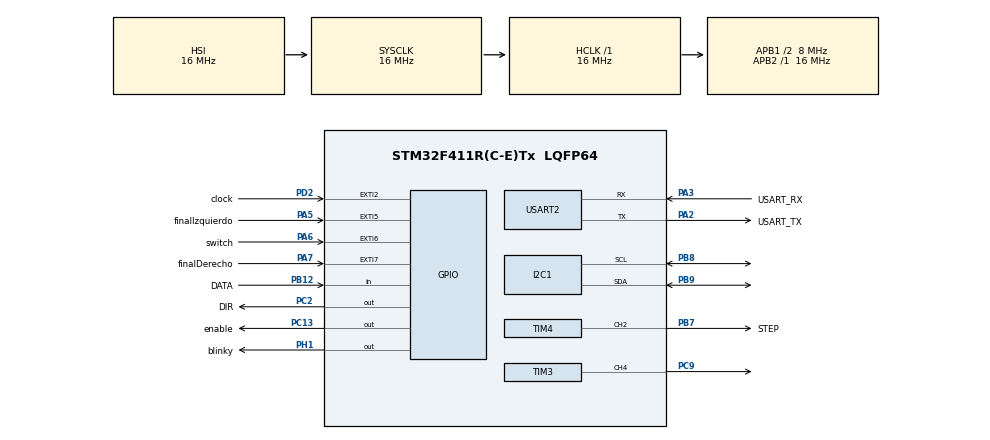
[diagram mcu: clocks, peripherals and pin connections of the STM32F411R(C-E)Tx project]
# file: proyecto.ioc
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I2C1.DutyCycle=I2C_DUTYCYCLE_16_9
I2C1.I2C_Mode=I2C_Fast
Mcu.Family=STM32F4
Mcu.Name=STM32F411R(C-E)Tx
Mcu.Package=LQFP64
NVIC.EXTI2_IRQn=true\:0\:0\:false\:false\:true\:true\:true\:true
NVIC.EXTI9_5_IRQn=true\:0\:0\:false\:false\:true\:true\:true\:true
NVIC.PriorityGroup=NVIC_PRIORITYGROUP_0
NVIC.TIM1_BRK_TIM9_IRQn=true\:0\:0\:false\:false\:true\:true\:true\:true
NVIC.TIM2_IRQn=true\:0\:0\:false\:false\:true\:true\:true\:true
NVIC.TIM3_IRQn=true\:0\:0\:false\:false\:true\:true\:true\:true
NVIC.TIM5_IRQn=true\:0\:0\:false\:false\:true\:true\:true\:true
NVIC.USART2_IRQn=true\:0\:0\:false\:false\:true\:true\:true\:true
PA13.GPIO_Label=TMS
PA13.Mode=Serial_Wire
PA13.Signal=SYS_JTMS-SWDIO
PA14.GPIO_Label=TCK
PA14.Mode=Serial_Wire
PA14.Signal=SYS_JTCK-SWCLK
PA2.GPIO_Label=USART_TX
PA2.Mode=Asynchronous
PA2.Signal=USART2_TX
PA3.GPIO_Label=USART_RX
PA3.Mode=Asynchronous
PA3.Signal=USART2_RX
PA5.GPIO_Label=finalIzquierdo
PA5.Signal=GPXTI5
PA6.GPIO_Label=switch
PA6.Signal=GPXTI6
PA7.GPIO_Label=finalDerecho
PA7.Signal=GPXTI7
PB12.GPIO_Label=DATA
PB12.Signal=GPIO_Input
PB3.GPIO_Label=SWO
PB3.Signal=SYS_JTDO-SWO
PB7.GPIO_Label=STEP
PB7.Signal=S_TIM4_CH2
PB8.Mode=I2C
PB8.Signal=I2C1_SCL
PB9.Mode=I2C
PB9.Signal=I2C1_SDA
PC13-ANTI_TAMP.GPIO_Label=enable
PC13-ANTI_TAMP.Signal=GPIO_Output
PC2.GPIO_Label=DIR
PC2.Signal=GPIO_Output
PC9.Signal=S_TIM3_CH4
PD2.GPIO_Label=clock
PD2.Signal=GPXTI2
PH1\ -\ OSC_OUT.GPIO_Label=blinky
PH1\ -\ OSC_OUT.Signal=GPIO_Output
ProjectManager.HeapSize=0x200
ProjectManager.StackSize=0x400
ProjectManager.TargetToolchain=STM32CubeIDE
RCC.48MHZClocksFreq_Value=84000000
RCC.AHBFreq_Value=16000000
RCC.APB1CLKDivider=RCC_HCLK_DIV2
RCC.APB1Freq_Value=8000000
RCC.APB1TimFreq_Value=16000000
RCC.APB2Freq_Value=16000000
RCC.APB2TimFreq_Value=16000000
RCC.CortexFreq_Value=16000000
RCC.FLatency-AdvancedSettings=FLASH_LATENCY_0
RCC.HCLKFreq_Value=16000000
RCC.HSE_VALUE=8000000
RCC.HSI_VALUE=16000000
RCC.LSE_VALUE=32768
RCC.PLLN=336
RCC.PLLP=RCC_PLLP_DIV4
RCC.SYSCLKFreq_VALUE=16000000
RCC.VCOOutputFreq_Value=336000000
SH.S_TIM3_CH4.0=TIM3_CH4,PWM Generation4 CH4
SH.S_TIM4_CH2.0=TIM4_CH2,PWM Generation2 CH2
TIM10.Period=800
TIM10.Prescaler=16000
TIM2.Period=250-1
TIM2.Prescaler=16000-1
TIM3.Channel-PWM\ Generation4\ CH4=TIM_CHANNEL_4
TIM3.Period=8000
TIM3.Prescaler=10000-1
TIM4.Channel-PWM\ Generation2\ CH2=TIM_CHANNEL_2
TIM4.Period=100
TIM4.Prescaler=1600
TIM4.Pulse-PWM\ Generation2\ CH2=10
TIM5.Period=8000
TIM5.Prescaler=10000-1
TIM9.Period=8000
TIM9.Prescaler=10000-1
USART2.VirtualMode=VM_ASYNC
VP_TIM10_VS_ClockSourceINT.Mode=Enable_Timer
VP_TIM2_VS_ClockSourceINT.Mode=Internal
VP_TIM3_VS_ClockSourceINT.Mode=Internal
VP_TIM4_VS_ClockSourceINT.Mode=Internal
VP_TIM5_VS_ClockSourceINT.Mode=Internal
VP_TIM9_VS_ClockSourceINT.Mode=Internal
board=NUCLEO-F411RE

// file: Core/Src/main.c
/* USER CODE BEGIN Header */
/**
  ******************************************************************************
  * @file           : main.c
  * @brief          : Main program body
  ******************************************************************************
  * @attention
  *
  * Copyright (c) 2025 STMicroelectronics.
  * All rights reserved.
  *
  * This software is licensed under terms that can be found in the LICENSE file
  * in the root directory of this software component.
  * If no LICENSE file comes with this software, it is provided AS-IS.
  *
  ******************************************************************************
  */
/* USER CODE END Header */
#include "main.h"

I2C_HandleTypeDef hi2c1;

TIM_HandleTypeDef htim2;
TIM_HandleTypeDef htim3;
TIM_HandleTypeDef htim4;
TIM_HandleTypeDef htim5;
TIM_HandleTypeDef htim9;
TIM_HandleTypeDef htim10;

UART_HandleTypeDef huart2;

/* USER CODE BEGIN PV */
//Inicializamos la variable a la cual vamos a gurdarle el estado que
//tiene la maquina
estadoActual fsm ={0};

//Variables del posible estado para los finales de carrera
uint8_t estadoIzquierdo =0;
uint8_t estadoDerecho =0;

//Creamos los formatos para las expresiones
//Carita "delado"
const unsigned char delado [] = {
	0xff, 0xff, 0xff, 0xff, 0xff, 0xff, 0xff, 0xff, 0xff, 0xff, 0xff, 0xff, 0xff, 0xff, 0xff, 0xff,
	0xff, 0xff, 0xff, 0xff, 0xff, 0xff, 0xff, 0xff, 0xff, 0xff, 0xff, 0xff, 0xff, 0xff, 0xff, 0xff,
	0xff, 0xff, 0xff, 0xff, 0xff, 0xff, 0xff, 0xff, 0xff, 0xff, 0xff, 0xff, 0xff, 0xff, 0xff, 0xff,
	0xff, 0xff, 0xff, 0xff, 0xff, 0xff, 0xff, 0xff, 0xff, 0xff, 0xff, 0xff, 0xff, 0xff, 0xff, 0xff,
	0xff, 0xff, 0xff, 0xff, 0xff, 0xff, 0xff, 0xff, 0xff, 0xff, 0xff, 0xff, 0xff, 0xff, 0xff, 0xff,
	0xff, 0xff, 0xff, 0xff, 0xff, 0xfe, 0x01, 0xff, 0xf8, 0x03, 0xff, 0xff, 0xff, 0xff, 0xff, 0xff,
	0xff, 0xff, 0xff, 0xff, 0xff, 0xf0, 0xf9, 0xff, 0xfb, 0xf8, 0xff, 0xff, 0xff, 0xff, 0xff, 0xff,
	0xff, 0xff, 0xff, 0xff, 0xff, 0xef, 0xff, 0xff, 0xff, 0xff, 0x7f, 0xff, 0xff, 0xff, 0xff, 0xff,
	0xff, 0xff, 0xff, 0xff, 0xff, 0xdf, 0xff, 0xff, 0xff, 0xff, 0xbf, 0xff, 0xff, 0xff, 0xff, 0xff,
	0xff, 0xff, 0xff, 0xff, 0xff, 0xff, 0xff, 0xff, 0xff, 0xff, 0xff, 0xff, 0xff, 0xff, 0xff, 0xff,
	0xff, 0xff, 0xff, 0xff, 0xff, 0xff, 0xff, 0xff, 0xff, 0xff, 0xff, 0xff, 0xff, 0xff, 0xff, 0xff,
	0xff, 0xff, 0xff, 0xff, 0xff, 0xff, 0xff, 0xff, 0xff, 0xff, 0xff, 0xff, 0xff, 0xff, 0xff, 0xff,
	0xff, 0xff, 0xff, 0xff, 0xff, 0xff, 0xff, 0xff, 0xff, 0xff, 0xff, 0xff, 0xff, 0xff, 0xff, 0xff,
	0xff, 0xff, 0xff, 0xff, 0xff, 0xff, 0xff, 0xff, 0xff, 0xff, 0xff, 0xff, 0xff, 0xff, 0xff, 0xff,
	0xff, 0xff, 0xff, 0xff, 0xff, 0xff, 0xff, 0xff, 0xff, 0xff, 0xff, 0xff, 0xff, 0xff, 0xff, 0xff,
	0xff, 0xff, 0xff, 0xff, 0xff, 0xff, 0xff, 0xff, 0xff, 0xfd, 0xff, 0xff, 0xff, 0xff, 0xff, 0xff,
	0xff, 0xff, 0xff, 0xff, 0xff, 0xef, 0xff, 0xff, 0xff, 0xfe, 0xff, 0xff, 0xff, 0xff, 0xff, 0xff,
	0xff, 0xff, 0xff, 0xff, 0xff, 0xdf, 0xff, 0x7f, 0xff, 0xff, 0x7f, 0xff, 0xff, 0xff, 0xff, 0xff,
	0xff, 0xff, 0xff, 0xff, 0xff, 0x87, 0xff, 0xff, 0xdf, 0xff, 0xbf, 0xff, 0xff, 0xff, 0xff, 0xff,
	0xff, 0xff, 0xff, 0xff, 0xff, 0x81, 0xff, 0xbf, 0x80, 0xff, 0xdf, 0xff, 0xff, 0xff, 0xff, 0xff,
	0xff, 0xff, 0xff, 0xff, 0xff, 0x00, 0xff, 0xff, 0x80, 0x7f, 0xff, 0xff, 0xff, 0xff, 0xff, 0xff,
	0xff, 0xff, 0xff, 0xff, 0xff, 0x07, 0xff, 0xdf, 0x81, 0xff, 0xef, 0xff, 0xff, 0xff, 0xff, 0xff,
	0xff, 0xff, 0xff, 0xff, 0xfe, 0x07, 0x7f, 0xdf, 0x03, 0xff, 0xef, 0xff, 0xff, 0xff, 0xff, 0xff,
	0xff, 0xff, 0xff, 0xff, 0xfe, 0x07, 0x7f, 0xff, 0x03, 0xdf, 0xf7, 0xff, 0xff, 0xff, 0xff, 0xff,
	0xff, 0xff, 0xff, 0xff, 0xfc, 0x02, 0x3f, 0xff, 0x01, 0x9f, 0xf7, 0xff, 0xff, 0xff, 0xff, 0xff,
	0xff, 0xff, 0xff, 0xff, 0xfc, 0x00, 0x3f, 0xff, 0x00, 0x1f, 0xff, 0xff, 0xff, 0xff, 0xff, 0xff,
	0xff, 0xff, 0xff, 0xff, 0xfc, 0x00, 0x3f, 0xef, 0x00, 0x1f, 0xff, 0xff, 0xff, 0xff, 0xff, 0xff,
	0xff, 0xff, 0xff, 0xff, 0xfc, 0x00, 0x3f, 0xff, 0x00, 0x1f, 0xff, 0xff, 0xff, 0xff, 0xff, 0xff,
	0xff, 0xff, 0xff, 0xff, 0xfc, 0x00, 0x3f, 0xff, 0x00, 0x1f, 0xfb, 0xff, 0xff, 0xff, 0xff, 0xff,
	0xff, 0xff, 0xff, 0xff, 0xfc, 0x00, 0x7f, 0xff, 0x00, 0x1f, 0xfb, 0xff, 0xff, 0xff, 0xff, 0xff,
	0xff, 0xff, 0xff, 0xff, 0xfc, 0x00, 0x7f, 0xdf, 0x00, 0x3f, 0xfb, 0xff, 0xff, 0xff, 0xff, 0xff,
	0xff, 0xff, 0xff, 0xff, 0xfc, 0x00, 0xff, 0xdf, 0x00, 0x3f, 0xff, 0xff, 0xff, 0xff, 0xff, 0xff,
	0xff, 0xff, 0xff, 0xff, 0xfc, 0x01, 0xff, 0xdf, 0x80, 0x7f, 0xf7, 0xff, 0xff, 0xff, 0xff, 0xff,
	0xff, 0xff, 0xff, 0xff, 0xfd, 0x83, 0xff, 0xbf, 0x80, 0xff, 0xf7, 0xff, 0xff, 0xff, 0xff, 0xff,
	0xff, 0xff, 0xff, 0xff, 0xfe, 0xff, 0xff, 0xbf, 0xdf, 0xff, 0xf7, 0xff, 0xff, 0xff, 0xff, 0xff,
	0xff, 0xff, 0xff, 0xff, 0xfe, 0xff, 0xff, 0x7f, 0xdf, 0xff, 0xef, 0xff, 0xff, 0xff, 0xff, 0xff,
	0xff, 0xff, 0xff, 0xff, 0xff, 0x7f, 0xff, 0x7f, 0xef, 0xff, 0xef, 0xff, 0xff, 0xff, 0xff, 0xff,
	0xff, 0xff, 0xff, 0xff, 0xff, 0x3f, 0xfe, 0xff, 0xf7, 0xff, 0xdf, 0xff, 0xff, 0xff, 0xff, 0xff,
	0xff, 0xff, 0xff, 0xff, 0xff, 0x9f, 0xf9, 0xff, 0xfb, 0xff, 0xbf, 0xff, 0xff, 0xff, 0xff, 0xff,
	0xff, 0xff, 0xff, 0xff, 0xff, 0xcf, 0xf3, 0xff, 0xfd, 0xff, 0x7f, 0xff, 0xff, 0xff, 0xff, 0xff,
	0xff, 0xff, 0xff, 0xff, 0xff, 0xf1, 0x8f, 0xff, 0xfe, 0x38, 0xff, 0xff, 0xff, 0xff, 0xff, 0xff,
	0xff, 0xff, 0xff, 0xff, 0xff, 0xfe, 0x7f, 0xff, 0xff, 0xc7, 0xff, 0xff, 0xff, 0xff, 0xff, 0xff,
	0xff, 0xff, 0xff, 0xff, 0xff, 0xff, 0xff, 0xff, 0xff, 0xff, 0xff, 0xff, 0xff, 0xff, 0xff, 0xff,
	0xff, 0xff, 0xff, 0xff, 0xff, 0xff, 0x7f, 0xff, 0xff, 0xff, 0xff, 0xff, 0xff, 0xff, 0xff, 0xff,
	0xff, 0xff, 0xff, 0xff, 0xff, 0xff, 0x1f, 0xff, 0xff, 0xff, 0xff, 0xff, 0xff, 0xff, 0xff, 0xff,
	0xff, 0xff, 0xff, 0xff, 0xff, 0xff, 0x77, 0xff, 0xff, 0xff, 0xff, 0xff, 0xff, 0xff, 0xff, 0xff,
	0xff, 0xff, 0xff, 0xff, 0xff, 0xff, 0x7c, 0xff, 0xff, 0xff, 0xff, 0xff, 0xff, 0xff, 0xff, 0xff,
	0xff, 0xff, 0xff, 0xff, 0xff, 0xff, 0xff, 0xc0, 0x40, 0x3f, 0xff, 0xff, 0xff, 0xff, 0xff, 0xff,
	0xff, 0xff, 0xff, 0xff, 0xff, 0xff, 0xbf, 0xff, 0xff, 0xff, 0xff, 0xff, 0xff, 0xff, 0xff, 0xff,
	0xff, 0xff, 0xff, 0xff, 0xff, 0xff, 0xbf, 0xff, 0xff, 0x7f, 0xff, 0xff, 0xff, 0xff, 0xff, 0xff,
	0xff, 0xff, 0xff, 0xff, 0xff, 0xff, 0x8f, 0xff, 0xff, 0xff, 0xff, 0xff, 0xff, 0xff, 0xff, 0xff,
	0xff, 0xff, 0xff, 0xff, 0xff, 0xff, 0xdf, 0xff, 0xfe, 0xff, 0xff, 0xff, 0xff, 0xff, 0xff, 0xff,
	0xff, 0xff, 0xff, 0xff, 0xff, 0xff, 0xdf, 0xff, 0xf9, 0xff, 0xff, 0xff, 0xff, 0xff, 0xff, 0xff,
	0xff, 0xff, 0xff, 0xff, 0xff, 0xff, 0xef, 0xff, 0xfb, 0xff, 0xff, 0xff, 0xff, 0xff, 0xff, 0xff,
	0xff, 0xff, 0xff, 0xff, 0xff, 0xff, 0xff, 0xff, 0xf7, 0xff, 0xff, 0xff, 0xff, 0xff, 0xff, 0xff,
	0xff, 0xff, 0xff, 0xff, 0xff, 0xff, 0xfb, 0xff, 0xef, 0xff, 0xff, 0xff, 0xff, 0xff, 0xff, 0xff,
	0xff, 0xff, 0xff, 0xff, 0xff, 0xff, 0xfd, 0xff, 0xdf, 0xff, 0xff, 0xff, 0xff, 0xff, 0xff, 0xff,
	0xff, 0xff, 0xff, 0xff, 0xff, 0xff, 0xfe, 0x7e, 0x7f, 0xff, 0xff, 0xff, 0xff, 0xff, 0xff, 0xff,
	0xff, 0xff, 0xff, 0xff, 0xff, 0xff, 0xff, 0xe3, 0xff, 0xff, 0xff, 0xff, 0xff, 0xff, 0xff, 0xff,
	0xff, 0xff, 0xff, 0xff, 0xff, 0xff, 0xff, 0xff, 0xff, 0xff, 0xff, 0xff, 0xff, 0xff, 0xff, 0xff,
	0xff, 0xff, 0xff, 0xff, 0xff, 0xff, 0xff, 0xff, 0xff, 0xff, 0xff, 0xff, 0xff, 0xff, 0xff, 0xff,
	0xff, 0xff, 0xff, 0xff, 0xff, 0xff, 0xff, 0xff, 0xff, 0xff, 0xff, 0xff, 0xff, 0xff, 0xff, 0xff,
	0xff, 0xff, 0xff, 0xff, 0xff, 0xff, 0xff, 0xff, 0xff, 0xff, 0xff, 0xff, 0xff, 0xff, 0xff, 0xff,
	0xff, 0xff, 0xff, 0xff, 0xff, 0xff, 0xff, 0xff, 0xff, 0xff, 0xff, 0xff, 0xff, 0xff, 0xff, 0xff
};

//Carita "enamoradisimo"
const unsigned char enamoradisimo [] = {
	0xff, 0xff, 0xff, 0xff, 0xff, 0xff, 0xff, 0xff, 0xff, 0xff, 0xff, 0xff, 0xff, 0xff, 0xff, 0xff,
	0xff, 0xff, 0xff, 0xff, 0xff, 0xff, 0xf8, 0x7f, 0xe1, 0xff, 0xff, 0xff, 0xff, 0xff, 0xff, 0xff,
	0xff, 0xff, 0xff, 0xff, 0xff, 0xff, 0xe0, 0x7f, 0xe0, 0x7f, 0xff, 0xff, 0xff, 0xff, 0xff, 0xff,
	0xff, 0xff, 0xff, 0xff, 0xff, 0xff, 0xc1, 0xff, 0xf8, 0x3f, 0xff, 0xff, 0xff, 0xff, 0xff, 0xff,
	0xff, 0xff, 0xff, 0xff, 0xff, 0xff, 0x87, 0xff, 0xfe, 0x0f, 0xff, 0xff, 0xff, 0xff, 0xff, 0xff,
	0xff, 0xff, 0xff, 0xff, 0xff, 0xfe, 0x1f, 0xff, 0xff, 0x87, 0xff, 0xff, 0xff, 0xff, 0xff, 0xff,
	0xff, 0xff, 0xff, 0xff, 0xff, 0xfc, 0x3f, 0xff, 0xff, 0xc3, 0xff, 0xff, 0xff, 0xff, 0xff, 0xff,
	0xff, 0xff, 0xff, 0xff, 0xff, 0xfc, 0xff, 0xff, 0xff, 0xf3, 0xff, 0xff, 0xff, 0xff, 0xff, 0xff,
	0xff, 0xff, 0xff, 0xff, 0xff, 0xf9, 0xff, 0xff, 0xff, 0xfd, 0xff, 0xff, 0xff, 0xff, 0xff, 0xff,
	0xff, 0xff, 0xff, 0xff, 0xff, 0xf7, 0xff, 0xff, 0xff, 0xfe, 0xff, 0xff, 0xff, 0xff, 0xff, 0xff,
	0xff, 0xff, 0xff, 0xff, 0xff, 0xff, 0xff, 0xff, 0xff, 0xff, 0xff, 0xff, 0xff, 0xff, 0xff, 0xff,
	0xff, 0xff, 0xff, 0xff, 0xff, 0xff, 0xff, 0xff, 0xff, 0xff, 0xff, 0xff, 0xff, 0xff, 0xff, 0xff,
	0xff, 0xff, 0xff, 0xff, 0xff, 0xfc, 0x0f, 0xff, 0xff, 0xff, 0xff, 0xff, 0xff, 0xff, 0xff, 0xff,
	0xff, 0xff, 0xff, 0xff, 0xff, 0xef, 0xfb, 0xff, 0xff, 0xff, 0xff, 0xff, 0xff, 0xff, 0xff, 0xff,
	0xff, 0xff, 0xff, 0xff, 0xff, 0xdf, 0xfe, 0xff, 0xfd, 0xf9, 0xff, 0xff, 0xff, 0xff, 0xff, 0xff,
	0xff, 0xff, 0xff, 0xff, 0xff, 0xff, 0xff, 0x7f, 0xf7, 0xfe, 0xff, 0xff, 0xff, 0xff, 0xff, 0xff,
	0xff, 0xff, 0xff, 0xff, 0xff, 0xff, 0xff, 0xbf, 0xef, 0xff, 0xbf, 0xff, 0xff, 0xff, 0xff, 0xff,
	0xff, 0xff, 0xff, 0xff, 0xfe, 0xff, 0xff, 0xdf, 0xdf, 0xff, 0xff, 0xff, 0xff, 0xff, 0xff, 0xff,
	0xff, 0xff, 0xff, 0xff, 0xff, 0xe1, 0xc3, 0xdf, 0xff, 0xff, 0xff, 0xff, 0xff, 0xff, 0xff, 0xff,
	0xff, 0xff, 0xff, 0xff, 0xfd, 0xc0, 0x81, 0xff, 0xb8, 0x70, 0xef, 0xff, 0xff, 0xff, 0xff, 0xff,
	0xff, 0xff, 0xff, 0xff, 0xff, 0x80, 0x00, 0xef, 0xf0, 0x00, 0x7f, 0xff, 0xff, 0xff, 0xff, 0xff,
	0xff, 0xff, 0xff, 0xff, 0xff, 0x80, 0x00, 0xff, 0x60, 0x00, 0x7f, 0xff, 0xff, 0xff, 0xff, 0xff,
	0xff, 0xff, 0xff, 0xff, 0xfb, 0x80, 0x00, 0xff, 0x60, 0x00, 0x37, 0xff, 0xff, 0xff, 0xff, 0xff,
	0xff, 0xff, 0xff, 0xff, 0xfb, 0x80, 0x00, 0xff, 0xe0, 0x00, 0x77, 0xff, 0xff, 0xff, 0xff, 0xff,
	0xff, 0xff, 0xff, 0xff, 0xfb, 0xc0, 0x01, 0xff, 0xf0, 0x00, 0x77, 0xff, 0xff, 0xff, 0xff, 0xff,
	0xff, 0xff, 0xff, 0xff, 0xff, 0xc0, 0x01, 0xff, 0xf0, 0x00, 0x77, 0xff, 0xff, 0xff, 0xff, 0xff,
	0xff, 0xff, 0xff, 0xff, 0xff, 0xe0, 0x03, 0xef, 0x78, 0x00, 0xff, 0xff, 0xff, 0xff, 0xff, 0xff,
	0xff, 0xff, 0xff, 0xff, 0xfd, 0xf0, 0x03, 0xff, 0x78, 0x00, 0xff, 0xff, 0xff, 0xff, 0xff, 0xff,
	0xff, 0xff, 0xff, 0xff, 0xff, 0xf0, 0x07, 0xff, 0xfc, 0x01, 0xef, 0xff, 0xff, 0xff, 0xff, 0xff,
	0xff, 0xff, 0xff, 0xff, 0xfe, 0xf8, 0x0f, 0xdf, 0xbe, 0x03, 0xff, 0xff, 0xff, 0xff, 0xff, 0xff,
	0xff, 0xff, 0xff, 0xff, 0xff, 0xfe, 0x1f, 0xbf, 0xdf, 0x07, 0xdf, 0xff, 0xff, 0xff, 0xff, 0xff,
	0xff, 0xff, 0xff, 0xff, 0xff, 0xff, 0x7f, 0x7f, 0xef, 0xdf, 0xbf, 0xff, 0xff, 0xff, 0xff, 0xff,
	0xff, 0xff, 0xff, 0xff, 0xff, 0xdf, 0xfe, 0xff, 0xf7, 0xff, 0x7f, 0xff, 0xff, 0xff, 0xff, 0xff,
	0xff, 0xff, 0xff, 0xff, 0xff, 0xe7, 0xfb, 0xff, 0xfd, 0xfd, 0xff, 0xff, 0xff, 0xff, 0xff, 0xff,
	0xff, 0xff, 0xff, 0xff, 0xff, 0xf8, 0x0f, 0xff, 0xff, 0x8f, 0xff, 0xff, 0xff, 0xff, 0xff, 0xff,
	0xff, 0xff, 0xff, 0xff, 0xff, 0xff, 0xff, 0xff, 0xff, 0xff, 0xff, 0xff, 0xff, 0xff, 0xff, 0xff,
	0xff, 0xff, 0xff, 0xff, 0xff, 0xff, 0xff, 0xff, 0xff, 0xfd, 0xff, 0xff, 0xff, 0xff, 0xff, 0xff,
	0xff, 0xff, 0xff, 0xff, 0xff, 0xe7, 0xff, 0xff, 0xff, 0xfe, 0x7f, 0xff, 0xff, 0xff, 0xff, 0xff,
	0xff, 0xff, 0xff, 0xff, 0xff, 0xf3, 0xff, 0xff, 0xff, 0xf9, 0x7f, 0xff, 0xff, 0xff, 0xff, 0xff,
	0xff, 0xff, 0xff, 0xff, 0xff, 0xf8, 0xff, 0xff, 0xff, 0xe3, 0xff, 0xff, 0xff, 0xff, 0xff, 0xff,
	0xff, 0xff, 0xff, 0xff, 0xff, 0xf8, 0x3f, 0xff, 0xff, 0x03, 0xff, 0xff, 0xff, 0xff, 0xff, 0xff,
	0xff, 0xff, 0xff, 0xff, 0xff, 0xfc, 0x1d, 0xff, 0xf7, 0x07, 0xff, 0xff, 0xff, 0xff, 0xff, 0xff,
	0xff, 0xff, 0xff, 0xff, 0xff, 0xfc, 0x0f, 0xff, 0xfe, 0x07, 0xff, 0xff, 0xff, 0xff, 0xff, 0xff,
	0xff, 0xff, 0xff, 0xff, 0xff, 0xfc, 0x03, 0xff, 0xf0, 0x07, 0xff, 0xff, 0xff, 0xff, 0xff, 0xff,
	0xff, 0xff, 0xff, 0xff, 0xff, 0xfe, 0x00, 0x00, 0x00, 0x0f, 0xff, 0xff, 0xff, 0xff, 0xff, 0xff,
	0xff, 0xff, 0xff, 0xff, 0xff, 0xfe, 0x00, 0x00, 0x00, 0x0f, 0xff, 0xff, 0xff, 0xff, 0xff, 0xff,
	0xff, 0xff, 0xff, 0xff, 0xff, 0xfe, 0x00, 0x00, 0x00, 0x0f, 0xff, 0xff, 0xff, 0xff, 0xff, 0xff,
	0xff, 0xff, 0xff, 0xff, 0xff, 0xff, 0x00, 0x00, 0x00, 0x1f, 0xff, 0xff, 0xff, 0xff, 0xff, 0xff,
	0xff, 0xff, 0xff, 0xff, 0xff, 0xff, 0x00, 0x00, 0x00, 0x1f, 0xff, 0xff, 0xff, 0xff, 0xff, 0xff,
	0xff, 0xff, 0xff, 0xff, 0xff, 0xff, 0x00, 0x00, 0x00, 0x1f, 0xff, 0xff, 0xff, 0xff, 0xff, 0xff,
	0xff, 0xff, 0xff, 0xff, 0xff, 0xff, 0x00, 0x00, 0x00, 0x1f, 0xff, 0xff, 0xff, 0xff, 0xff, 0xff,
	0xff, 0xff, 0xff, 0xff, 0xff, 0xff, 0x80, 0x00, 0x00, 0x1f, 0xff, 0xff, 0xff, 0xff, 0xff, 0xff,
	0xff, 0xff, 0xff, 0xff, 0xff, 0xff, 0x80, 0x00, 0x00, 0x3f, 0xff, 0xff, 0xff, 0xff, 0xff, 0xff,
	0xff, 0xff, 0xff, 0xff, 0xff, 0xff, 0x80, 0x00, 0x00, 0x3f, 0xff, 0xff, 0xff, 0xff, 0xff, 0xff,
	0xff, 0xff, 0xff, 0xff, 0xff, 0xff, 0x80, 0x00, 0x00, 0x3f, 0xff, 0xff, 0xff, 0xff, 0xff, 0xff,
	0xff, 0xff, 0xff, 0xff, 0xff, 0xff, 0xe0, 0x00, 0x00, 0xff, 0xff, 0xff, 0xff, 0xff, 0xff, 0xff,
	0xff, 0xff, 0xff, 0xff, 0xff, 0xff, 0xff, 0x00, 0x0f, 0xff, 0xff, 0xff, 0xff, 0xff, 0xff, 0xff,
	0xff, 0xff, 0xff, 0xff, 0xff, 0xff, 0xff, 0xff, 0xff, 0xff, 0xff, 0xff, 0xff, 0xff, 0xff, 0xff,
	0xff, 0xff, 0xff, 0xff, 0xff, 0xff, 0xff, 0xff, 0xff, 0xff, 0xff, 0xff, 0xff, 0xff, 0xff, 0xff,
	0xff, 0xff, 0xff, 0xff, 0xff, 0xff, 0xff, 0xc0, 0x3f, 0xff, 0xff, 0xff, 0xff, 0xff, 0xff, 0xff,
	0xff, 0xff, 0xff, 0xff, 0xff, 0xff, 0xff, 0xff, 0xff, 0xff, 0xff, 0xff, 0xff, 0xff, 0xff, 0xff,
	0xff, 0xff, 0xff, 0xff, 0xff, 0xff, 0xff, 0xff, 0xff, 0xff, 0xff, 0xff, 0xff, 0xff, 0xff, 0xff,
	0xff, 0xff, 0xff, 0xff, 0xff, 0xff, 0xff, 0xff, 0xff, 0xff, 0xff, 0xff, 0xff, 0xff, 0xff, 0xff,
	0xff, 0xff, 0xff, 0xff, 0xff, 0xff, 0xff, 0xff, 0xff, 0xff, 0xff, 0xff, 0xff, 0xff, 0xff, 0xff
};

//Carita "medio-triste"
const unsigned char medioTriste [] = {
	0xff, 0xff, 0xff, 0xff, 0xff, 0xff, 0xff, 0xff, 0xff, 0xff, 0xff, 0xff, 0xff, 0xff, 0xff, 0xff,
	0xff, 0xff, 0xff, 0xff, 0xff, 0xff, 0xff, 0xff, 0xff, 0xff, 0xff, 0xff, 0xff, 0xff, 0xff, 0xff,
	0xff, 0xff, 0xff, 0xff, 0xff, 0xff, 0xff, 0xff, 0xff, 0xff, 0xff, 0xff, 0xff, 0xff, 0xff, 0xff,
	0xff, 0xff, 0xff, 0xff, 0xff, 0xff, 0xff, 0xff, 0xff, 0xff, 0xff, 0xff, 0xff, 0xff, 0xff, 0xff,
	0xff, 0xff, 0xff, 0xff, 0xff, 0xff, 0xff, 0xff, 0xff, 0xff, 0xff, 0xff, 0xff, 0xff, 0xff, 0xff,
	0xff, 0xff, 0xff, 0xff, 0xff, 0xff, 0xff, 0xff, 0xff, 0xff, 0xff, 0xff, 0xff, 0xff, 0xff, 0xff,
	0xff, 0xff, 0xff, 0xff, 0xff, 0xff, 0xff, 0xff, 0xff, 0xff, 0xff, 0xff, 0xff, 0xff, 0xff, 0xff,
	0xff, 0xff, 0xff, 0xff, 0xff, 0xff, 0xff, 0xff, 0xff, 0xff, 0xff, 0xff, 0xff, 0xff, 0xff, 0xff,
	0xff, 0xff, 0xff, 0xff, 0xff, 0xff, 0xff, 0xff, 0xff, 0xff, 0xff, 0xff, 0xff, 0xff, 0xff, 0xff,
	0xff, 0xff, 0xff, 0xff, 0xff, 0xff, 0xff, 0xff, 0xff, 0xff, 0xff, 0xff, 0xff, 0xff, 0xff, 0xff,
	0xff, 0xff, 0xff, 0xff, 0xe0, 0x7f, 0xff, 0xff, 0xff, 0xff, 0xff, 0x07, 0xff, 0xff, 0xff, 0xff,
	0xff, 0xff, 0xff, 0xff, 0x80, 0x1f, 0xff, 0xff, 0xff, 0xff, 0xfc, 0x01, 0xff, 0xff, 0xff, 0xff,
	0xff, 0xff, 0xff, 0xff, 0x00, 0x0f, 0xff, 0xff, 0xff, 0xff, 0xf0, 0x00, 0xff, 0xff, 0xff, 0xff,
	0xff, 0xff, 0xff, 0xfe, 0x00, 0x07, 0xff, 0xff, 0xff, 0xff, 0xe0, 0x00, 0x3f, 0xff, 0xff, 0xff,
	0xff, 0xff, 0xff, 0xfc, 0x00, 0x03, 0xff, 0xff, 0xff, 0xff, 0xc0, 0x00, 0x3f, 0xff, 0xff, 0xff,
	0xff, 0xff, 0xff, 0xf8, 0x00, 0x01, 0xff, 0xff, 0xff, 0xff, 0xc0, 0x00, 0x1f, 0xff, 0xff, 0xff,
	0xff, 0xff, 0xff, 0xf8, 0x00, 0xc1, 0xff, 0xff, 0xff, 0xff, 0x83, 0x00, 0x0f, 0xff, 0xff, 0xff,
	0xff, 0xff, 0xff, 0xf0, 0x03, 0xf0, 0xff, 0xff, 0xff, 0xff, 0x8f, 0xc0, 0x0f, 0xff, 0xff, 0xff,
	0xff, 0xff, 0xff, 0xf0, 0x07, 0xf8, 0xff, 0xff, 0xff, 0xff, 0x1f, 0xe0, 0x0f, 0xff, 0xff, 0xff,
	0xff, 0xff, 0xff, 0xf0, 0x07, 0xf8, 0xff, 0xff, 0xff, 0xff, 0x1f, 0xe0, 0x07, 0xff, 0xff, 0xff,
	0xff, 0xff, 0xff, 0xe0, 0x0f, 0xfc, 0xff, 0xff, 0xff, 0xff, 0x3f, 0xf0, 0x07, 0xff, 0xff, 0xff,
	0xff, 0xff, 0xff, 0xe0, 0x0f, 0xfc, 0x7f, 0xff, 0xff, 0xff, 0x3f, 0xf0, 0x07, 0xff, 0xff, 0xff,
	0xff, 0xff, 0xff, 0xe0, 0x0f, 0xfc, 0x7f, 0xff, 0xff, 0xff, 0x3f, 0xf0, 0x07, 0xff, 0xff, 0xff,
	0xff, 0xff, 0xff, 0xe0, 0x0f, 0xfc, 0x7f, 0xff, 0xff, 0xff, 0x3f, 0xf0, 0x07, 0xff, 0xff, 0xff,
	0xff, 0xff, 0xff, 0xe0, 0x07, 0xfc, 0x7f, 0xff, 0xff, 0xff, 0x1f, 0xe0, 0x07, 0xff, 0xff, 0xff,
	0xff, 0xff, 0xff, 0xe0, 0x07, 0xf8, 0xff, 0xff, 0xff, 0xff, 0x1f, 0xe0, 0x07, 0xff, 0xff, 0xff,
	0xff, 0xff, 0xff, 0xf0, 0x03, 0xf0, 0xff, 0xff, 0xff, 0xff, 0x0f, 0xc0, 0x07, 0xff, 0xff, 0xff,
	0xff, 0xff, 0xff, 0xf0, 0x00, 0xc0, 0xff, 0xff, 0xff, 0xff, 0x03, 0x00, 0x0f, 0xff, 0xff, 0xff,
	0xff, 0xff, 0xff, 0xf0, 0x00, 0x00, 0xff, 0xff, 0xff, 0xff, 0x80, 0x00, 0x0f, 0xff, 0xff, 0xff,
	0xff, 0xff, 0xff, 0xf8, 0x00, 0x01, 0xff, 0xff, 0xff, 0xff, 0x80, 0x00, 0x0f, 0xff, 0xff, 0xff,
	0xff, 0xff, 0xff, 0xf8, 0x00, 0x01, 0xff, 0xff, 0xff, 0xff, 0xc0, 0x00, 0x1f, 0xff, 0xff, 0xff,
	0xff, 0xff, 0xff, 0xfc, 0x00, 0x03, 0xff, 0xff, 0xff, 0xff, 0xc0, 0x00, 0x1f, 0xff, 0xff, 0xff,
	0xff, 0xff, 0xff, 0xfe, 0x00, 0x07, 0xff, 0xff, 0xff, 0xff, 0xe0, 0x00, 0x3f, 0xff, 0xff, 0xff,
	0xff, 0xff, 0xff, 0xff, 0x00, 0x0f, 0xff, 0xff, 0xff, 0xff, 0xf0, 0x00, 0x7f, 0xff, 0xff, 0xff,
	0xff, 0xff, 0xff, 0xff, 0x80, 0x1f, 0xff, 0xff, 0xff, 0xff, 0xf8, 0x01, 0xff, 0xff, 0xff, 0xff,
	0xff, 0xff, 0xff, 0xff, 0xe0, 0x7f, 0xff, 0xff, 0xff, 0xff, 0xfe, 0x07, 0xff, 0xff, 0xff, 0xff,
	0xff, 0xff, 0xff, 0xff, 0xff, 0xff, 0xff, 0xff, 0xff, 0xff, 0xff, 0xff, 0xff, 0xff, 0xff, 0xff,
	0xff, 0xff, 0xff, 0xff, 0xff, 0xff, 0xff, 0xff, 0xff, 0xff, 0xff, 0xff, 0xff, 0xff, 0xff, 0xff,
	0xff, 0xff, 0xff, 0xff, 0xff, 0xff, 0xff, 0xff, 0xff, 0xff, 0xff, 0xff, 0xff, 0xff, 0xff, 0xff,
	0xff, 0xff, 0xff, 0xff, 0xff, 0xff, 0xff, 0xff, 0xff, 0xff, 0xff, 0xff, 0xff, 0xff, 0xff, 0xff,
	0xff, 0xff, 0xff, 0xff, 0xff, 0xff, 0xff, 0xff, 0xff, 0xff, 0xff, 0xff, 0xff, 0xff, 0xff, 0xff,
	0xff, 0xff, 0xff, 0xff, 0xff, 0xff, 0xff, 0xff, 0xff, 0xff, 0xff, 0xff, 0xff, 0xff, 0xff, 0xff,
	0xff, 0xff, 0xff, 0xff, 0xff, 0xff, 0xff, 0xf8, 0x3f, 0xff, 0xff, 0xff, 0xff, 0xff, 0xff, 0xff,
	0xff, 0xff, 0xff, 0xff, 0xff, 0xff, 0xff, 0xc0, 0x07, 0xff, 0xff, 0xff, 0xff, 0xff, 0xff, 0xff,
	0xff, 0xff, 0xff, 0xff, 0xff, 0xff, 0xff, 0x80, 0x03, 0xff, 0xff, 0xff, 0xff, 0xff, 0xff, 0xff,
	0xff, 0xff, 0xff, 0xff, 0xff, 0xff, 0xff, 0x03, 0x81, 0xff, 0xff, 0xff, 0xff, 0xff, 0xff, 0xff,
	0xff, 0xff, 0xff, 0xff, 0xff, 0xff, 0xfe, 0x1f, 0xf0, 0xff, 0xff, 0xff, 0xff, 0xff, 0xff, 0xff,
	0xff, 0xff, 0xff, 0xff, 0xff, 0xff, 0xfc, 0x3f, 0xf8, 0x7f, 0xff, 0xff, 0xff, 0xff, 0xff, 0xff,
	0xff, 0xff, 0xff, 0xff, 0xff, 0xff, 0xfc, 0x7f, 0xfc, 0x3f, 0xff, 0xff, 0xff, 0xff, 0xff, 0xff,
	0xff, 0xff, 0xff, 0xff, 0xff, 0xff, 0xfc, 0xff, 0xfe, 0x3f, 0xff, 0xff, 0xff, 0xff, 0xff, 0xff,
	0xff, 0xff, 0xff, 0xff, 0xff, 0xff, 0xff, 0xff, 0xff, 0x7f, 0xff, 0xff, 0xff, 0xff, 0xff, 0xff,
	0xff, 0xff, 0xff, 0xff, 0xff, 0xff, 0xff, 0xff, 0xff, 0xff, 0xff, 0xff, 0xff, 0xff, 0xff, 0xff,
	0xff, 0xff, 0xff, 0xff, 0xff, 0xff, 0xff, 0xff, 0xff, 0xff, 0xff, 0xff, 0xff, 0xff, 0xff, 0xff,
	0xff, 0xff, 0xff, 0xff, 0xff, 0xff, 0xff, 0xff, 0xff, 0xff, 0xff, 0xff, 0xff, 0xff, 0xff, 0xff,
	0xff, 0xff, 0xff, 0xff, 0xff, 0xff, 0xff, 0xff, 0xff, 0xff, 0xff, 0xff, 0xff, 0xff, 0xff, 0xff,
	0xff, 0xff, 0xff, 0xff, 0xff, 0xff, 0xff, 0xff, 0xff, 0xff, 0xff, 0xff, 0xff, 0xff, 0xff, 0xff,
	0xff, 0xff, 0xff, 0xff, 0xff, 0xff, 0xff, 0xff, 0xff, 0xff, 0xff, 0xff, 0xff, 0xff, 0xff, 0xff,
	0xff, 0xff, 0xff, 0xff, 0xff, 0xff, 0xff, 0xff, 0xff, 0xff, 0xff, 0xff, 0xff, 0xff, 0xff, 0xff,
	0xff, 0xff, 0xff, 0xff, 0xff, 0xff, 0xff, 0xff, 0xff, 0xff, 0xff, 0xff, 0xff, 0xff, 0xff, 0xff,
	0xff, 0xff, 0xff, 0xff, 0xff, 0xff, 0xff, 0xff, 0xff, 0xff, 0xff, 0xff, 0xff, 0xff, 0xff, 0xff,
	0xff, 0xff, 0xff, 0xff, 0xff, 0xff, 0xff, 0xff, 0xff, 0xff, 0xff, 0xff, 0xff, 0xff, 0xff, 0xff,
	0xff, 0xff, 0xff, 0xff, 0xff, 0xff, 0xff, 0xff, 0xff, 0xff, 0xff, 0xff, 0xff, 0xff, 0xff, 0xff,
	0xff, 0xff, 0xff, 0xff, 0xff, 0xff, 0xff, 0xff, 0xff, 0xff, 0xff, 0xff, 0xff, 0xff, 0xff, 0xff,
	0xff, 0xff, 0xff, 0xff, 0xff, 0xff, 0xff, 0xff, 0xff, 0xff, 0xff, 0xff, 0xff, 0xff, 0xff, 0xff
};

// cara "enamoradito"
const unsigned char enamoradito []= {
	0xff, 0xff, 0xff, 0xff, 0xff, 0xff, 0xff, 0xff, 0xff, 0xff, 0xff, 0xff, 0xff, 0xff, 0xff, 0xff,
	0xff, 0xff, 0xff, 0xff, 0xff, 0xff, 0xff, 0xff, 0xff, 0xff, 0xfd, 0xfc, 0xff, 0xff, 0xff, 0xff,
	0xff, 0xff, 0xff, 0xff, 0xff, 0xff, 0xff, 0xff, 0xff, 0xff, 0xf0, 0x70, 0x3f, 0xff, 0xff, 0xff,
	0xff, 0xff, 0xff, 0xff, 0xff, 0xff, 0xff, 0xff, 0xff, 0xff, 0xe0, 0x00, 0x1f, 0xff, 0xff, 0xff,
	0xff, 0xff, 0xff, 0xff, 0xff, 0xff, 0xff, 0xff, 0xff, 0xff, 0xc0, 0x00, 0x1f, 0xff, 0xff, 0xff,
	0xff, 0xff, 0xff, 0xff, 0xff, 0xff, 0xff, 0xff, 0xff, 0xff, 0xc0, 0x00, 0x1f, 0xff, 0xff, 0xff,
	0xff, 0xff, 0xff, 0xff, 0xff, 0xff, 0xff, 0xff, 0xff, 0xff, 0xc0, 0x00, 0x1f, 0xff, 0xff, 0xff,
	0xff, 0xff, 0xff, 0xff, 0xff, 0xff, 0xff, 0xff, 0xff, 0xff, 0xe0, 0x00, 0x1f, 0xff, 0xff, 0xff,
	0xff, 0xff, 0xff, 0xff, 0xff, 0xff, 0x07, 0xff, 0xfc, 0x1f, 0xe0, 0x00, 0x1f, 0xff, 0xff, 0xff,
	0xff, 0xff, 0xff, 0xff, 0xff, 0xfe, 0x07, 0xff, 0xfc, 0x07, 0xe0, 0x00, 0x3f, 0xff, 0xff, 0xff,
	0xff, 0xff, 0xff, 0xff, 0xff, 0xfc, 0x1f, 0xff, 0xff, 0x83, 0xf0, 0x00, 0x3f, 0xff, 0xff, 0xff,
	0xff, 0xff, 0xff, 0xff, 0xff, 0xf8, 0x7f, 0xff, 0xff, 0xe1, 0xf0, 0x00, 0x7f, 0xff, 0xff, 0xff,
	0xff, 0xff, 0xff, 0xff, 0xff, 0xf1, 0xff, 0xff, 0xff, 0xf8, 0xf8, 0x00, 0x7f, 0xff, 0xff, 0xff,
	0xff, 0xff, 0xff, 0xff, 0xff, 0xe7, 0xff, 0xff, 0xff, 0xfe, 0x7c, 0x00, 0x03, 0xff, 0xff, 0xff,
	0xff, 0xff, 0xff, 0xff, 0xff, 0xdf, 0xff, 0xff, 0xff, 0xff, 0xbe, 0x00, 0x01, 0xff, 0xff, 0xff,
	0xff, 0xff, 0xff, 0xff, 0xff, 0xff, 0xff, 0xff, 0xff, 0xff, 0xff, 0x00, 0x01, 0xff, 0xff, 0xff,
	0xff, 0xff, 0xff, 0xff, 0xff, 0xff, 0xff, 0xff, 0xff, 0xff, 0xff, 0xc0, 0x01, 0xff, 0xff, 0xff,
	0xff, 0xff, 0xff, 0xff, 0xff, 0xff, 0xff, 0xff, 0xff, 0xff, 0xff, 0xe0, 0x03, 0xff, 0xff, 0xff,
	0xff, 0xff, 0xff, 0xff, 0xff, 0xe0, 0xe7, 0xff, 0xff, 0xff, 0xff, 0xf0, 0x07, 0xff, 0xff, 0xff,
	0xff, 0xff, 0xff, 0xff, 0xff, 0x88, 0x79, 0xff, 0xff, 0xc1, 0xff, 0xf0, 0x0f, 0xff, 0xff, 0xff,
	0xff, 0xff, 0xff, 0xff, 0xfe, 0x98, 0x3e, 0xff, 0xfe, 0x78, 0x3f, 0xf8, 0x1f, 0xff, 0xff, 0xff,
	0xff, 0xff, 0xff, 0xff, 0xfd, 0x98, 0x3f, 0x7f, 0xfd, 0xf0, 0x9f, 0xf8, 0x7f, 0xff, 0xff, 0xff,
	0xff, 0xff, 0xff, 0xff, 0xfb, 0x80, 0x3f, 0xbf, 0xf7, 0xe1, 0xd7, 0xfd, 0xff, 0xff, 0xff, 0xff,
	0xff, 0xff, 0xff, 0xff, 0xff, 0x80, 0x3f, 0xdf, 0xef, 0xe0, 0x1b, 0xff, 0xff, 0xff, 0xff, 0xff,
	0xff, 0xff, 0xff, 0xff, 0xf7, 0xc0, 0x3f, 0xdf, 0xff, 0xe0, 0x1f, 0xff, 0xff, 0xff, 0xff, 0xff,
	0xff, 0xff, 0xff, 0xff, 0xff, 0xc0, 0x7f, 0xef, 0xdf, 0xe0, 0x1d, 0xff, 0xff, 0xff, 0xff, 0xff,
	0xff, 0xff, 0xff, 0xff, 0xef, 0xf0, 0xff, 0xef, 0xff, 0xe0, 0x3f, 0xff, 0xff, 0xff, 0xff, 0xff,
	0xff, 0xff, 0xff, 0xff, 0xef, 0xff, 0xff, 0xef, 0xbf, 0xf0, 0x7e, 0xff, 0xff, 0xff, 0xff, 0xff,
	0xff, 0xff, 0xff, 0xff, 0xff, 0xff, 0xff, 0xff, 0xff, 0xff, 0xfe, 0xff, 0xff, 0xff, 0xff, 0xff,
	0xff, 0xff, 0xff, 0xff, 0xff, 0xff, 0xff, 0xf7, 0xff, 0xff, 0xff, 0xff, 0xff, 0xff, 0xff, 0xff,
	0xff, 0xff, 0xff, 0xff, 0xff, 0xff, 0xff, 0xf7, 0xff, 0xff, 0xff, 0xff, 0xff, 0xff, 0xff, 0xff,
	0xff, 0xff, 0xff, 0xff, 0xff, 0xff, 0xff, 0xf7, 0xff, 0xff, 0xff, 0xff, 0xff, 0xff, 0xff, 0xff,
	0xff, 0xff, 0xff, 0xff, 0xff, 0xff, 0xff, 0xff, 0xff, 0xff, 0xff, 0xff, 0xff, 0xff, 0xff, 0xff,
	0xff, 0xff, 0xff, 0xff, 0xef, 0xff, 0xff, 0xef, 0xff, 0xff, 0xfe, 0xff, 0xff, 0xff, 0xff, 0xff,
	0xff, 0xff, 0xff, 0xff, 0xef, 0xff, 0xff, 0xef, 0xbf, 0xff, 0xfe, 0xff, 0xff, 0xff, 0xff, 0xff,
	0xff, 0xff, 0xff, 0xff, 0xff, 0xff, 0xff, 0xff, 0xbf, 0xff, 0xff, 0xff, 0xff, 0xff, 0xff, 0xff,
	0xff, 0xff, 0xff, 0xff, 0xf7, 0xff, 0xff, 0xdf, 0xdf, 0xff, 0xfd, 0xff, 0xff, 0xff, 0xff, 0xff,
	0xff, 0xff, 0xff, 0xff, 0xfb, 0xff, 0xff, 0xff, 0xdf, 0xff, 0xff, 0xff, 0xff, 0xff, 0xff, 0xff,
	0xff, 0xff, 0xff, 0xff, 0xfb, 0xff, 0xff, 0xbf, 0xef, 0xff, 0xfb, 0xff, 0xff, 0xff, 0xff, 0xff,
	0xff, 0xff, 0xff, 0xff, 0xfd, 0xff, 0xff, 0x7f, 0xf7, 0xff, 0xf7, 0xff, 0xff, 0xff, 0xff, 0xff,
	0xff, 0xff, 0xff, 0xff, 0xfe, 0x7f, 0xfe, 0xff, 0xfb, 0xff, 0xef, 0xff, 0xff, 0xff, 0xff, 0xff,
	0xff, 0xff, 0xff, 0xff, 0xff, 0xbf, 0xfb, 0xff, 0xfe, 0xff, 0xbf, 0xff, 0xff, 0xff, 0xff, 0xff,
	0xff, 0xff, 0xff, 0xff, 0xff, 0xe7, 0xcf, 0xff, 0xff, 0x80, 0xff, 0xff, 0xff, 0xff, 0xff, 0xff,
	0xff, 0xff, 0xff, 0xff, 0xff, 0xff, 0xff, 0xff, 0xff, 0xff, 0xff, 0xff, 0xff, 0xff, 0xff, 0xff,
	0xff, 0xff, 0xff, 0xff, 0xff, 0xff, 0xff, 0xff, 0xff, 0xff, 0xff, 0xff, 0xff, 0xff, 0xff, 0xff,
	0xff, 0xff, 0xff, 0xff, 0xff, 0xff, 0xff, 0xff, 0xff, 0xff, 0xff, 0xff, 0xff, 0xff, 0xff, 0xff,
	0xff, 0xff, 0xff, 0xff, 0xff, 0xff, 0xff, 0xff, 0xf9, 0xff, 0xff, 0xff, 0xff, 0xff, 0xff, 0xff,
	0xff, 0xff, 0xff, 0xff, 0xff, 0xff, 0xe3, 0xff, 0xfc, 0x7f, 0xff, 0xff, 0xff, 0xff, 0xff, 0xff,
	0xff, 0xff, 0xff, 0xff, 0xff, 0xff, 0xfb, 0xff, 0xfd, 0xff, 0xff, 0xff, 0xff, 0xff, 0xff, 0xff,
	0xff, 0xff, 0xff, 0xff, 0xff, 0xff, 0xfb, 0xff, 0xfd, 0xff, 0xff, 0xff, 0xff, 0xff, 0xff, 0xff,
	0xff, 0xff, 0xff, 0xff, 0xff, 0xff, 0xfb, 0xff, 0xfd, 0xff, 0xff, 0xff, 0xff, 0xff, 0xff, 0xff,
	0xff, 0xff, 0xff, 0xff, 0xff, 0xff, 0xf9, 0xff, 0xfd, 0xff, 0xff, 0xff, 0xff, 0xff, 0xff, 0xff,
	0xff, 0xff, 0xff, 0xff, 0xff, 0xff, 0xf9, 0xff, 0xf9, 0xff, 0xff, 0xff, 0xff, 0xff, 0xff, 0xff,
	0xff, 0xff, 0xff, 0xff, 0xff, 0xff, 0xfd, 0xff, 0xfb, 0xff, 0xff, 0xff, 0xff, 0xff, 0xff, 0xff,
	0xff, 0xff, 0xff, 0xff, 0xff, 0xff, 0xfc, 0xff, 0xf3, 0xff, 0xff, 0xff, 0xff, 0xff, 0xff, 0xff,
	0xff, 0xff, 0xff, 0xff, 0xff, 0xff, 0xfe, 0x7f, 0xe7, 0xff, 0xff, 0xff, 0xff, 0xff, 0xff, 0xff,
	0xff, 0xff, 0xff, 0xff, 0xff, 0xff, 0xfe, 0x3f, 0xc7, 0xff, 0xff, 0xff, 0xff, 0xff, 0xff, 0xff,
	0xff, 0xff, 0xff, 0xff, 0xff, 0xff, 0xff, 0x80, 0x1f, 0xff, 0xff, 0xff, 0xff, 0xff, 0xff, 0xff,
	0xff, 0xff, 0xff, 0xff, 0xff, 0xff, 0xff, 0xe0, 0x7f, 0xff, 0xff, 0xff, 0xff, 0xff, 0xff, 0xff,
	0xff, 0xff, 0xff, 0xff, 0xff, 0xff, 0xff, 0xff, 0xff, 0xff, 0xff, 0xff, 0xff, 0xff, 0xff, 0xff,
	0xff, 0xff, 0xff, 0xff, 0xff, 0xff, 0xff, 0xff, 0xff, 0xff, 0xff, 0xff, 0xff, 0xff, 0xff, 0xff,
	0xff, 0xff, 0xff, 0xff, 0xff, 0xff, 0xff, 0xff, 0xff, 0xff, 0xff, 0xff, 0xff, 0xff, 0xff, 0xff,
	0xff, 0xff, 0xff, 0xff, 0xff, 0xff, 0xff, 0xff, 0xff, 0xff, 0xff, 0xff, 0xff, 0xff, 0xff, 0xff,
	0xff, 0xff, 0xff, 0xff, 0xff, 0xff, 0xff, 0xff, 0xff, 0xff, 0xff, 0xff, 0xff, 0xff, 0xff, 0xff
};

// 'bravo', 128x64px
const unsigned char bravo [] = {
	0xff, 0xff, 0xff, 0xff, 0xff, 0xff, 0xff, 0xff, 0xff, 0xff, 0xff, 0xff, 0xff, 0xff, 0xff, 0xff,
	0xff, 0xff, 0xff, 0xff, 0xff, 0xff, 0xff, 0xff, 0xff, 0xff, 0xff, 0xff, 0xff, 0xff, 0xff, 0xff,
	0xff, 0xff, 0xff, 0xff, 0xff, 0xff, 0xff, 0xff, 0xff, 0xff, 0xff, 0xff, 0xff, 0xff, 0xff, 0xff,
	0xff, 0xff, 0xff, 0xff, 0xff, 0xff, 0xff, 0xff, 0xff, 0xff, 0xff, 0xff, 0xff, 0xff, 0xff, 0xff,
	0xff, 0xff, 0xff, 0xff, 0xff, 0xff, 0xff, 0xff, 0xff, 0xff, 0xff, 0xff, 0xff, 0xff, 0xff, 0xff,
	0xff, 0xff, 0xff, 0xff, 0xff, 0xff, 0xff, 0xff, 0xff, 0xf0, 0xff, 0xff, 0xff, 0xff, 0xff, 0xff,
	0xff, 0xff, 0xff, 0xff, 0xff, 0x1f, 0xff, 0xff, 0xff, 0xc0, 0x3f, 0xff, 0xff, 0xff, 0xff, 0xff,
	0xff, 0xff, 0xff, 0xff, 0xfc, 0x07, 0xff, 0xff, 0xff, 0x00, 0x1f, 0xff, 0xff, 0xff, 0xff, 0xff,
	0xff, 0xff, 0xff, 0xff, 0xf8, 0x03, 0xff, 0xff, 0xfe, 0x00, 0x1f, 0xff, 0xff, 0xff, 0xff, 0xff,
	0xff, 0xff, 0xff, 0xff, 0xf0, 0x01, 0xff, 0xff, 0xfc, 0x00, 0x0f, 0xff, 0xff, 0xff, 0xff, 0xff,
	0xff, 0xff, 0xff, 0xff, 0xe0, 0x00, 0xff, 0xff, 0xf0, 0x00, 0x0f, 0xff, 0xff, 0xff, 0xff, 0xff,
	0xff, 0xff, 0xff, 0xff, 0xff, 0x00, 0xff, 0xff, 0xf0, 0x00, 0x0f, 0xff, 0xff, 0xff, 0xff, 0xff,
	0xff, 0xff, 0xff, 0xff, 0xff, 0x80, 0x7f, 0xff, 0xe0, 0x00, 0x07, 0xff, 0xff, 0xff, 0xff, 0xff,
	0xff, 0xff, 0xff, 0xff, 0xff, 0xe0, 0x3f, 0xff, 0xc0, 0x1c, 0x07, 0xff, 0xff, 0xff, 0xff, 0xff,
	0xff, 0xff, 0xff, 0xff, 0xff, 0xf0, 0x3f, 0xff, 0x83, 0xff, 0xc7, 0xff, 0xff, 0xff, 0xff, 0xff,
	0xff, 0xff, 0xff, 0xff, 0xff, 0xf8, 0x1f, 0xff, 0x0f, 0xff, 0xff, 0xff, 0xff, 0xff, 0xff, 0xff,
	0xff, 0xff, 0xff, 0xff, 0xff, 0xf8, 0x1f, 0xfe, 0x3f, 0xff, 0xff, 0xff, 0xff, 0xff, 0xff, 0xff,
	0xff, 0xff, 0xff, 0xff, 0xff, 0xfc, 0x1f, 0xfe, 0x7f, 0xc3, 0xff, 0xff, 0xff, 0xff, 0xff, 0xff,
	0xff, 0xff, 0xff, 0xff, 0xff, 0xfe, 0x0f, 0xfc, 0xff, 0x81, 0xff, 0xff, 0xff, 0xff, 0xff, 0xff,
	0xff, 0xff, 0xff, 0xff, 0xff, 0xf1, 0x0f, 0xff, 0xff, 0x03, 0xff, 0xff, 0xff, 0xff, 0xff, 0xff,
	0xff, 0xff, 0xff, 0xff, 0xff, 0xc0, 0x0f, 0xff, 0xff, 0x07, 0x7f, 0xff, 0xff, 0xff, 0xff, 0xff,
	0xff, 0xff, 0xff, 0xff, 0xff, 0xcc, 0x07, 0xff, 0xfe, 0x07, 0x7f, 0xff, 0xff, 0xff, 0xff, 0xff,
	0xff, 0xff, 0xff, 0xff, 0xff, 0x8c, 0x07, 0xff, 0xfe, 0x07, 0x7f, 0xff, 0xff, 0xff, 0xff, 0xff,
	0xff, 0xff, 0xff, 0xff, 0xff, 0x9c, 0x07, 0xff, 0xfe, 0x03, 0x3f, 0xff, 0xff, 0xff, 0xff, 0xff,
	0xff, 0xff, 0xff, 0xff, 0xff, 0x1c, 0x07, 0xff, 0xfe, 0x00, 0x3f, 0xff, 0xff, 0xff, 0xff, 0xff,
	0xff, 0xff, 0xff, 0xff, 0xff, 0x1c, 0x07, 0xff, 0xfe, 0x00, 0x3f, 0xff, 0xff, 0xff, 0xff, 0xff,
	0xff, 0xff, 0xff, 0xff, 0xff, 0x08, 0x07, 0xff, 0xfe, 0x00, 0x3f, 0xff, 0xff, 0xff, 0xff, 0xff,
	0xff, 0xff, 0xff, 0xff, 0xff, 0x00, 0x07, 0xff, 0xfe, 0x00, 0x3f, 0xff, 0xff, 0xff, 0xff, 0xff,
	0xff, 0xff, 0xff, 0xff, 0xff, 0x00, 0x07, 0xff, 0xfe, 0x00, 0x3f, 0xff, 0xff, 0xff, 0xff, 0xff,
	0xff, 0xff, 0xff, 0xff, 0xff, 0x00, 0x0f, 0xff, 0xff, 0x00, 0x77, 0xff, 0xff, 0xff, 0xff, 0xff,
	0xff, 0xff, 0xff, 0xff, 0xff, 0x00, 0x0f, 0xff, 0xff, 0x00, 0x3f, 0xff, 0xff, 0xff, 0xff, 0xff,
	0xff, 0xff, 0xff, 0xff, 0xff, 0x00, 0x0f, 0xff, 0xff, 0x81, 0xff, 0xff, 0xff, 0xff, 0xff, 0xff,
	0xff, 0xff, 0xff, 0xff, 0xff, 0x80, 0x1f, 0xff, 0xff, 0xe7, 0xff, 0xff, 0xff, 0xff, 0xff, 0xff,
	0xff, 0xff, 0xff, 0xff, 0xff, 0x8f, 0xff, 0xff, 0xff, 0xff, 0xff, 0xff, 0xff, 0xff, 0xff, 0xff,
	0xff, 0xff, 0xff, 0xff, 0xff, 0xbf, 0xff, 0xff, 0xff, 0xff, 0xff, 0xff, 0xff, 0xff, 0xff, 0xff,
	0xff, 0xff, 0xff, 0xff, 0xfe, 0xff, 0xff, 0xff, 0xff, 0xff, 0xff, 0xff, 0xff, 0xff, 0xff, 0xff,
	0xff, 0xff, 0xff, 0xff, 0xfb, 0xff, 0xff, 0xff, 0xff, 0xff, 0xff, 0xff, 0xff, 0xff, 0xff, 0xff,
	0xff, 0xff, 0xff, 0xff, 0xff, 0xff, 0xff, 0xff, 0xff, 0xfc, 0x1f, 0xff, 0xff, 0xff, 0xff, 0xff,
	0xff, 0xff, 0xff, 0xff, 0xff, 0xff, 0xff, 0xff, 0xff, 0xe7, 0xf7, 0xff, 0xff, 0xff, 0xff, 0xff,
	0xff, 0xff, 0xff, 0xff, 0xff, 0xff, 0xff, 0xff, 0xff, 0x3f, 0xf7, 0xff, 0xff, 0xff, 0xff, 0xff,
	0xff, 0xff, 0xff, 0xff, 0xff, 0xff, 0xff, 0xff, 0xfd, 0xff, 0xfb, 0xff, 0xff, 0xff, 0xff, 0xff,
	0xff, 0xff, 0xff, 0xff, 0xff, 0xff, 0xff, 0xff, 0xf7, 0xff, 0xfb, 0xff, 0xff, 0xff, 0xff, 0xff,
	0xff, 0xff, 0xff, 0xff, 0xff, 0xff, 0xff, 0xff, 0xdf, 0xff, 0xfb, 0xff, 0xff, 0xff, 0xff, 0xff,
	0xff, 0xff, 0xff, 0xff, 0xff, 0xff, 0xff, 0xff, 0x7f, 0xff, 0xf9, 0xff, 0xff, 0xff, 0xff, 0xff,
	0xff, 0xff, 0xff, 0xff, 0xfb, 0xff, 0xff, 0xfc, 0xff, 0xff, 0xf1, 0xff, 0xff, 0xff, 0xff, 0xff,
	0xff, 0xff, 0xff, 0xff, 0xfe, 0xff, 0xff, 0xf3, 0xff, 0xff, 0xe1, 0xff, 0xff, 0xff, 0xff, 0xff,
	0xff, 0xff, 0xff, 0xff, 0xef, 0xff, 0xff, 0xcf, 0xff, 0xff, 0x91, 0xff, 0xff, 0xff, 0xff, 0xff,
	0xff, 0xff, 0xff, 0xff, 0xef, 0xff, 0xff, 0xbf, 0xff, 0xfc, 0x79, 0xff, 0xff, 0xff, 0xff, 0xff,
	0xff, 0xff, 0xff, 0xff, 0xef, 0xff, 0xfe, 0x07, 0xff, 0xe3, 0xf9, 0xff, 0xff, 0xff, 0xff, 0xff,
	0xff, 0xff, 0xff, 0xff, 0xff, 0xff, 0xf9, 0xfe, 0x00, 0x7f, 0xf9, 0xff, 0xff, 0xff, 0xff, 0xff,
	0xff, 0xff, 0xff, 0xff, 0xf7, 0xff, 0xcf, 0xff, 0xbf, 0xff, 0xf9, 0xff, 0xff, 0xff, 0xff, 0xff,
	0xff, 0xff, 0xff, 0xff, 0xfb, 0xff, 0x3f, 0xff, 0xdf, 0xff, 0xfb, 0xff, 0xff, 0xff, 0xff, 0xff,
	0xff, 0xff, 0xff, 0xff, 0xfe, 0xf9, 0xff, 0xff, 0xf7, 0xff, 0xf3, 0xff, 0xff, 0xff, 0xff, 0xff,
	0xff, 0xff, 0xff, 0xff, 0xff, 0xff, 0xff, 0xff, 0xfb, 0xff, 0xe3, 0xff, 0xff, 0xff, 0xff, 0xff,
	0xff, 0xff, 0xff, 0xff, 0xff, 0xff, 0xfb, 0xff, 0xfe, 0xfc, 0x07, 0xff, 0xff, 0xff, 0xff, 0xff,
	0xff, 0xff, 0xff, 0xff, 0xff, 0xff, 0xef, 0xfb, 0xff, 0x60, 0x07, 0xff, 0xff, 0xff, 0xff, 0xff,
	0xff, 0xff, 0xff, 0xff, 0xff, 0xff, 0xff, 0xff, 0xff, 0x80, 0x0f, 0xff, 0xff, 0xff, 0xff, 0xff,
	0xff, 0xff, 0xff, 0xff, 0xff, 0xff, 0xff, 0xff, 0xff, 0xe0, 0x0f, 0xff, 0xff, 0xff, 0xff, 0xff,
	0xff, 0xff, 0xff, 0xff, 0xff, 0xff, 0xff, 0xff, 0xff, 0xf8, 0x1f, 0xff, 0xff, 0xff, 0xff, 0xff,
	0xff, 0xff, 0xff, 0xff, 0xff, 0xff, 0xff, 0xff, 0xff, 0xff, 0xff, 0xff, 0xff, 0xff, 0xff, 0xff,
	0xff, 0xff, 0xff, 0xff, 0xff, 0xff, 0xff, 0xff, 0xff, 0xff, 0xff, 0xff, 0xff, 0xff, 0xff, 0xff,
	0xff, 0xff, 0xff, 0xff, 0xff, 0xff, 0xff, 0xff, 0xff, 0xff, 0xff, 0xff, 0xff, 0xff, 0xff, 0xff,
	0xff, 0xff, 0xff, 0xff, 0xff, 0xff, 0xff, 0xff, 0xff, 0xff, 0xff, 0xff, 0xff, 0xff, 0xff, 0xff,
	0xff, 0xff, 0xff, 0xff, 0xff, 0xff, 0xff, 0xff, 0xff, 0xff, 0xff, 0xff, 0xff, 0xff, 0xff, 0xff
};
// 'contando', 128x64px
const unsigned char contando [] = {
	0xff, 0xff, 0xff, 0xff, 0xff, 0xff, 0xff, 0xff, 0xff, 0xff, 0xff, 0xff, 0xff, 0xff, 0xff, 0xff,
	0xff, 0xff, 0xff, 0xff, 0xff, 0xff, 0xff, 0xff, 0xff, 0xff, 0xff, 0xff, 0xff, 0xff, 0xff, 0xff,
	0xff, 0xff, 0xff, 0xff, 0xff, 0xff, 0xff, 0xff, 0xff, 0xff, 0xff, 0xff, 0xff, 0xff, 0xff, 0xff,
	0xff, 0xff, 0xff, 0xff, 0xff, 0xff, 0xff, 0xff, 0xff, 0xff, 0xff, 0xff, 0xff, 0xff, 0xff, 0xff,
	0xff, 0xff, 0xff, 0xff, 0xff, 0xff, 0x9f, 0xff, 0xff, 0xfc, 0x1f, 0xff, 0xff, 0xff, 0xff, 0xff,
	0xff, 0xff, 0xff, 0xff, 0xff, 0xf8, 0x03, 0xff, 0xff, 0xf0, 0x03, 0xff, 0xff, 0xff, 0xff, 0xff,
	0xff, 0xff, 0xff, 0xff, 0xff, 0xe0, 0x01, 0xff, 0xff, 0xe0, 0x00, 0xff, 0xff, 0xff, 0xff, 0xff,
	0xff, 0xff, 0xff, 0xff, 0xff, 0xc0, 0x01, 0xff, 0xff, 0xe7, 0x80, 0x7f, 0xff, 0xff, 0xff, 0xff,
	0xff, 0xff, 0xff, 0xff, 0xff, 0x03, 0xff, 0xff, 0xff, 0xff, 0xf8, 0x3f, 0xff, 0xff, 0xff, 0xff,
	0xff, 0xff, 0xff, 0xff, 0xfe, 0x1f, 0xff, 0xff, 0xff, 0xff, 0xff, 0x9f, 0xff, 0xff, 0xff, 0xff,
	0xff, 0xff, 0xff, 0xff, 0xff, 0xff, 0xff, 0xff, 0xff, 0xff, 0xff, 0xff, 0xff, 0xff, 0xff, 0xff,
	0xff, 0xff, 0xff, 0xff, 0xff, 0xff, 0xff, 0xff, 0xff, 0xff, 0xff, 0xff, 0xff, 0xff, 0xff, 0xff,
	0xff, 0xff, 0xff, 0xff, 0xff, 0xff, 0xdf, 0xff, 0xff, 0xfe, 0xff, 0xff, 0xff, 0xff, 0xff, 0xff,
	0xff, 0xff, 0xff, 0xff, 0xff, 0xf8, 0x01, 0xff, 0xff, 0xc0, 0x0f, 0xff, 0xff, 0xff, 0xff, 0xff,
	0xff, 0xff, 0xff, 0xff, 0xff, 0xf1, 0xfc, 0x7f, 0xff, 0x0f, 0xe3, 0xff, 0xff, 0xff, 0xff, 0xff,
	0xff, 0xff, 0xff, 0xff, 0xff, 0xcf, 0xff, 0x1f, 0xfe, 0x7f, 0xf9, 0xff, 0xff, 0xff, 0xff, 0xff,
	0xff, 0xff, 0xff, 0xff, 0xff, 0x9f, 0xff, 0xcf, 0xfc, 0xff, 0xfe, 0x7f, 0xff, 0xff, 0xff, 0xff,
	0xff, 0xff, 0xff, 0xff, 0xff, 0x3f, 0xff, 0xef, 0xf9, 0xff, 0xff, 0x7f, 0xff, 0xff, 0xff, 0xff,
	0xff, 0xff, 0xff, 0xff, 0xfe, 0x7f, 0xff, 0xf7, 0xf3, 0xff, 0xff, 0xbf, 0xff, 0xff, 0xff, 0xff,
	0xff, 0xff, 0xff, 0xff, 0xfe, 0xff, 0xff, 0xf3, 0xf7, 0xff, 0xff, 0x9f, 0xff, 0xff, 0xff, 0xff,
	0xff, 0xff, 0xff, 0xff, 0xfe, 0xff, 0xff, 0xfb, 0xe7, 0xff, 0xff, 0xdf, 0xff, 0xff, 0xff, 0xff,
	0xff, 0xff, 0xff, 0xff, 0xfd, 0xff, 0xf8, 0x7b, 0xef, 0xff, 0xc3, 0xdf, 0xff, 0xff, 0xff, 0xff,
	0xff, 0xff, 0xff, 0xff, 0xfd, 0xff, 0xf0, 0x3d, 0xef, 0xff, 0x81, 0xef, 0xff, 0xff, 0xff, 0xff,
	0xff, 0xff, 0xff, 0xff, 0xfd, 0xff, 0xec, 0x1d, 0xef, 0xff, 0x60, 0xef, 0xff, 0xff, 0xff, 0xff,
	0xff, 0xff, 0xff, 0xff, 0xfd, 0xff, 0xec, 0x1d, 0xef, 0xff, 0x60, 0xef, 0xff, 0xff, 0xff, 0xff,
	0xff, 0xff, 0xff, 0xff, 0xfd, 0xff, 0xec, 0x1d, 0xef, 0xff, 0x60, 0xef, 0xff, 0xff, 0xff, 0xff,
	0xff, 0xff, 0xff, 0xff, 0xfd, 0xff, 0xe0, 0x1d, 0xef, 0xff, 0x00, 0xef, 0xff, 0xff, 0xff, 0xff,
	0xff, 0xff, 0xff, 0xff, 0xfd, 0xff, 0xe0, 0x1d, 0xef, 0xff, 0x00, 0xef, 0xff, 0xff, 0xff, 0xff,
	0xff, 0xff, 0xff, 0xff, 0xfd, 0xff, 0xf0, 0x3d, 0xef, 0xff, 0x81, 0xef, 0xff, 0xff, 0xff, 0xff,
	0xff, 0xff, 0xff, 0xff, 0xff, 0xff, 0xf8, 0x7b, 0xff, 0xff, 0xc3, 0xdf, 0xff, 0xff, 0xff, 0xff,
	0xff, 0xff, 0xff, 0xff, 0xfe, 0xff, 0xff, 0xfb, 0xf7, 0xff, 0xff, 0xdf, 0xff, 0xff, 0xff, 0xff,
	0xff, 0xff, 0xff, 0xff, 0xff, 0xff, 0xff, 0xf7, 0xf7, 0xff, 0xff, 0xbf, 0xff, 0xff, 0xff, 0xff,
	0xff, 0xff, 0xff, 0xff, 0xff, 0x7f, 0xff, 0xf7, 0xfb, 0xff, 0xff, 0xbf, 0xff, 0xff, 0xff, 0xff,
	0xff, 0xff, 0xff, 0xff, 0xff, 0xbf, 0xff, 0xef, 0xfd, 0xff, 0xff, 0x7f, 0xff, 0xff, 0xff, 0xff,
	0xff, 0xff, 0xff, 0xff, 0xff, 0xdf, 0xff, 0xdf, 0xfe, 0xff, 0xfe, 0xff, 0xff, 0xff, 0xff, 0xff,
	0xff, 0xff, 0xff, 0xff, 0xff, 0xef, 0xff, 0x3f, 0xff, 0x7f, 0xf9, 0xff, 0xff, 0xff, 0xff, 0xff,
	0xff, 0xff, 0xff, 0xff, 0xff, 0xf3, 0xfc, 0xff, 0xff, 0x9f, 0xe7, 0xff, 0xff, 0xff, 0xff, 0xff,
	0xff, 0xff, 0xff, 0xff, 0xff, 0xfe, 0x03, 0xff, 0xff, 0xf0, 0x1f, 0xff, 0xff, 0xff, 0xff, 0xff,
	0xff, 0xff, 0xff, 0xff, 0xff, 0xff, 0xff, 0xff, 0xff, 0xff, 0xff, 0xff, 0xff, 0xff, 0xff, 0xff,
	0xff, 0xff, 0xff, 0xff, 0xfe, 0x1f, 0xff, 0xff, 0xff, 0xff, 0xff, 0xff, 0xff, 0xff, 0xff, 0xff,
	0xff, 0xff, 0xff, 0xff, 0xff, 0x01, 0xff, 0xff, 0xff, 0xff, 0xff, 0xff, 0xff, 0xff, 0xff, 0xff,
	0xff, 0xff, 0xff, 0xff, 0xff, 0x00, 0x1f, 0xff, 0xff, 0xff, 0xff, 0xff, 0xff, 0xff, 0xff, 0xff,
	0xff, 0xff, 0xff, 0xff, 0xff, 0x00, 0x01, 0xff, 0xff, 0xff, 0xff, 0xff, 0xff, 0xff, 0xff, 0xff,
	0xff, 0xff, 0xff, 0xff, 0xff, 0x80, 0x00, 0x1f, 0xff, 0xff, 0xff, 0xff, 0xff, 0xff, 0xff, 0xff,
	0xff, 0xff, 0xff, 0xff, 0xff, 0x80, 0x00, 0x01, 0xff, 0xff, 0xff, 0xff, 0xff, 0xff, 0xff, 0xff,
	0xff, 0xff, 0xff, 0xff, 0xff, 0xc0, 0x00, 0x00, 0x1f, 0xff, 0xff, 0xff, 0xff, 0xff, 0xff, 0xff,
	0xff, 0xff, 0xff, 0xff, 0xff, 0xc0, 0x00, 0x00, 0x03, 0xff, 0xff, 0xff, 0xff, 0xff, 0xff, 0xff,
	0xff, 0xff, 0xff, 0xff, 0xff, 0xe0, 0x00, 0x00, 0x00, 0x7f, 0xff, 0xff, 0xff, 0xff, 0xff, 0xff,
	0xff, 0xff, 0xff, 0xff, 0xff, 0xf0, 0x00, 0x00, 0x00, 0xff, 0xff, 0xff, 0xff, 0xff, 0xff, 0xff,
	0xff, 0xff, 0xff, 0xff, 0xff, 0xf8, 0x00, 0x00, 0x03, 0xff, 0xff, 0xff, 0xff, 0xff, 0xff, 0xff,
	0xff, 0xff, 0xff, 0xff, 0xff, 0xfc, 0x00, 0x00, 0x0f, 0xff, 0xff, 0xff, 0xff, 0xff, 0xff, 0xff,
	0xff, 0xff, 0xff, 0xff, 0xff, 0xff, 0x00, 0x00, 0x7f, 0xff, 0xff, 0xff, 0xff, 0xff, 0xff, 0xff,
	0xff, 0xff, 0xff, 0xff, 0xff, 0xff, 0xc0, 0x03, 0xff, 0xff, 0xff, 0xff, 0xff, 0xff, 0xff, 0xff,
	0xff, 0xff, 0xff, 0xff, 0xff, 0xf7, 0xff, 0xff, 0xff, 0xff, 0xff, 0xff, 0xff, 0xff, 0xff, 0xff,
	0xff, 0xff, 0xff, 0xff, 0xff, 0xf3, 0xff, 0xff, 0xff, 0xff, 0xff, 0xff, 0xff, 0xff, 0xff, 0xff,
	0xff, 0xff, 0xff, 0xff, 0xff, 0xf9, 0xff, 0xff, 0xff, 0xff, 0xff, 0xff, 0xff, 0xff, 0xff, 0xff,
	0xff, 0xff, 0xff, 0xff, 0xff, 0xfe, 0x0f, 0xff, 0xff, 0xff, 0xff, 0xff, 0xff, 0xff, 0xff, 0xff,
	0xff, 0xff, 0xff, 0xff, 0xff, 0xff, 0xff, 0xff, 0xff, 0xff, 0xff, 0xff, 0xff, 0xff, 0xff, 0xff,
	0xff, 0xff, 0xff, 0xff, 0xff, 0xff, 0xff, 0xff, 0xff, 0xff, 0xff, 0xff, 0xff, 0xff, 0xff, 0xff,
	0xff, 0xff, 0xff, 0xff, 0xff, 0xff, 0xff, 0xff, 0xff, 0xff, 0xff, 0xff, 0xff, 0xff, 0xff, 0xff,
	0xff, 0xff, 0xff, 0xff, 0xff, 0xff, 0xff, 0xff, 0xff, 0xff, 0xff, 0xff, 0xff, 0xff, 0xff, 0xff,
	0xff, 0xff, 0xff, 0xff, 0xff, 0xff, 0xff, 0xff, 0xff, 0xff, 0xff, 0xff, 0xff, 0xff, 0xff, 0xff,
	0xff, 0xff, 0xff, 0xff, 0xff, 0xff, 0xff, 0xff, 0xff, 0xff, 0xff, 0xff, 0xff, 0xff, 0xff, 0xff,
	0xff, 0xff, 0xff, 0xff, 0xff, 0xff, 0xff, 0xff, 0xff, 0xff, 0xff, 0xff, 0xff, 0xff, 0xff, 0xff
};
// 'enojado', 128x64px
const unsigned char enojado []  = {
	0xff, 0xff, 0xff, 0xff, 0xff, 0xff, 0xff, 0xff, 0xff, 0xff, 0xff, 0xff, 0xff, 0xff, 0xff, 0xff,
	0xff, 0xff, 0xff, 0xff, 0xff, 0xff, 0xff, 0xff, 0xff, 0xff, 0xff, 0xff, 0xff, 0xff, 0xff, 0xff,
	0xff, 0xff, 0xff, 0xff, 0xff, 0xff, 0xff, 0xff, 0xff, 0xff, 0xff, 0xff, 0xff, 0xff, 0xff, 0xff,
	0xff, 0xff, 0xff, 0xff, 0xff, 0xf7, 0xff, 0xff, 0xff, 0xff, 0xef, 0xff, 0xff, 0xff, 0xff, 0xff,
	0xff, 0xff, 0xff, 0xff, 0xff, 0xf3, 0xff, 0xff, 0xff, 0xff, 0xcf, 0xff, 0xff, 0xff, 0xff, 0xff,
	0xff, 0xff, 0xff, 0xff, 0xff, 0xf8, 0x7f, 0xff, 0xff, 0xfe, 0x1f, 0xff, 0xff, 0xff, 0xff, 0xff,
	0xff, 0xff, 0xff, 0xff, 0xff, 0xfc, 0x07, 0xff, 0xff, 0xe0, 0x3f, 0xff, 0xff, 0xff, 0xff, 0xff,
	0xff, 0xff, 0xff, 0xff, 0xff, 0xff, 0x00, 0xff, 0xff, 0x00, 0xff, 0xff, 0xff, 0xff, 0xff, 0xff,
	0xff, 0xff, 0xff, 0xff, 0xff, 0xff, 0xe0, 0x3f, 0xfc, 0x07, 0xff, 0xff, 0xff, 0xff, 0xff, 0xff,
	0xff, 0xff, 0xff, 0xff, 0xff, 0xff, 0xfe, 0x1f, 0xf8, 0x7f, 0xff, 0xff, 0xff, 0xff, 0xff, 0xff,
	0xff, 0xff, 0xff, 0xff, 0xff, 0xff, 0xff, 0xcf, 0xf3, 0xff, 0xff, 0xff, 0xff, 0xff, 0xff, 0xff,
	0xff, 0xff, 0xff, 0xff, 0xfe, 0xff, 0xff, 0xf7, 0xef, 0xff, 0xff, 0x7f, 0xff, 0xff, 0xff, 0xff,
	0xff, 0xff, 0xff, 0xff, 0xff, 0x3f, 0xff, 0xff, 0xff, 0xff, 0xfc, 0xff, 0xff, 0xff, 0xff, 0xff,
	0xff, 0xff, 0xff, 0xff, 0xff, 0x4f, 0xff, 0xff, 0xff, 0xff, 0xf2, 0xff, 0xff, 0xff, 0xff, 0xff,
	0xff, 0xff, 0xff, 0xff, 0xff, 0x61, 0xff, 0xff, 0xff, 0xff, 0x86, 0xff, 0xff, 0xff, 0xff, 0xff,
	0xff, 0xff, 0xff, 0xff, 0xfe, 0xf8, 0x3f, 0xff, 0xff, 0xfc, 0x1f, 0x7f, 0xff, 0xff, 0xff, 0xff,
	0xff, 0xff, 0xff, 0xff, 0xfe, 0xff, 0x07, 0xff, 0xff, 0xe0, 0xff, 0x7f, 0xff, 0xff, 0xff, 0xff,
	0xff, 0xff, 0xff, 0xff, 0xfe, 0xff, 0x00, 0x7d, 0xbe, 0x00, 0xff, 0x7f, 0xff, 0xff, 0xff, 0xff,
	0xff, 0xff, 0xff, 0xff, 0xfc, 0xfe, 0xe0, 0x03, 0xc0, 0x07, 0x7f, 0x3f, 0xff, 0xff, 0xff, 0xff,
	0xff, 0xff, 0xff, 0xff, 0xfd, 0xfc, 0xe1, 0xfb, 0xdf, 0x87, 0x3f, 0xbf, 0xff, 0xff, 0xff, 0xff,
	0xff, 0xff, 0xff, 0xff, 0xfd, 0xfc, 0xe1, 0xfb, 0xdf, 0x87, 0x3f, 0xbf, 0xff, 0xff, 0xff, 0xff,
	0xff, 0xff, 0xff, 0xff, 0xfd, 0xfc, 0x40, 0xfb, 0xdf, 0x02, 0x3f, 0xbf, 0xff, 0xff, 0xff, 0xff,
	0xff, 0xff, 0xff, 0xff, 0xfd, 0xfc, 0x01, 0xfb, 0xdf, 0x80, 0x3f, 0xbf, 0xff, 0xff, 0xff, 0xff,
	0xff, 0xff, 0xff, 0xff, 0xfd, 0xfe, 0x01, 0xfb, 0xdf, 0x80, 0x7f, 0xbf, 0xff, 0xff, 0xff, 0xff,
	0xff, 0xff, 0xff, 0xff, 0xfc, 0xfe, 0x01, 0xff, 0xff, 0x80, 0x7f, 0x3f, 0xff, 0xff, 0xff, 0xff,
	0xff, 0xff, 0xff, 0xff, 0xfe, 0xff, 0x03, 0xff, 0xff, 0xc0, 0xff, 0x7f, 0xff, 0xff, 0xff, 0xff,
	0xff, 0xff, 0xff, 0xff, 0xfe, 0xff, 0x8f, 0xff, 0xff, 0xf1, 0xff, 0x7f, 0xff, 0xff, 0xff, 0xff,
	0xff, 0xff, 0xff, 0xff, 0xfe, 0xff, 0xff, 0xf7, 0xef, 0xff, 0xff, 0x7f, 0xff, 0xff, 0xff, 0xff,
	0xff, 0xff, 0xff, 0xff, 0xff, 0x7f, 0xff, 0xff, 0xff, 0xff, 0xfe, 0xff, 0xff, 0xff, 0xff, 0xff,
	0xff, 0xff, 0xff, 0xff, 0xff, 0x7f, 0xff, 0xef, 0xf7, 0xff, 0xfe, 0xff, 0xff, 0xff, 0xff, 0xff,
	0xff, 0xff, 0xff, 0xff, 0xff, 0xbf, 0xff, 0xff, 0xff, 0xff, 0xfd, 0xff, 0xff, 0xff, 0xff, 0xff,
	0xff, 0xff, 0xff, 0xff, 0xff, 0x9f, 0xff, 0xdf, 0xfb, 0xff, 0xf9, 0xff, 0xff, 0xff, 0xff, 0xff,
	0xff, 0xff, 0xff, 0xff, 0xff, 0xcf, 0xff, 0xbf, 0xfd, 0xff, 0xf3, 0xff, 0xff, 0xff, 0xff, 0xff,
	0xff, 0xff, 0xff, 0xff, 0xff, 0xe7, 0xff, 0x7f, 0xfe, 0xff, 0xe7, 0xff, 0xff, 0xff, 0xff, 0xff,
	0xff, 0xff, 0xff, 0xff, 0xff, 0xf9, 0xfc, 0xff, 0xff, 0x3f, 0x9f, 0xff, 0xff, 0xff, 0xff, 0xff,
	0xff, 0xff, 0xff, 0xff, 0xff, 0xfc, 0x03, 0xff, 0xff, 0xc0, 0x3f, 0xff, 0xff, 0xff, 0xff, 0xff,
	0xff, 0xff, 0xff, 0xff, 0xff, 0xff, 0xff, 0xff, 0xff, 0xff, 0xff, 0xff, 0xff, 0xff, 0xff, 0xff,
	0xff, 0xff, 0xff, 0xff, 0xff, 0xff, 0xff, 0xff, 0xff, 0xff, 0xff, 0xff, 0xff, 0xff, 0xff, 0xff,
	0xff, 0xff, 0xff, 0xff, 0xff, 0xff, 0xff, 0xff, 0xff, 0xff, 0xff, 0xff, 0xff, 0xff, 0xff, 0xff,
	0xff, 0xff, 0xff, 0xff, 0xff, 0xff, 0xff, 0xff, 0xff, 0xff, 0xff, 0xff, 0xff, 0xff, 0xff, 0xff,
	0xff, 0xff, 0xff, 0xff, 0xff, 0xff, 0xff, 0x3f, 0xff, 0xff, 0xff, 0xff, 0xff, 0xff, 0xff, 0xff,
	0xff, 0xff, 0xff, 0xff, 0xff, 0xff, 0xf3, 0xf3, 0xff, 0xff, 0xff, 0xff, 0xff, 0xff, 0xff, 0xff,
	0xff, 0xff, 0xff, 0xff, 0xff, 0xff, 0xcf, 0xfe, 0x7f, 0x0c, 0xff, 0xff, 0xff, 0xff, 0xff, 0xff,
	0xff, 0xff, 0xff, 0xff, 0xff, 0xff, 0xbf, 0xfb, 0xf7, 0xff, 0x7f, 0xff, 0xff, 0xff, 0xff, 0xff,
	0xff, 0xff, 0xff, 0xff, 0xff, 0xff, 0x7d, 0xff, 0xff, 0xff, 0x3f, 0xff, 0xff, 0xff, 0xff, 0xff,
	0xff, 0xff, 0xff, 0xff, 0xff, 0xff, 0x7d, 0xff, 0xff, 0xef, 0xbf, 0xff, 0xff, 0xff, 0xff, 0xff,
	0xff, 0xff, 0xff, 0xff, 0xff, 0xfe, 0xfd, 0xff, 0xff, 0xef, 0xbf, 0xff, 0xff, 0xff, 0xff, 0xff,
	0xff, 0xff, 0xff, 0xff, 0xff, 0xfe, 0xe0, 0x3f, 0xff, 0xeb, 0xdf, 0xff, 0xff, 0xff, 0xff, 0xff,
	0xff, 0xff, 0xff, 0xff, 0xff, 0xfe, 0xfd, 0xf1, 0xff, 0xcf, 0xff, 0xff, 0xff, 0xff, 0xff, 0xff,
	0xff, 0xff, 0xff, 0xff, 0xff, 0xfe, 0xfd, 0xff, 0xf3, 0xef, 0xbf, 0xff, 0xff, 0xff, 0xff, 0xff,
	0xff, 0xff, 0xff, 0xff, 0xff, 0xfe, 0xfd, 0xff, 0xff, 0xef, 0xbf, 0xff, 0xff, 0xff, 0xff, 0xff,
	0xff, 0xff, 0xff, 0xff, 0xff, 0xff, 0xfd, 0xff, 0xff, 0xef, 0x7f, 0xff, 0xff, 0xff, 0xff, 0xff,
	0xff, 0xff, 0xff, 0xff, 0xff, 0xff, 0x7d, 0xff, 0xf7, 0xfe, 0xff, 0xff, 0xff, 0xff, 0xff, 0xff,
	0xff, 0xff, 0xff, 0xff, 0xff, 0xff, 0x3d, 0xff, 0xe0, 0x03, 0xff, 0xff, 0xff, 0xff, 0xff, 0xff,
	0xff, 0xff, 0xff, 0xff, 0xff, 0xff, 0xbf, 0xfa, 0x7f, 0xff, 0xff, 0xff, 0xff, 0xff, 0xff, 0xff,
	0xff, 0xff, 0xff, 0xff, 0xff, 0xff, 0xcf, 0xf3, 0xff, 0xff, 0xff, 0xff, 0xff, 0xff, 0xff, 0xff,
	0xff, 0xff, 0xff, 0xff, 0xff, 0xff, 0xf0, 0x1f, 0xff, 0xff, 0xff, 0xff, 0xff, 0xff, 0xff, 0xff,
	0xff, 0xff, 0xff, 0xff, 0xff, 0xff, 0xff, 0xff, 0xff, 0xff, 0xff, 0xff, 0xff, 0xff, 0xff, 0xff,
	0xff, 0xff, 0xff, 0xff, 0xff, 0xff, 0xff, 0xff, 0xff, 0xff, 0xff, 0xff, 0xff, 0xff, 0xff, 0xff,
	0xff, 0xff, 0xff, 0xff, 0xff, 0xff, 0xff, 0xff, 0xff, 0xff, 0xff, 0xff, 0xff, 0xff, 0xff, 0xff,
	0xff, 0xff, 0xff, 0xff, 0xff, 0xff, 0xff, 0xff, 0xff, 0xff, 0xff, 0xff, 0xff, 0xff, 0xff, 0xff,
	0xff, 0xff, 0xff, 0xff, 0xff, 0xff, 0xff, 0xff, 0xff, 0xff, 0xff, 0xff, 0xff, 0xff, 0xff, 0xff,
	0xff, 0xff, 0xff, 0xff, 0xff, 0xff, 0xff, 0xff, 0xff, 0xff, 0xff, 0xff, 0xff, 0xff, 0xff, 0xff,
	0xff, 0xff, 0xff, 0xff, 0xff, 0xff, 0xff, 0xff, 0xff, 0xff, 0xff, 0xff, 0xff, 0xff, 0xff, 0xff
};

// 'emocionado', 128x64px
const unsigned char emocionado [] = {
	0xff, 0xff, 0xff, 0xff, 0xff, 0xff, 0xff, 0xff, 0xff, 0xff, 0xff, 0xff, 0xff, 0xff, 0xff, 0xff,
	0xff, 0xff, 0xff, 0xff, 0xff, 0xff, 0xff, 0xff, 0xff, 0xff, 0xff, 0xff, 0xff, 0xff, 0xff, 0xff,
	0xff, 0xff, 0xff, 0xff, 0xff, 0xff, 0xff, 0xff, 0xff, 0xff, 0xff, 0xff, 0xff, 0xff, 0xff, 0xff,
	0xff, 0xff, 0xff, 0xff, 0xff, 0xff, 0xff, 0xff, 0xff, 0xff, 0xff, 0xff, 0xff, 0xff, 0xff, 0xff,
	0xff, 0xff, 0xff, 0xff, 0xff, 0xfc, 0x1f, 0xff, 0xff, 0xf8, 0x3f, 0xff, 0xff, 0xff, 0xff, 0xff,
	0xff, 0xff, 0xff, 0xff, 0xff, 0xe0, 0x3f, 0xff, 0xff, 0xf8, 0x0f, 0xff, 0xff, 0xff, 0xff, 0xff,
	0xff, 0xff, 0xff, 0xff, 0xff, 0xc3, 0xff, 0xff, 0xff, 0xff, 0xc3, 0xff, 0xff, 0xff, 0xff, 0xff,
	0xff, 0xff, 0xff, 0xff, 0xff, 0x0f, 0xff, 0xff, 0xff, 0xff, 0xf1, 0xff, 0xff, 0xff, 0xff, 0xff,
	0xff, 0xff, 0xff, 0xff, 0xff, 0x3f, 0xff, 0xff, 0xff, 0xff, 0xf8, 0xff, 0xff, 0xff, 0xff, 0xff,
	0xff, 0xff, 0xff, 0xff, 0xfe, 0x7f, 0xff, 0xff, 0xff, 0xff, 0xfc, 0xff, 0xff, 0xff, 0xff, 0xff,
	0xff, 0xff, 0xff, 0xff, 0xff, 0xfc, 0x1f, 0xff, 0xff, 0xf8, 0x7f, 0xff, 0xff, 0xff, 0xff, 0xff,
	0xff, 0xff, 0xff, 0xff, 0xff, 0xe1, 0xc3, 0xff, 0xff, 0xc3, 0x0f, 0xff, 0xff, 0xff, 0xff, 0xff,
	0xff, 0xff, 0xff, 0xff, 0xff, 0xcf, 0xf9, 0xff, 0xff, 0x1f, 0xf3, 0xff, 0xff, 0xff, 0xff, 0xff,
	0xff, 0xff, 0xff, 0xff, 0xff, 0x9f, 0xfe, 0xff, 0xfe, 0x7f, 0xf9, 0xff, 0xff, 0xff, 0xff, 0xff,
	0xff, 0xff, 0xff, 0xff, 0xff, 0x7c, 0x1f, 0x7f, 0xfc, 0xf8, 0x7c, 0xff, 0xff, 0xff, 0xff, 0xff,
	0xff, 0xff, 0xff, 0xff, 0xfe, 0x70, 0x07, 0xbf, 0xfd, 0xe0, 0x1e, 0x7f, 0xff, 0xff, 0xff, 0xff,
	0xff, 0xff, 0xff, 0xff, 0xfe, 0xe0, 0x03, 0x9f, 0xfb, 0xc0, 0x07, 0x7f, 0xff, 0xff, 0xff, 0xff,
	0xff, 0xff, 0xff, 0xff, 0xfd, 0xc3, 0x01, 0xdf, 0xfb, 0x8c, 0x07, 0x3f, 0xff, 0xff, 0xff, 0xff,
	0xff, 0xff, 0xff, 0xff, 0xfd, 0xc1, 0x21, 0xdf, 0xf3, 0x0c, 0x83, 0xbf, 0xff, 0xff, 0xff, 0xff,
	0xff, 0xff, 0xff, 0xff, 0xfd, 0x8e, 0xf8, 0xcf, 0xf7, 0x33, 0xe3, 0xbf, 0xff, 0xff, 0xff, 0xff,
	0xff, 0xff, 0xff, 0xff, 0xf9, 0x8f, 0xfc, 0xef, 0xf7, 0x3f, 0xf1, 0xbf, 0xff, 0xff, 0xff, 0xff,
	0xff, 0xff, 0xff, 0xff, 0xf9, 0x8f, 0xfc, 0xef, 0xf6, 0x37, 0xf1, 0xbf, 0xff, 0xff, 0xff, 0xff,
	0xff, 0xff, 0xff, 0xff, 0xfd, 0x81, 0xfc, 0xef, 0xf6, 0x07, 0xf1, 0xbf, 0xff, 0xff, 0xff, 0xff,
	0xff, 0xff, 0xff, 0xff, 0xfd, 0x81, 0xfc, 0xcf, 0xf7, 0x07, 0xf3, 0xbf, 0xff, 0xff, 0xff, 0xff,
	0xff, 0xff, 0xff, 0xff, 0xfd, 0x80, 0xf8, 0xdf, 0xf3, 0x03, 0xe3, 0xbf, 0xff, 0xff, 0xff, 0xff,
	0xff, 0xff, 0xff, 0xff, 0xfc, 0xc0, 0x01, 0xdf, 0xfb, 0x00, 0x03, 0x7f, 0xff, 0xff, 0xff, 0xff,
	0xff, 0xff, 0xff, 0xff, 0xfe, 0xe0, 0x01, 0xbf, 0xf9, 0x80, 0x07, 0x7f, 0xff, 0xff, 0xff, 0xff,
	0xff, 0xff, 0xff, 0xff, 0xfe, 0x70, 0x03, 0x3f, 0xfd, 0xc0, 0x0e, 0xff, 0xff, 0xff, 0xff, 0xff,
	0xff, 0xff, 0xff, 0xff, 0xff, 0x38, 0x0f, 0x7f, 0xfe, 0xf0, 0x1c, 0xff, 0xff, 0xff, 0xff, 0xff,
	0xff, 0xff, 0xff, 0xff, 0xff, 0x9f, 0xfc, 0xff, 0xfe, 0x7f, 0xf9, 0xff, 0xff, 0xff, 0xff, 0xff,
	0xff, 0xff, 0xff, 0xff, 0xff, 0xc7, 0xf9, 0xff, 0xff, 0x9f, 0xe7, 0xff, 0xff, 0xff, 0xff, 0xff,
	0xff, 0xff, 0xff, 0xff, 0xff, 0xf0, 0x07, 0xff, 0xff, 0xc0, 0x0f, 0xff, 0xff, 0xff, 0xff, 0xff,
	0xff, 0xff, 0xff, 0xff, 0xff, 0xff, 0xff, 0xc0, 0x07, 0xff, 0xff, 0xff, 0xff, 0xff, 0xff, 0xff,
	0xff, 0xff, 0xff, 0xff, 0xff, 0xff, 0xff, 0x80, 0x03, 0xff, 0xff, 0xff, 0xff, 0xff, 0xff, 0xff,
	0xff, 0xff, 0xff, 0xff, 0xff, 0xff, 0xff, 0x8e, 0xe3, 0xff, 0xff, 0xff, 0xff, 0xff, 0xff, 0xff,
	0xff, 0xff, 0xff, 0xff, 0xff, 0xcc, 0xcf, 0x80, 0x03, 0xe6, 0x67, 0xff, 0xff, 0xff, 0xff, 0xff,
	0xff, 0xff, 0xff, 0xff, 0xff, 0xcc, 0xcf, 0x80, 0x03, 0xe6, 0x67, 0xff, 0xff, 0xff, 0xff, 0xff,
	0xff, 0xff, 0xff, 0xff, 0xff, 0xcc, 0xcf, 0x80, 0x03, 0xe6, 0x67, 0xff, 0xff, 0xff, 0xff, 0xff,
	0xff, 0xff, 0xff, 0xff, 0xff, 0xcc, 0xcf, 0x80, 0x03, 0xe6, 0x67, 0xff, 0xff, 0xff, 0xff, 0xff,
	0xff, 0xff, 0xff, 0xff, 0xff, 0xcc, 0xef, 0x80, 0x03, 0xe6, 0x67, 0xff, 0xff, 0xff, 0xff, 0xff,
	0xff, 0xff, 0xff, 0xff, 0xff, 0xec, 0xef, 0x80, 0x03, 0xe6, 0xe7, 0xff, 0xff, 0xff, 0xff, 0xff,
	0xff, 0xff, 0xff, 0xff, 0xff, 0xff, 0xff, 0x80, 0x03, 0xff, 0xff, 0xff, 0xff, 0xff, 0xff, 0xff,
	0xff, 0xff, 0xff, 0xff, 0xff, 0xff, 0xff, 0x80, 0x03, 0xff, 0xff, 0xff, 0xff, 0xff, 0xff, 0xff,
	0xff, 0xff, 0xff, 0xff, 0xff, 0xff, 0xff, 0x80, 0x03, 0xff, 0xff, 0xff, 0xff, 0xff, 0xff, 0xff,
	0xff, 0xff, 0xff, 0xff, 0xff, 0xff, 0xff, 0x80, 0x03, 0xff, 0xff, 0xff, 0xff, 0xff, 0xff, 0xff,
	0xff, 0xff, 0xff, 0xff, 0xff, 0xff, 0xff, 0x80, 0x03, 0xff, 0xff, 0xff, 0xff, 0xff, 0xff, 0xff,
	0xff, 0xff, 0xff, 0xff, 0xff, 0xff, 0xff, 0x80, 0x03, 0xff, 0xff, 0xff, 0xff, 0xff, 0xff, 0xff,
	0xff, 0xff, 0xff, 0xff, 0xff, 0xff, 0xff, 0x80, 0x03, 0xff, 0xff, 0xff, 0xff, 0xff, 0xff, 0xff,
	0xff, 0xff, 0xff, 0xff, 0xff, 0xff, 0xff, 0x80, 0x03, 0xff, 0xff, 0xff, 0xff, 0xff, 0xff, 0xff,
	0xff, 0xff, 0xff, 0xff, 0xff, 0xff, 0xff, 0x80, 0x03, 0xff, 0xff, 0xff, 0xff, 0xff, 0xff, 0xff,
	0xff, 0xff, 0xff, 0xff, 0xff, 0xff, 0xff, 0x80, 0x03, 0xff, 0xff, 0xff, 0xff, 0xff, 0xff, 0xff,
	0xff, 0xff, 0xff, 0xff, 0xff, 0xff, 0xff, 0x80, 0x03, 0xff, 0xff, 0xff, 0xff, 0xff, 0xff, 0xff,
	0xff, 0xff, 0xff, 0xff, 0xff, 0xff, 0xff, 0x80, 0x03, 0xff, 0xff, 0xff, 0xff, 0xff, 0xff, 0xff,
	0xff, 0xff, 0xff, 0xff, 0xff, 0xff, 0xff, 0xc0, 0x03, 0xff, 0xff, 0xff, 0xff, 0xff, 0xff, 0xff,
	0xff, 0xff, 0xff, 0xff, 0xff, 0xff, 0xff, 0xc0, 0x07, 0xff, 0xff, 0xff, 0xff, 0xff, 0xff, 0xff,
	0xff, 0xff, 0xff, 0xff, 0xff, 0xff, 0xff, 0xc0, 0x07, 0xff, 0xff, 0xff, 0xff, 0xff, 0xff, 0xff,
	0xff, 0xff, 0xff, 0xff, 0xff, 0xff, 0xff, 0xe0, 0x0f, 0xff, 0xff, 0xff, 0xff, 0xff, 0xff, 0xff,
	0xff, 0xff, 0xff, 0xff, 0xff, 0xff, 0xff, 0xf8, 0x3f, 0xff, 0xff, 0xff, 0xff, 0xff, 0xff, 0xff,
	0xff, 0xff, 0xff, 0xff, 0xff, 0xff, 0xff, 0xff, 0xff, 0xff, 0xff, 0xff, 0xff, 0xff, 0xff, 0xff,
	0xff, 0xff, 0xff, 0xff, 0xff, 0xff, 0xff, 0xff, 0xff, 0xff, 0xff, 0xff, 0xff, 0xff, 0xff, 0xff,
	0xff, 0xff, 0xff, 0xff, 0xff, 0xff, 0xff, 0xff, 0xff, 0xff, 0xff, 0xff, 0xff, 0xff, 0xff, 0xff,
	0xff, 0xff, 0xff, 0xff, 0xff, 0xff, 0xff, 0xff, 0xff, 0xff, 0xff, 0xff, 0xff, 0xff, 0xff, 0xff,
	0xff, 0xff, 0xff, 0xff, 0xff, 0xff, 0xff, 0xff, 0xff, 0xff, 0xff, 0xff, 0xff, 0xff, 0xff, 0xff,
	0xff, 0xff, 0xff, 0xff, 0xff, 0xff, 0xff, 0xff, 0xff, 0xff, 0xff, 0xff, 0xff, 0xff, 0xff, 0xff
};

// 'desesperado', 128x64px
const unsigned char desesperado [] = {
	0xff, 0xff, 0xff, 0xff, 0xff, 0xff, 0xff, 0xff, 0xff, 0xff, 0xff, 0xff, 0xff, 0xff, 0xff, 0xff,
	0xff, 0xff, 0xff, 0xff, 0xff, 0xff, 0xff, 0xff, 0xff, 0xff, 0xff, 0xff, 0xff, 0xff, 0xff, 0xff,
	0xff, 0xff, 0xff, 0xff, 0xff, 0xff, 0xff, 0xff, 0xff, 0xff, 0xff, 0xff, 0xff, 0xff, 0xff, 0xff,
	0xff, 0xff, 0xff, 0xff, 0xff, 0xff, 0xff, 0xff, 0xff, 0xff, 0xff, 0xff, 0xff, 0xff, 0xff, 0xff,
	0xff, 0xff, 0xff, 0xff, 0xff, 0xff, 0x7f, 0xff, 0xff, 0xf1, 0xff, 0xff, 0xff, 0xff, 0xff, 0xff,
	0xff, 0xff, 0xff, 0xff, 0xff, 0xf8, 0x1f, 0xff, 0xff, 0xc0, 0x7f, 0xff, 0xff, 0xff, 0xff, 0xff,
	0xff, 0xff, 0xff, 0xff, 0xff, 0xe0, 0x0f, 0xff, 0xff, 0x80, 0x1f, 0xff, 0xff, 0xff, 0xff, 0xff,
	0xff, 0xff, 0xff, 0xff, 0xff, 0x80, 0x07, 0xff, 0xff, 0x00, 0x07, 0xff, 0xff, 0xff, 0xff, 0xff,
	0xff, 0xff, 0xff, 0xff, 0xff, 0x00, 0x03, 0xff, 0xfe, 0x00, 0x7f, 0xff, 0xff, 0xff, 0xff, 0xff,
	0xff, 0xff, 0xff, 0xff, 0xff, 0xfe, 0x01, 0xff, 0xfe, 0x03, 0xff, 0xff, 0xff, 0xff, 0xff, 0xff,
	0xff, 0xff, 0xff, 0xff, 0xff, 0xff, 0x80, 0xff, 0xfc, 0x07, 0xff, 0xff, 0xff, 0xff, 0xff, 0xff,
	0xff, 0xff, 0xff, 0xff, 0xff, 0xff, 0xc0, 0x7f, 0xf8, 0x1f, 0xff, 0xff, 0xff, 0xff, 0xff, 0xff,
	0xff, 0xff, 0xff, 0xff, 0xff, 0xff, 0xf0, 0x3f, 0xf0, 0x3f, 0xff, 0xff, 0xff, 0xff, 0xff, 0xff,
	0xff, 0xff, 0xff, 0xff, 0xff, 0xff, 0xf8, 0x3f, 0xf0, 0x7f, 0x3f, 0xff, 0xff, 0xff, 0xff, 0xff,
	0xff, 0xff, 0xff, 0xff, 0xff, 0xff, 0xfe, 0x7f, 0xf9, 0xff, 0xc3, 0xff, 0xff, 0xff, 0xff, 0xff,
	0xff, 0xff, 0xff, 0xff, 0xff, 0xff, 0xff, 0xff, 0xff, 0xfe, 0x03, 0xff, 0xff, 0xff, 0xff, 0xff,
	0xff, 0xff, 0xff, 0xff, 0xff, 0x80, 0xff, 0xff, 0xf3, 0xfc, 0x03, 0xff, 0xff, 0xff, 0xff, 0xff,
	0xff, 0xff, 0xff, 0xff, 0xff, 0x80, 0x1f, 0xff, 0xff, 0xf0, 0xff, 0xff, 0xff, 0xff, 0xff, 0xff,
	0xff, 0xff, 0xff, 0xff, 0xff, 0x80, 0x07, 0xff, 0xff, 0xe3, 0xff, 0x7f, 0xff, 0xff, 0xff, 0xff,
	0xff, 0xff, 0xff, 0xff, 0xff, 0xff, 0x83, 0xff, 0xff, 0x8f, 0xff, 0xff, 0xff, 0xff, 0xff, 0xff,
	0xff, 0xff, 0xff, 0xff, 0xff, 0xff, 0xf0, 0xff, 0xff, 0x1c, 0x00, 0x3f, 0xff, 0xff, 0xff, 0xff,
	0xff, 0xff, 0xff, 0xff, 0xff, 0xc0, 0x00, 0x7f, 0xfe, 0x00, 0x00, 0x0f, 0xff, 0xff, 0xff, 0xff,
	0xff, 0xff, 0xff, 0xff, 0xfc, 0x00, 0x00, 0x3f, 0xfc, 0x00, 0x60, 0x07, 0xff, 0xff, 0xff, 0xff,
	0xff, 0xff, 0xff, 0xff, 0xf0, 0x03, 0xf0, 0x3f, 0xf8, 0x0f, 0xff, 0x87, 0xff, 0xff, 0xff, 0xff,
	0xff, 0xff, 0xff, 0xff, 0xe0, 0x3f, 0xc3, 0xff, 0xff, 0xc0, 0xff, 0xff, 0xff, 0xff, 0xff, 0xff,
	0xff, 0xff, 0xff, 0xff, 0xe1, 0xff, 0x0f, 0xff, 0xff, 0xf8, 0x1f, 0xff, 0xff, 0xff, 0xff, 0xff,
	0xff, 0xff, 0xff, 0xff, 0xff, 0xfc, 0x3f, 0xff, 0xff, 0xff, 0x07, 0xff, 0xff, 0xff, 0xff, 0xff,
	0xff, 0xff, 0xff, 0xff, 0xff, 0xf0, 0xff, 0xff, 0xff, 0xff, 0xc1, 0xff, 0xff, 0xff, 0xff, 0xff,
	0xff, 0xff, 0xff, 0xff, 0xff, 0xe1, 0xff, 0xff, 0xff, 0xff, 0xf1, 0xff, 0xff, 0xff, 0xff, 0xff,
	0xff, 0xff, 0xff, 0xff, 0xff, 0xc7, 0xff, 0xff, 0xff, 0xff, 0xff, 0xff, 0xff, 0xff, 0xff, 0xff,
	0xff, 0xff, 0xff, 0xff, 0xff, 0xdf, 0xff, 0xff, 0xff, 0xff, 0xff, 0xff, 0xff, 0xff, 0xff, 0xff,
	0xff, 0xff, 0xff, 0xff, 0xff, 0xff, 0xff, 0xf0, 0x00, 0xff, 0xff, 0xff, 0xff, 0xff, 0xff, 0xff,
	0xff, 0xff, 0xff, 0xff, 0xff, 0xff, 0xff, 0x03, 0xff, 0x8f, 0xff, 0xff, 0xff, 0xff, 0xff, 0xff,
	0xff, 0xff, 0xff, 0xff, 0xff, 0xff, 0xf8, 0xff, 0xff, 0xf3, 0xff, 0xff, 0xff, 0xff, 0xff, 0xff,
	0xff, 0xff, 0xff, 0xff, 0xff, 0xff, 0xe7, 0xff, 0xff, 0xfc, 0xff, 0xff, 0xff, 0xff, 0xff, 0xff,
	0xff, 0xff, 0xff, 0xff, 0xff, 0xff, 0xdf, 0xff, 0xff, 0xff, 0x7f, 0xff, 0xff, 0xff, 0xff, 0xff,
	0xff, 0xff, 0xff, 0xff, 0xff, 0xff, 0x3f, 0xff, 0xff, 0xff, 0x3f, 0xff, 0xff, 0xff, 0xff, 0xff,
	0xff, 0xff, 0xff, 0xff, 0xff, 0xfe, 0x7f, 0xff, 0xff, 0xff, 0x9f, 0xff, 0xff, 0xff, 0xff, 0xff,
	0xff, 0xff, 0xff, 0xff, 0xff, 0xfe, 0xff, 0xff, 0xc0, 0xff, 0x0f, 0xff, 0xff, 0xff, 0xff, 0xff,
	0xff, 0xff, 0xff, 0xff, 0xff, 0xfc, 0xff, 0x00, 0x00, 0x00, 0x07, 0xff, 0xff, 0xff, 0xff, 0xff,
	0xff, 0xff, 0xff, 0xff, 0xff, 0xf8, 0x40, 0x00, 0x00, 0x00, 0x07, 0xff, 0xff, 0xff, 0xff, 0xff,
	0xff, 0xff, 0xff, 0xff, 0xff, 0xf8, 0x00, 0x00, 0x00, 0x00, 0x03, 0xff, 0xff, 0xff, 0xff, 0xff,
	0xff, 0xff, 0xff, 0xff, 0xff, 0xf0, 0x00, 0x00, 0x00, 0x00, 0x03, 0xff, 0xff, 0xff, 0xff, 0xff,
	0xff, 0xff, 0xff, 0xff, 0xff, 0xf0, 0x00, 0x00, 0x00, 0x00, 0x01, 0xff, 0xff, 0xff, 0xff, 0xff,
	0xff, 0xff, 0xff, 0xff, 0xff, 0xe0, 0x00, 0x00, 0x00, 0x00, 0x01, 0xff, 0xff, 0xff, 0xff, 0xff,
	0xff, 0xff, 0xff, 0xff, 0xff, 0xe0, 0x00, 0x00, 0x00, 0x00, 0x00, 0xff, 0xff, 0xff, 0xff, 0xff,
	0xff, 0xff, 0xff, 0xff, 0xff, 0xe0, 0x00, 0x00, 0x00, 0x00, 0x00, 0xff, 0xff, 0xff, 0xff, 0xff,
	0xff, 0xff, 0xff, 0xff, 0xff, 0xc0, 0x00, 0x00, 0x00, 0x00, 0x00, 0xff, 0xff, 0xff, 0xff, 0xff,
	0xff, 0xff, 0xff, 0xff, 0xff, 0xc0, 0x00, 0x00, 0x00, 0x00, 0x00, 0x7f, 0xff, 0xff, 0xff, 0xff,
	0xff, 0xff, 0xff, 0xff, 0xff, 0xc0, 0x00, 0x00, 0x00, 0x00, 0x00, 0x7f, 0xff, 0xff, 0xff, 0xff,
	0xff, 0xff, 0xff, 0xff, 0xff, 0x80, 0x00, 0x0f, 0xff, 0xff, 0x80, 0xff, 0xff, 0xff, 0xff, 0xff,
	0xff, 0xff, 0xff, 0xff, 0xff, 0xc0, 0x03, 0xff, 0xff, 0xff, 0xff, 0xff, 0xff, 0xff, 0xff, 0xff,
	0xff, 0xff, 0xff, 0xff, 0xff, 0xc0, 0x7f, 0xff, 0x00, 0xff, 0xff, 0xff, 0xff, 0xff, 0xff, 0xff,
	0xff, 0xff, 0xff, 0xff, 0xff, 0xff, 0xff, 0xff, 0xff, 0xff, 0xff, 0xff, 0xff, 0xff, 0xff, 0xff,
	0xff, 0xff, 0xff, 0xff, 0xff, 0xff, 0xff, 0xff, 0xff, 0xff, 0xff, 0xff, 0xff, 0xff, 0xff, 0xff,
	0xff, 0xff, 0xff, 0xff, 0xff, 0xff, 0xff, 0xff, 0xff, 0xff, 0xff, 0xff, 0xff, 0xff, 0xff, 0xff,
	0xff, 0xff, 0xff, 0xff, 0xff, 0xff, 0xff, 0xff, 0xff, 0xff, 0xff, 0xff, 0xff, 0xff, 0xff, 0xff,
	0xff, 0xff, 0xff, 0xff, 0xff, 0xff, 0xff, 0xff, 0xff, 0xff, 0xff, 0xff, 0xff, 0xff, 0xff, 0xff,
	0xff, 0xff, 0xff, 0xff, 0xff, 0xff, 0xff, 0xff, 0xff, 0xff, 0xff, 0xff, 0xff, 0xff, 0xff, 0xff,
	0xff, 0xff, 0xff, 0xff, 0xff, 0xff, 0xff, 0xff, 0xff, 0xff, 0xff, 0xff, 0xff, 0xff, 0xff, 0xff,
	0xff, 0xff, 0xff, 0xff, 0xff, 0xff, 0xff, 0xff, 0xff, 0xff, 0xff, 0xff, 0xff, 0xff, 0xff, 0xff,
	0xff, 0xff, 0xff, 0xff, 0xff, 0xff, 0xff, 0xff, 0xff, 0xff, 0xff, 0xff, 0xff, 0xff, 0xff, 0xff,
	0xff, 0xff, 0xff, 0xff, 0xff, 0xff, 0xff, 0xff, 0xff, 0xff, 0xff, 0xff, 0xff, 0xff, 0xff, 0xff,
	0xff, 0xff, 0xff, 0xff, 0xff, 0xff, 0xff, 0xff, 0xff, 0xff, 0xff, 0xff, 0xff, 0xff, 0xff, 0xff
};

// 'gafas', 128x64px
const unsigned char gafas [] = {
	0xff, 0xff, 0xff, 0xff, 0xff, 0xff, 0xff, 0xff, 0xff, 0xff, 0xff, 0xff, 0xff, 0xff, 0xff, 0xff,
	0xff, 0xff, 0xff, 0xff, 0xff, 0xff, 0xff, 0xff, 0xff, 0xff, 0xff, 0xff, 0xff, 0xff, 0xff, 0xff,
	0xff, 0xff, 0xff, 0xff, 0xff, 0xff, 0xff, 0xff, 0xff, 0xff, 0xff, 0xff, 0xff, 0xff, 0xff, 0xff,
	0xff, 0xff, 0xff, 0xff, 0xff, 0xff, 0xff, 0xff, 0xff, 0xff, 0xff, 0xff, 0xff, 0xff, 0xff, 0xff,
	0xff, 0xff, 0xff, 0xff, 0xff, 0xff, 0xff, 0xff, 0xff, 0xff, 0xff, 0xff, 0xff, 0xff, 0xff, 0xff,
	0xff, 0xff, 0xff, 0xff, 0xff, 0xff, 0xff, 0xff, 0xff, 0xff, 0xff, 0xff, 0xff, 0xff, 0xff, 0xff,
	0xff, 0xff, 0xff, 0xff, 0xff, 0xff, 0xff, 0xff, 0xff, 0xff, 0xff, 0xff, 0xff, 0xff, 0xff, 0xff,
	0xff, 0xff, 0xff, 0xff, 0xff, 0xff, 0xff, 0xff, 0xff, 0xff, 0xff, 0xff, 0xff, 0xff, 0xff, 0xff,
	0xff, 0xff, 0xff, 0xff, 0xf8, 0x00, 0x7f, 0xff, 0xff, 0xff, 0x00, 0x0f, 0xff, 0xff, 0xff, 0xff,
	0xff, 0xff, 0xff, 0xff, 0xf0, 0x00, 0x3f, 0xff, 0xff, 0xfe, 0x00, 0x07, 0xff, 0xff, 0xff, 0xff,
	0xff, 0xff, 0xff, 0xff, 0xf0, 0x00, 0x7f, 0xff, 0xff, 0xff, 0x00, 0x07, 0xff, 0xff, 0xff, 0xff,
	0xff, 0xff, 0xff, 0xff, 0xf8, 0x00, 0xff, 0xff, 0xff, 0xff, 0x00, 0x1f, 0xff, 0xff, 0xff, 0xff,
	0xff, 0xff, 0xff, 0xff, 0xff, 0xff, 0xff, 0xff, 0xff, 0xff, 0xff, 0xff, 0xff, 0xff, 0xff, 0xff,
	0xff, 0xff, 0xff, 0xff, 0xff, 0xff, 0xff, 0xff, 0xff, 0xff, 0xff, 0xff, 0xff, 0xff, 0xff, 0xff,
	0xff, 0xff, 0xff, 0xff, 0xff, 0xff, 0xff, 0xff, 0xff, 0xff, 0xff, 0xff, 0xff, 0xff, 0xff, 0xff,
	0xff, 0xff, 0xff, 0xff, 0xff, 0xff, 0xff, 0xff, 0xff, 0xff, 0xff, 0xff, 0xff, 0xff, 0xff, 0xff,
	0xff, 0xff, 0xff, 0xff, 0xff, 0xff, 0xff, 0xff, 0xff, 0xff, 0xff, 0xff, 0xff, 0xff, 0xff, 0xff,
	0xff, 0xff, 0xfc, 0x00, 0x00, 0x00, 0x00, 0x7f, 0xff, 0x00, 0x00, 0x00, 0x00, 0x1f, 0xff, 0xff,
	0xff, 0xff, 0xf8, 0x00, 0x00, 0x00, 0x00, 0x7f, 0xff, 0x00, 0x00, 0x00, 0x00, 0x0f, 0xff, 0xff,
	0xff, 0xff, 0xf8, 0x00, 0x02, 0x00, 0x00, 0x7f, 0xff, 0x00, 0x00, 0x20, 0x00, 0x0f, 0xff, 0xff,
	0xff, 0xff, 0xfc, 0x00, 0x07, 0x00, 0x00, 0x7f, 0xff, 0x00, 0x00, 0xf0, 0x00, 0x0f, 0xff, 0xff,
	0xff, 0xff, 0xfc, 0x00, 0x0f, 0x00, 0x00, 0x00, 0x00, 0x00, 0x01, 0xf0, 0x00, 0x1f, 0xff, 0xff,
	0xff, 0xff, 0xfc, 0x00, 0x1f, 0x18, 0x00, 0x00, 0x00, 0x00, 0x03, 0xe3, 0x80, 0x1f, 0xff, 0xff,
	0xff, 0xff, 0xfc, 0x00, 0x3e, 0x3c, 0x00, 0x00, 0x00, 0x00, 0x03, 0xc7, 0x80, 0x1f, 0xff, 0xff,
	0xff, 0xff, 0xfe, 0x00, 0x3c, 0x7c, 0x00, 0x00, 0x00, 0x00, 0x03, 0x8f, 0x80, 0x3f, 0xff, 0xff,
	0xff, 0xff, 0xfe, 0x00, 0x10, 0xf8, 0x00, 0x00, 0x00, 0x00, 0x01, 0x1f, 0x00, 0x3f, 0xff, 0xff,
	0xff, 0xff, 0xff, 0x00, 0x01, 0xf0, 0x01, 0xff, 0xff, 0xc0, 0x00, 0x3e, 0x00, 0x7f, 0xff, 0xff,
	0xff, 0xff, 0xff, 0x00, 0x03, 0xe0, 0x03, 0xff, 0xff, 0xe0, 0x00, 0x7c, 0x00, 0x7f, 0xff, 0xff,
	0xff, 0xff, 0xff, 0x80, 0x07, 0xc0, 0x03, 0xff, 0xff, 0xf0, 0x00, 0xf8, 0x00, 0xff, 0xff, 0xff,
	0xff, 0xff, 0xff, 0xc0, 0x0f, 0x80, 0x07, 0xff, 0xff, 0xf0, 0x00, 0xf0, 0x01, 0xff, 0xff, 0xff,
	0xff, 0xff, 0xff, 0xe0, 0x1f, 0x00, 0x0f, 0xff, 0xff, 0xf8, 0x01, 0xe0, 0x03, 0xff, 0xff, 0xff,
	0xff, 0xff, 0xff, 0xf0, 0x1e, 0x00, 0x1f, 0xff, 0xff, 0xfe, 0x01, 0xc0, 0x07, 0xff, 0xff, 0xff,
	0xff, 0xff, 0xff, 0xfc, 0x0c, 0x00, 0x7f, 0xff, 0xff, 0xff, 0x00, 0x80, 0x0f, 0xff, 0xff, 0xff,
	0xff, 0xff, 0xff, 0xfe, 0x00, 0x01, 0xff, 0xff, 0xff, 0xff, 0xc0, 0x00, 0x3f, 0xff, 0xff, 0xff,
	0xff, 0xff, 0xff, 0xff, 0xc0, 0x07, 0xff, 0xff, 0xff, 0xff, 0xf0, 0x00, 0xff, 0xff, 0xff, 0xff,
	0xff, 0xff, 0xff, 0xff, 0xff, 0xff, 0xff, 0xff, 0xff, 0xff, 0xff, 0xff, 0xff, 0xff, 0xff, 0xff,
	0xff, 0xff, 0xff, 0xf0, 0x0f, 0xff, 0xff, 0xff, 0xff, 0xe7, 0xff, 0xf8, 0x03, 0xff, 0xff, 0xff,
	0xff, 0xff, 0xff, 0x80, 0x01, 0xff, 0xf3, 0xff, 0xff, 0xcf, 0xff, 0xc0, 0x00, 0xff, 0xff, 0xff,
	0xff, 0xff, 0xff, 0x00, 0x00, 0xff, 0xf0, 0xff, 0xff, 0x9f, 0xff, 0x80, 0x00, 0x3f, 0xff, 0xff,
	0xff, 0xff, 0xfe, 0x00, 0x00, 0x7f, 0xf8, 0x3f, 0xfe, 0x1f, 0xff, 0x80, 0x00, 0x3f, 0xff, 0xff,
	0xff, 0xff, 0xfe, 0x00, 0x00, 0xff, 0xf8, 0x03, 0xe0, 0x0f, 0xff, 0x80, 0x00, 0x3f, 0xff, 0xff,
	0xff, 0xff, 0xff, 0x00, 0x00, 0xff, 0xfe, 0x00, 0x00, 0x8f, 0xff, 0xc0, 0x00, 0x7f, 0xff, 0xff,
	0xff, 0xff, 0xff, 0xc0, 0x03, 0xff, 0xff, 0x00, 0x07, 0x9f, 0xff, 0xe0, 0x00, 0xff, 0xff, 0xff,
	0xff, 0xff, 0xff, 0xfc, 0x7f, 0xff, 0xff, 0x81, 0xff, 0x1f, 0xff, 0xfe, 0x1f, 0xff, 0xff, 0xff,
	0xff, 0xff, 0xff, 0xff, 0xff, 0xff, 0xff, 0xe0, 0x7e, 0x3f, 0xff, 0xff, 0xff, 0xff, 0xff, 0xff,
	0xff, 0xff, 0xff, 0xff, 0xff, 0xff, 0xff, 0xfc, 0x00, 0x7f, 0xff, 0xff, 0xff, 0xff, 0xff, 0xff,
	0xff, 0xff, 0xff, 0xff, 0xff, 0xff, 0xff, 0xff, 0x01, 0xff, 0xff, 0xff, 0xff, 0xff, 0xff, 0xff,
	0xff, 0xff, 0xff, 0xff, 0xff, 0xff, 0xff, 0xff, 0xff, 0xff, 0xff, 0xff, 0xff, 0xff, 0xff, 0xff,
	0xff, 0xff, 0xff, 0xff, 0xff, 0xff, 0xff, 0xff, 0xff, 0xff, 0xff, 0xff, 0xff, 0xff, 0xff, 0xff,
	0xff, 0xff, 0xff, 0xff, 0xff, 0xff, 0xff, 0xff, 0xff, 0xff, 0xff, 0xff, 0xff, 0xff, 0xff, 0xff,
	0xff, 0xff, 0xff, 0xff, 0xff, 0xff, 0xff, 0xff, 0xff, 0xff, 0xff, 0xff, 0xff, 0xff, 0xff, 0xff,
	0xff, 0xff, 0xff, 0xff, 0xff, 0xff, 0xff, 0xff, 0xff, 0xff, 0xff, 0xff, 0xff, 0xff, 0xff, 0xff,
	0xff, 0xff, 0xff, 0xff, 0xff, 0xff, 0xff, 0xff, 0xff, 0xff, 0xff, 0xff, 0xff, 0xff, 0xff, 0xff,
	0xff, 0xff, 0xff, 0xff, 0xff, 0xff, 0xff, 0xff, 0xff, 0xff, 0xff, 0xff, 0xff, 0xff, 0xff, 0xff,
	0xff, 0xff, 0xff, 0xff, 0xff, 0xff, 0xff, 0xff, 0xff, 0xff, 0xff, 0xff, 0xff, 0xff, 0xff, 0xff,
	0xff, 0xff, 0xff, 0xff, 0xff, 0xff, 0xff, 0xff, 0xff, 0xff, 0xff, 0xff, 0xff, 0xff, 0xff, 0xff,
	0xff, 0xff, 0xff, 0xff, 0xff, 0xff, 0xff, 0xff, 0xff, 0xff, 0xff, 0xff, 0xff, 0xff, 0xff, 0xff,
	0xff, 0xff, 0xff, 0xff, 0xff, 0xff, 0xff, 0xff, 0xff, 0xff, 0xff, 0xff, 0xff, 0xff, 0xff, 0xff,
	0xff, 0xff, 0xff, 0xff, 0xff, 0xff, 0xff, 0xff, 0xff, 0xff, 0xff, 0xff, 0xff, 0xff, 0xff, 0xff,
	0xff, 0xff, 0xff, 0xff, 0xff, 0xff, 0xff, 0xff, 0xff, 0xff, 0xff, 0xff, 0xff, 0xff, 0xff, 0xff,
	0xff, 0xff, 0xff, 0xff, 0xff, 0xff, 0xff, 0xff, 0xff, 0xff, 0xff, 0xff, 0xff, 0xff, 0xff, 0xff,
	0xff, 0xff, 0xff, 0xff, 0xff, 0xff, 0xff, 0xff, 0xff, 0xff, 0xff, 0xff, 0xff, 0xff, 0xff, 0xff,
	0xff, 0xff, 0xff, 0xff, 0xff, 0xff, 0xff, 0xff, 0xff, 0xff, 0xff, 0xff, 0xff, 0xff, 0xff, 0xff,
	0xff, 0xff, 0xff, 0xff, 0xff, 0xff, 0xff, 0xff, 0xff, 0xff, 0xff, 0xff, 0xff, 0xff, 0xff, 0xff
};
// 'oye', 128x64px
const unsigned char oye [] = {
	0xff, 0xff, 0xff, 0xff, 0xff, 0xff, 0xff, 0xff, 0xff, 0xff, 0xff, 0xff, 0xff, 0xff, 0xff, 0xff,
	0xff, 0xff, 0xff, 0xff, 0xff, 0xff, 0xff, 0xff, 0xff, 0xff, 0xff, 0xff, 0xff, 0xff, 0xff, 0xff,
	0xff, 0xff, 0xff, 0xff, 0xff, 0xff, 0xff, 0xff, 0xff, 0xff, 0xff, 0xff, 0xff, 0xff, 0xff, 0xff,
	0xff, 0xff, 0xff, 0xff, 0xff, 0xff, 0xff, 0xff, 0xff, 0xff, 0xff, 0xff, 0xff, 0xff, 0xff, 0xff,
	0xff, 0xff, 0xff, 0xff, 0xff, 0xff, 0xff, 0xff, 0xff, 0xff, 0xff, 0xff, 0xff, 0xff, 0xff, 0xff,
	0xff, 0xff, 0xff, 0xff, 0xff, 0xff, 0xff, 0xff, 0xff, 0xff, 0xff, 0xff, 0xff, 0xff, 0xff, 0xff,
	0xff, 0xff, 0xff, 0xff, 0xff, 0xc7, 0xff, 0xff, 0xff, 0xf8, 0xff, 0xff, 0xff, 0xff, 0xff, 0xff,
	0xff, 0xff, 0xff, 0xff, 0xff, 0x80, 0xff, 0xff, 0xff, 0xe0, 0x3f, 0xff, 0xff, 0xff, 0xff, 0xff,
	0xff, 0xff, 0xff, 0xff, 0xff, 0x00, 0x3f, 0xff, 0xff, 0x00, 0x1f, 0xff, 0xff, 0xff, 0xff, 0xff,
	0xff, 0xff, 0xff, 0xff, 0xff, 0x80, 0x07, 0xff, 0xfc, 0x00, 0x3f, 0xff, 0xff, 0xff, 0xff, 0xff,
	0xff, 0xff, 0xff, 0xff, 0xff, 0xf0, 0x01, 0xfd, 0xe0, 0x03, 0xff, 0xff, 0xff, 0xff, 0xff, 0xff,
	0xff, 0xff, 0xff, 0xff, 0xff, 0x9e, 0x00, 0x2f, 0x80, 0x1e, 0x7f, 0xff, 0xff, 0xff, 0xff, 0xff,
	0xff, 0xff, 0xff, 0xff, 0xff, 0xe3, 0xc0, 0x0c, 0x00, 0xf1, 0xbf, 0xff, 0xff, 0xff, 0xff, 0xff,
	0xff, 0xff, 0xff, 0xff, 0xff, 0x7c, 0x7c, 0x1e, 0x0f, 0x8f, 0xbf, 0xff, 0xff, 0xff, 0xff, 0xff,
	0xff, 0xff, 0xff, 0xff, 0xff, 0x7f, 0xc7, 0xff, 0xf8, 0xff, 0xff, 0xff, 0xff, 0xff, 0xff, 0xff,
	0xff, 0xff, 0xff, 0xff, 0xff, 0xff, 0xfc, 0x0e, 0x0f, 0xff, 0xff, 0xff, 0xff, 0xff, 0xff, 0xff,
	0xff, 0xff, 0xff, 0xff, 0xff, 0xff, 0xff, 0xff, 0xff, 0xff, 0xff, 0xff, 0xff, 0xff, 0xff, 0xff,
	0xff, 0xff, 0xff, 0xff, 0xff, 0xff, 0xff, 0xff, 0xff, 0xff, 0xff, 0xff, 0xff, 0xff, 0xff, 0xff,
	0xff, 0xff, 0xff, 0xff, 0xff, 0xff, 0xff, 0xff, 0xff, 0xff, 0xff, 0xff, 0xff, 0xff, 0xff, 0xff,
	0xff, 0xff, 0xff, 0xff, 0xff, 0xff, 0xff, 0xff, 0xff, 0xff, 0xff, 0xff, 0xff, 0xff, 0xff, 0xff,
	0xff, 0xff, 0xff, 0xff, 0xff, 0xff, 0xff, 0xff, 0xff, 0xff, 0xff, 0xff, 0xff, 0xff, 0xff, 0xff,
	0xff, 0xff, 0xff, 0xff, 0xff, 0xff, 0xdf, 0xff, 0xfe, 0x7f, 0xff, 0xff, 0xff, 0xff, 0xff, 0xff,
	0xff, 0xff, 0xff, 0xff, 0xff, 0xff, 0xdf, 0xff, 0xff, 0xff, 0xff, 0xff, 0xff, 0xff, 0xff, 0xff,
	0xff, 0xff, 0xff, 0xff, 0xff, 0xff, 0xff, 0xff, 0xff, 0xff, 0xff, 0xff, 0xff, 0xff, 0xff, 0xff,
	0xff, 0xff, 0xff, 0xff, 0xff, 0xff, 0xff, 0xff, 0xff, 0xff, 0xff, 0xff, 0xff, 0xff, 0xff, 0xff,
	0xff, 0xff, 0xff, 0xff, 0xff, 0xff, 0xff, 0xff, 0xff, 0xff, 0xff, 0xff, 0xff, 0xff, 0xff, 0xff,
	0xff, 0xff, 0xff, 0xff, 0xff, 0xff, 0xff, 0xff, 0xff, 0xff, 0xff, 0xff, 0xff, 0xff, 0xff, 0xff,
	0xff, 0xff, 0xff, 0xff, 0xff, 0xff, 0xff, 0xff, 0xff, 0xff, 0xff, 0xff, 0xff, 0xff, 0xff, 0xff,
	0xff, 0xff, 0xff, 0xff, 0xff, 0xff, 0xff, 0xff, 0xff, 0xff, 0xff, 0xff, 0xff, 0xff, 0xff, 0xff,
	0xff, 0xff, 0xff, 0xff, 0xff, 0xff, 0xff, 0xff, 0xfb, 0xff, 0xff, 0xff, 0xff, 0xff, 0xff, 0xff,
	0xff, 0xff, 0xff, 0xff, 0xff, 0xff, 0xff, 0xff, 0xfc, 0x3f, 0xff, 0xff, 0xff, 0xff, 0xff, 0xff,
	0xff, 0xff, 0xff, 0xff, 0xff, 0xff, 0xff, 0xff, 0xff, 0xff, 0xff, 0xff, 0xff, 0xff, 0xff, 0xff,
	0xff, 0xff, 0xff, 0xff, 0xff, 0xff, 0xff, 0xff, 0xfe, 0xff, 0xff, 0xff, 0xff, 0xff, 0xff, 0xff,
	0xff, 0xff, 0xff, 0xff, 0xff, 0xff, 0xff, 0xff, 0xff, 0x7f, 0xff, 0xff, 0xff, 0xff, 0xff, 0xff,
	0xff, 0xff, 0xff, 0xff, 0xff, 0xff, 0xf7, 0xff, 0xff, 0xff, 0xff, 0xff, 0xff, 0xff, 0xff, 0xff,
	0xff, 0xff, 0xff, 0xff, 0xff, 0xff, 0xff, 0xff, 0xff, 0xbf, 0xff, 0xff, 0xff, 0xff, 0xff, 0xff,
	0xff, 0xff, 0xff, 0xff, 0xff, 0xff, 0xff, 0xff, 0xff, 0xff, 0xff, 0xff, 0xff, 0xff, 0xff, 0xff,
	0xff, 0xff, 0xff, 0xff, 0xff, 0xff, 0xff, 0xff, 0xff, 0xdf, 0xff, 0xff, 0xff, 0xff, 0xff, 0xff,
	0xff, 0xff, 0xff, 0xff, 0xff, 0xff, 0xff, 0xff, 0xff, 0xdf, 0xff, 0xff, 0xff, 0xff, 0xff, 0xff,
	0xff, 0xff, 0xff, 0xff, 0xff, 0xff, 0x7f, 0xff, 0xff, 0xcf, 0xff, 0xff, 0xff, 0xff, 0xff, 0xff,
	0xff, 0xff, 0xff, 0xff, 0xff, 0xff, 0x7f, 0xff, 0xff, 0x8f, 0xff, 0xff, 0xff, 0xff, 0xff, 0xff,
	0xff, 0xff, 0xff, 0xff, 0xff, 0xfe, 0x3f, 0xff, 0xf0, 0x0f, 0xff, 0xff, 0xff, 0xff, 0xff, 0xff,
	0xff, 0xff, 0xff, 0xff, 0xff, 0xfe, 0x00, 0x00, 0x00, 0x07, 0xff, 0xff, 0xff, 0xff, 0xff, 0xff,
	0xff, 0xff, 0xff, 0xff, 0xff, 0xfe, 0x00, 0x00, 0x00, 0x07, 0xff, 0xff, 0xff, 0xff, 0xff, 0xff,
	0xff, 0xff, 0xff, 0xff, 0xff, 0xfc, 0x00, 0x00, 0x00, 0x07, 0xff, 0xff, 0xff, 0xff, 0xff, 0xff,
	0xff, 0xff, 0xff, 0xff, 0xff, 0xfc, 0x00, 0x00, 0x00, 0x07, 0xff, 0xff, 0xff, 0xff, 0xff, 0xff,
	0xff, 0xff, 0xff, 0xff, 0xff, 0xfc, 0x00, 0x00, 0x00, 0x07, 0xff, 0xff, 0xff, 0xff, 0xff, 0xff,
	0xff, 0xff, 0xff, 0xff, 0xff, 0xfc, 0x00, 0x00, 0x00, 0x03, 0xff, 0xff, 0xff, 0xff, 0xff, 0xff,
	0xff, 0xff, 0xff, 0xff, 0xff, 0xfc, 0x00, 0x00, 0x00, 0x03, 0xff, 0xff, 0xff, 0xff, 0xff, 0xff,
	0xff, 0xff, 0xff, 0xff, 0xff, 0xf8, 0x00, 0x00, 0x00, 0x03, 0xff, 0xff, 0xff, 0xff, 0xff, 0xff,
	0xff, 0xff, 0xff, 0xff, 0xff, 0xf8, 0x00, 0x00, 0x00, 0x03, 0xff, 0xff, 0xff, 0xff, 0xff, 0xff,
	0xff, 0xff, 0xff, 0xff, 0xff, 0xf8, 0x00, 0x00, 0x00, 0x03, 0xff, 0xff, 0xff, 0xff, 0xff, 0xff,
	0xff, 0xff, 0xff, 0xff, 0xff, 0xfc, 0x00, 0x3e, 0x00, 0x03, 0xff, 0xff, 0xff, 0xff, 0xff, 0xff,
	0xff, 0xff, 0xff, 0xff, 0xff, 0xfc, 0x03, 0xff, 0xf0, 0x03, 0xff, 0xff, 0xff, 0xff, 0xff, 0xff,
	0xff, 0xff, 0xff, 0xff, 0xff, 0xff, 0x80, 0x00, 0x7c, 0x03, 0xff, 0xff, 0xff, 0xff, 0xff, 0xff,
	0xff, 0xff, 0xff, 0xff, 0xff, 0xff, 0xff, 0xff, 0xc0, 0x07, 0xff, 0xff, 0xff, 0xff, 0xff, 0xff,
	0xff, 0xff, 0xff, 0xff, 0xff, 0xff, 0xff, 0xff, 0xff, 0xfe, 0xff, 0xff, 0xff, 0xff, 0xff, 0xff,
	0xff, 0xff, 0xff, 0xff, 0xff, 0xff, 0xff, 0xff, 0xff, 0xfd, 0xff, 0xff, 0xff, 0xff, 0xff, 0xff,
	0xff, 0xff, 0xff, 0xff, 0xff, 0xff, 0xff, 0xff, 0xff, 0xff, 0xff, 0xff, 0xff, 0xff, 0xff, 0xff,
	0xff, 0xff, 0xff, 0xff, 0xff, 0xff, 0xff, 0xff, 0xff, 0xff, 0xff, 0xff, 0xff, 0xff, 0xff, 0xff,
	0xff, 0xff, 0xff, 0xff, 0xff, 0xff, 0xff, 0xff, 0xff, 0xff, 0xff, 0xff, 0xff, 0xff, 0xff, 0xff,
	0xff, 0xff, 0xff, 0xff, 0xff, 0xff, 0xff, 0xff, 0xff, 0xff, 0xff, 0xff, 0xff, 0xff, 0xff, 0xff,
	0xff, 0xff, 0xff, 0xff, 0xff, 0xff, 0xff, 0xff, 0xff, 0xff, 0xff, 0xff, 0xff, 0xff, 0xff, 0xff,
	0xff, 0xff, 0xff, 0xff, 0xff, 0xff, 0xff, 0xff, 0xff, 0xff, 0xff, 0xff, 0xff, 0xff, 0xff, 0xff
};

// 'triste', 128x64px
const unsigned char triste [] = {
	0xff, 0xff, 0xff, 0xff, 0xff, 0xff, 0xff, 0xff, 0xff, 0xff, 0xff, 0xff, 0xff, 0xff, 0xff, 0xff,
	0xff, 0xff, 0xff, 0xff, 0xff, 0xff, 0xff, 0xff, 0xff, 0xff, 0xff, 0xff, 0xff, 0xff, 0xff, 0xff,
	0xff, 0xff, 0xff, 0xff, 0xff, 0xff, 0xff, 0xff, 0xff, 0xff, 0xff, 0xff, 0xff, 0xff, 0xff, 0xff,
	0xff, 0xff, 0xff, 0xff, 0xff, 0xff, 0xff, 0xff, 0xff, 0xff, 0xff, 0xff, 0xff, 0xff, 0xff, 0xff,
	0xff, 0xff, 0xff, 0xff, 0xff, 0xff, 0xff, 0xff, 0xff, 0xff, 0xff, 0xff, 0xff, 0xff, 0xff, 0xff,
	0xff, 0xff, 0xff, 0xff, 0xff, 0xff, 0xff, 0xff, 0xff, 0xff, 0xff, 0xff, 0xff, 0xff, 0xff, 0xff,
	0xff, 0xff, 0xff, 0xff, 0xff, 0xff, 0xff, 0xff, 0xff, 0xff, 0xff, 0xff, 0xff, 0xff, 0xff, 0xff,
	0xff, 0xff, 0xff, 0xff, 0xff, 0xff, 0xff, 0xff, 0xff, 0xff, 0xff, 0xff, 0xff, 0xff, 0xff, 0xff,
	0xff, 0xff, 0xff, 0xff, 0xff, 0xff, 0xff, 0xff, 0xff, 0xff, 0xff, 0xff, 0xff, 0xff, 0xff, 0xff,
	0xff, 0xff, 0xff, 0xff, 0xff, 0xff, 0xff, 0xff, 0xff, 0xff, 0xff, 0xff, 0xff, 0xff, 0xff, 0xff,
	0xff, 0xff, 0xff, 0xff, 0xff, 0xff, 0xff, 0xff, 0xff, 0xff, 0xff, 0xff, 0xff, 0xff, 0xff, 0xff,
	0xff, 0xff, 0xff, 0xff, 0xff, 0xff, 0xff, 0xff, 0xff, 0xff, 0xff, 0xff, 0xff, 0xff, 0xff, 0xff,
	0xff, 0xff, 0xff, 0xff, 0xff, 0xff, 0xff, 0xff, 0xff, 0xff, 0xff, 0xff, 0xff, 0xff, 0xff, 0xff,
	0xff, 0xff, 0xff, 0xff, 0xff, 0xff, 0xff, 0xff, 0xff, 0xff, 0xff, 0xff, 0xff, 0xff, 0xff, 0xff,
	0xff, 0xff, 0xff, 0xff, 0xff, 0xff, 0xfb, 0xff, 0xff, 0xdf, 0xff, 0xff, 0xff, 0xff, 0xff, 0xff,
	0xff, 0xff, 0xff, 0xff, 0xff, 0xff, 0xf3, 0xff, 0xff, 0xcf, 0xff, 0xff, 0xff, 0xff, 0xff, 0xff,
	0xff, 0xff, 0xff, 0xff, 0xff, 0xff, 0xe3, 0xff, 0xff, 0xc7, 0xff, 0xff, 0xff, 0xff, 0xff, 0xff,
	0xff, 0xff, 0xff, 0xff, 0xff, 0xff, 0xe3, 0xff, 0xff, 0xc7, 0xff, 0xff, 0xff, 0xff, 0xff, 0xff,
	0xff, 0xff, 0xff, 0xff, 0xff, 0xff, 0xc7, 0xff, 0xff, 0xe3, 0xff, 0xff, 0xff, 0xff, 0xff, 0xff,
	0xff, 0xff, 0xff, 0xff, 0xff, 0xff, 0x8f, 0xff, 0xff, 0xf1, 0xff, 0xff, 0xff, 0xff, 0xff, 0xff,
	0xff, 0xff, 0xff, 0xff, 0xff, 0xff, 0x0f, 0xff, 0xff, 0xf0, 0xff, 0xff, 0xff, 0xff, 0xff, 0xff,
	0xff, 0xff, 0xff, 0xff, 0xff, 0xfe, 0x00, 0xff, 0xff, 0x00, 0x7f, 0xff, 0xff, 0xff, 0xff, 0xff,
	0xff, 0xff, 0xff, 0xff, 0xff, 0xfc, 0x06, 0x7f, 0xfe, 0x60, 0x3f, 0xff, 0xff, 0xff, 0xff, 0xff,
	0xff, 0xff, 0xff, 0xff, 0xff, 0xf8, 0x9f, 0x3f, 0xfc, 0xf9, 0x1f, 0xff, 0xff, 0xff, 0xff, 0xff,
	0xff, 0xff, 0xff, 0xff, 0xff, 0xf1, 0x9f, 0x3f, 0xfc, 0xf9, 0xcf, 0xff, 0xff, 0xff, 0xff, 0xff,
	0xff, 0xff, 0xff, 0xff, 0xff, 0xc7, 0x8c, 0x3f, 0xfc, 0x31, 0xe3, 0xff, 0xff, 0xff, 0xff, 0xff,
	0xff, 0xff, 0xff, 0xff, 0xff, 0x9f, 0x8e, 0x3f, 0xfc, 0x71, 0xf9, 0xff, 0xff, 0xff, 0xff, 0xff,
	0xff, 0xff, 0xff, 0xff, 0xff, 0x7f, 0x80, 0x7f, 0xfe, 0x01, 0xfe, 0xff, 0xff, 0xff, 0xff, 0xff,
	0xff, 0xff, 0xff, 0xff, 0xff, 0xff, 0xc0, 0x7f, 0xfe, 0x03, 0xff, 0xff, 0xff, 0xff, 0xff, 0xff,
	0xff, 0xff, 0xff, 0xff, 0xff, 0xff, 0xf1, 0xff, 0xff, 0x8f, 0xff, 0xff, 0xff, 0xff, 0xff, 0xff,
	0xff, 0xff, 0xff, 0xff, 0xff, 0xff, 0xff, 0xff, 0xff, 0xff, 0xff, 0xff, 0xff, 0xff, 0xff, 0xff,
	0xff, 0xff, 0xff, 0xff, 0xff, 0xff, 0xff, 0xff, 0xff, 0xff, 0xff, 0xff, 0xff, 0xff, 0xff, 0xff,
	0xff, 0xff, 0xff, 0xff, 0xff, 0xff, 0xff, 0xff, 0xff, 0xff, 0xff, 0xff, 0xff, 0xff, 0xff, 0xff,
	0xff, 0xff, 0xff, 0xff, 0xff, 0x9f, 0xff, 0xff, 0xff, 0xff, 0xf9, 0xff, 0xff, 0xff, 0xff, 0xff,
	0xff, 0xff, 0xff, 0xff, 0xff, 0x83, 0xff, 0xff, 0xff, 0xff, 0xc1, 0xff, 0xff, 0xff, 0xff, 0xff,
	0xff, 0xff, 0xff, 0xff, 0xff, 0x81, 0xff, 0xff, 0xff, 0xff, 0x83, 0xff, 0xff, 0xff, 0xff, 0xff,
	0xff, 0xff, 0xff, 0xff, 0xff, 0xe0, 0x7f, 0xff, 0xff, 0xfe, 0x07, 0xff, 0xff, 0xff, 0xff, 0xff,
	0xff, 0xff, 0xff, 0xff, 0xff, 0xe0, 0x3f, 0xff, 0xff, 0xf8, 0x0f, 0xff, 0xff, 0xff, 0xff, 0xff,
	0xff, 0xff, 0xff, 0xff, 0xff, 0xe0, 0x1f, 0xf7, 0xdf, 0xf8, 0x1f, 0xff, 0xff, 0xff, 0xff, 0xff,
	0xff, 0xff, 0xff, 0xff, 0xff, 0xe6, 0x3f, 0xff, 0xff, 0xfc, 0x7f, 0xff, 0xff, 0xff, 0xff, 0xff,
	0xff, 0xff, 0xff, 0xff, 0xff, 0xe7, 0xff, 0xff, 0xff, 0xff, 0xff, 0xff, 0xff, 0xff, 0xff, 0xff,
	0xff, 0xff, 0xff, 0xff, 0xff, 0xe7, 0xff, 0xff, 0xff, 0xff, 0xff, 0xff, 0xff, 0xff, 0xff, 0xff,
	0xff, 0xff, 0xff, 0xff, 0xff, 0xe7, 0xff, 0xff, 0xff, 0xff, 0xf7, 0xff, 0xff, 0xff, 0xff, 0xff,
	0xff, 0xff, 0xff, 0xff, 0xff, 0xc7, 0xff, 0xff, 0xff, 0xff, 0xe7, 0xff, 0xff, 0xff, 0xff, 0xff,
	0xff, 0xff, 0xff, 0xff, 0xff, 0xc7, 0xff, 0xff, 0xff, 0xff, 0xe3, 0xff, 0xff, 0xff, 0xff, 0xff,
	0xff, 0xff, 0xff, 0xff, 0xff, 0xc7, 0xff, 0xff, 0xff, 0xff, 0xe3, 0xff, 0xff, 0xff, 0xff, 0xff,
	0xff, 0xff, 0xff, 0xff, 0xff, 0x87, 0xff, 0xff, 0xff, 0xff, 0xe3, 0xff, 0xff, 0xff, 0xff, 0xff,
	0xff, 0xff, 0xff, 0xff, 0xff, 0x87, 0xff, 0xff, 0xff, 0xff, 0xc3, 0xff, 0xff, 0xff, 0xff, 0xff,
	0xff, 0xff, 0xff, 0xff, 0xff, 0x83, 0xff, 0xff, 0xff, 0xff, 0xc1, 0xff, 0xff, 0xff, 0xff, 0xff,
	0xff, 0xff, 0xff, 0xff, 0xff, 0x83, 0xff, 0xff, 0xff, 0xff, 0xc1, 0xff, 0xff, 0xff, 0xff, 0xff,
	0xff, 0xff, 0xff, 0xff, 0xff, 0x83, 0xff, 0xff, 0xff, 0xff, 0xc3, 0xff, 0xff, 0xff, 0xff, 0xff,
	0xff, 0xff, 0xff, 0xff, 0xff, 0xc7, 0xff, 0xff, 0xff, 0xff, 0xe3, 0xff, 0xff, 0xff, 0xff, 0xff,
	0xff, 0xff, 0xff, 0xff, 0xff, 0xef, 0xff, 0xff, 0xff, 0xff, 0xf7, 0xff, 0xff, 0xff, 0xff, 0xff,
	0xff, 0xff, 0xff, 0xff, 0xff, 0xff, 0xff, 0xff, 0xff, 0xff, 0xff, 0xff, 0xff, 0xff, 0xff, 0xff,
	0xff, 0xff, 0xff, 0xff, 0xff, 0xff, 0xff, 0xff, 0xff, 0xff, 0xff, 0xff, 0xff, 0xff, 0xff, 0xff,
	0xff, 0xff, 0xff, 0xff, 0xff, 0xff, 0xff, 0xff, 0xff, 0xff, 0xff, 0xff, 0xff, 0xff, 0xff, 0xff,
	0xff, 0xff, 0xff, 0xff, 0xff, 0xff, 0xff, 0xff, 0xff, 0xff, 0xff, 0xff, 0xff, 0xff, 0xff, 0xff,
	0xff, 0xff, 0xff, 0xff, 0xff, 0xff, 0xff, 0xff, 0xff, 0xff, 0xff, 0xff, 0xff, 0xff, 0xff, 0xff,
	0xff, 0xff, 0xff, 0xff, 0xff, 0xff, 0xff, 0xff, 0xff, 0xff, 0xff, 0xff, 0xff, 0xff, 0xff, 0xff,
	0xff, 0xff, 0xff, 0xff, 0xff, 0xff, 0xff, 0xff, 0xff, 0xff, 0xff, 0xff, 0xff, 0xff, 0xff, 0xff,
	0xff, 0xff, 0xff, 0xff, 0xff, 0xff, 0xff, 0xff, 0xff, 0xff, 0xff, 0xff, 0xff, 0xff, 0xff, 0xff,
	0xff, 0xff, 0xff, 0xff, 0xff, 0xff, 0xff, 0xff, 0xff, 0xff, 0xff, 0xff, 0xff, 0xff, 0xff, 0xff,
	0xff, 0xff, 0xff, 0xff, 0xff, 0xff, 0xff, 0xff, 0xff, 0xff, 0xff, 0xff, 0xff, 0xff, 0xff, 0xff,
	0xff, 0xff, 0xff, 0xff, 0xff, 0xff, 0xff, 0xff, 0xff, 0xff, 0xff, 0xff, 0xff, 0xff, 0xff, 0xff
};

// 'guino', 128x64px
const unsigned char guino [] = {
	0xff, 0xff, 0xff, 0xff, 0xff, 0xff, 0xff, 0xff, 0xff, 0xff, 0xff, 0xff, 0xff, 0xff, 0xff, 0xff,
	0xff, 0xff, 0xff, 0xff, 0xff, 0xff, 0xff, 0xff, 0xff, 0xff, 0xff, 0xff, 0xff, 0xff, 0xff, 0xff,
	0xff, 0xff, 0xff, 0xff, 0xff, 0xff, 0xff, 0xff, 0xff, 0xff, 0xff, 0xff, 0xff, 0xff, 0xff, 0xff,
	0xff, 0xff, 0xff, 0xff, 0xff, 0xff, 0xbf, 0xff, 0xff, 0x83, 0xff, 0xff, 0xff, 0xff, 0xff, 0xff,
	0xff, 0xff, 0xff, 0xff, 0xff, 0xfc, 0x07, 0xff, 0xfe, 0x00, 0xff, 0xff, 0xff, 0xff, 0xff, 0xff,
	0xff, 0xff, 0xff, 0xff, 0xff, 0xf0, 0x03, 0xff, 0xfc, 0x00, 0x7f, 0xff, 0xff, 0xff, 0xff, 0xff,
	0xff, 0xff, 0xff, 0xff, 0xff, 0xe0, 0x01, 0xff, 0xff, 0xf0, 0x1f, 0xff, 0xff, 0xff, 0xff, 0xff,
	0xff, 0xff, 0xff, 0xff, 0xff, 0xc0, 0xff, 0xff, 0xff, 0xfe, 0x0f, 0xff, 0xff, 0xff, 0xff, 0xff,
	0xff, 0xff, 0xff, 0xff, 0xff, 0x87, 0xff, 0xff, 0xff, 0xff, 0xc7, 0xff, 0xff, 0xff, 0xff, 0xff,
	0xff, 0xff, 0xff, 0xff, 0xff, 0x1f, 0xff, 0xff, 0xff, 0xff, 0xf3, 0xff, 0xff, 0xff, 0xff, 0xff,
	0xff, 0xff, 0xff, 0xff, 0xfe, 0x7f, 0xff, 0xff, 0xff, 0xff, 0xfd, 0xff, 0xff, 0xff, 0xff, 0xff,
	0xff, 0xff, 0xff, 0xff, 0xfd, 0xff, 0xff, 0xff, 0xff, 0xff, 0xff, 0xff, 0xff, 0xff, 0xff, 0xff,
	0xff, 0xff, 0xff, 0xff, 0xff, 0xff, 0xff, 0xff, 0xff, 0xff, 0xff, 0xff, 0xff, 0xff, 0xff, 0xff,
	0xff, 0xff, 0xff, 0xff, 0xff, 0xff, 0xff, 0xff, 0xff, 0xff, 0xff, 0xff, 0xff, 0xff, 0xff, 0xff,
	0xff, 0xff, 0xff, 0xff, 0xff, 0xff, 0xff, 0xff, 0xff, 0xe7, 0xcf, 0xff, 0xff, 0xff, 0xff, 0xff,
	0xff, 0xff, 0xff, 0xff, 0xff, 0xff, 0xff, 0xff, 0xff, 0x9f, 0xfb, 0xff, 0xff, 0xff, 0xff, 0xff,
	0xff, 0xff, 0xff, 0xff, 0xff, 0xff, 0xff, 0xff, 0xff, 0x7f, 0xfc, 0xff, 0xff, 0xff, 0xff, 0xff,
	0xff, 0xff, 0xff, 0xff, 0xff, 0xff, 0xff, 0xff, 0xff, 0xff, 0xff, 0x7f, 0xff, 0xff, 0xff, 0xff,
	0xff, 0xff, 0xff, 0xff, 0xff, 0xff, 0xff, 0xff, 0xff, 0xff, 0xff, 0xbf, 0xff, 0xff, 0xff, 0xff,
	0xff, 0xff, 0xff, 0xff, 0xff, 0xff, 0xff, 0xff, 0xfb, 0xff, 0xff, 0xff, 0xff, 0xff, 0xff, 0xff,
	0xff, 0xff, 0xff, 0xff, 0xff, 0xff, 0xff, 0xff, 0xf7, 0xff, 0xff, 0xdf, 0xff, 0xff, 0xff, 0xff,
	0xff, 0xff, 0xff, 0xff, 0xff, 0xff, 0xff, 0xff, 0xff, 0xc3, 0xff, 0xef, 0xff, 0xff, 0xff, 0xff,
	0xff, 0xff, 0xff, 0xff, 0xff, 0xff, 0xff, 0xff, 0xef, 0x80, 0xff, 0xef, 0xff, 0xff, 0xff, 0xff,
	0xff, 0xff, 0xff, 0xff, 0xff, 0xff, 0xff, 0xff, 0xef, 0x00, 0xff, 0xff, 0xff, 0xff, 0xff, 0xff,
	0xff, 0xff, 0xff, 0xff, 0xff, 0xff, 0xff, 0xff, 0xff, 0x60, 0x7f, 0xff, 0xff, 0xff, 0xff, 0xff,
	0xff, 0xff, 0xff, 0xff, 0xff, 0xff, 0xff, 0xff, 0xff, 0x70, 0x7f, 0xf7, 0xff, 0xff, 0xff, 0xff,
	0xff, 0xff, 0xff, 0xff, 0xff, 0xff, 0xff, 0xff, 0xff, 0x00, 0x7f, 0xf7, 0xff, 0xff, 0xff, 0xff,
	0xff, 0xff, 0xff, 0xff, 0xfc, 0x03, 0xff, 0xff, 0xff, 0x00, 0x7f, 0xf7, 0xff, 0xff, 0xff, 0xff,
	0xff, 0xff, 0xff, 0xff, 0xc0, 0x00, 0x3f, 0xff, 0xff, 0x80, 0xff, 0xf7, 0xff, 0xff, 0xff, 0xff,
	0xff, 0xff, 0xff, 0xff, 0x00, 0x00, 0x0f, 0xff, 0xff, 0xc1, 0xff, 0xff, 0xff, 0xff, 0xff, 0xff,
	0xff, 0xff, 0xff, 0xfe, 0x00, 0x00, 0x03, 0xff, 0xef, 0xff, 0xe1, 0xff, 0xff, 0xff, 0xff, 0xff,
	0xff, 0xff, 0xff, 0xff, 0xff, 0xff, 0x01, 0xff, 0xef, 0xfc, 0x00, 0x0f, 0xff, 0xff, 0xff, 0xff,
	0xff, 0xff, 0xff, 0xff, 0xff, 0xff, 0xe0, 0xff, 0xff, 0xe0, 0x00, 0x07, 0xff, 0xff, 0xff, 0xff,
	0xff, 0xff, 0xff, 0xff, 0xff, 0xff, 0xfc, 0x7f, 0xff, 0x81, 0xff, 0xff, 0xff, 0xff, 0xff, 0xff,
	0xff, 0xff, 0xff, 0xff, 0xff, 0xff, 0xff, 0x3f, 0xfa, 0x1f, 0xff, 0xff, 0xff, 0xff, 0xff, 0xff,
	0xff, 0xff, 0xff, 0xff, 0xff, 0xff, 0xff, 0xdf, 0xf9, 0xff, 0xff, 0xff, 0xff, 0xff, 0xff, 0xff,
	0xff, 0xff, 0xff, 0xff, 0xff, 0xff, 0xff, 0xff, 0xff, 0xff, 0xff, 0xff, 0xff, 0xff, 0xff, 0xff,
	0xff, 0xff, 0xff, 0xff, 0xff, 0xff, 0xff, 0xff, 0xff, 0xff, 0xff, 0xff, 0xff, 0xff, 0xff, 0xff,
	0xff, 0xff, 0xff, 0xff, 0xff, 0xff, 0xff, 0xff, 0xff, 0xff, 0xff, 0xff, 0xff, 0xff, 0xff, 0xff,
	0xff, 0xff, 0xff, 0xff, 0xff, 0xff, 0xfd, 0xff, 0xff, 0xff, 0xff, 0xff, 0xff, 0xff, 0xff, 0xff,
	0xff, 0xff, 0xff, 0xff, 0xff, 0xff, 0xfc, 0xff, 0xff, 0xff, 0xff, 0xff, 0xff, 0xff, 0xff, 0xff,
	0xff, 0xff, 0xff, 0xff, 0xff, 0xff, 0xfc, 0x7f, 0xff, 0x7f, 0xff, 0xff, 0xff, 0xff, 0xff, 0xff,
	0xff, 0xff, 0xff, 0xff, 0xff, 0xff, 0xfc, 0x1f, 0xfe, 0xff, 0xff, 0xff, 0xff, 0xff, 0xff, 0xff,
	0xff, 0xff, 0xff, 0xff, 0xff, 0xff, 0xfc, 0x07, 0xf8, 0xff, 0xff, 0xff, 0xff, 0xff, 0xff, 0xff,
	0xff, 0xff, 0xff, 0xff, 0xff, 0xff, 0xfc, 0x00, 0x00, 0xff, 0xff, 0xff, 0xff, 0xff, 0xff, 0xff,
	0xff, 0xff, 0xff, 0xff, 0xff, 0xff, 0xfc, 0x00, 0x01, 0xff, 0xff, 0xff, 0xff, 0xff, 0xff, 0xff,
	0xff, 0xff, 0xff, 0xff, 0xff, 0xff, 0xfc, 0x00, 0x01, 0xff, 0xff, 0xff, 0xff, 0xff, 0xff, 0xff,
	0xff, 0xff, 0xff, 0xff, 0xff, 0xff, 0xfe, 0x00, 0x01, 0xff, 0xff, 0xff, 0xff, 0xff, 0xff, 0xff,
	0xff, 0xff, 0xff, 0xff, 0xff, 0xff, 0xfe, 0x00, 0x03, 0xff, 0xff, 0xff, 0xff, 0xff, 0xff, 0xff,
	0xff, 0xff, 0xff, 0xff, 0xff, 0xff, 0xfe, 0x00, 0x03, 0xff, 0xff, 0xff, 0xff, 0xff, 0xff, 0xff,
	0xff, 0xff, 0xff, 0xff, 0xff, 0xff, 0xfe, 0x00, 0x03, 0xff, 0xff, 0xff, 0xff, 0xff, 0xff, 0xff,
	0xff, 0xff, 0xff, 0xff, 0xff, 0xff, 0xff, 0x00, 0x03, 0xff, 0xff, 0xff, 0xff, 0xff, 0xff, 0xff,
	0xff, 0xff, 0xff, 0xff, 0xff, 0xff, 0xff, 0x00, 0x01, 0xff, 0xff, 0xff, 0xff, 0xff, 0xff, 0xff,
	0xff, 0xff, 0xff, 0xff, 0xff, 0xff, 0xff, 0x80, 0x00, 0xff, 0xff, 0xff, 0xff, 0xff, 0xff, 0xff,
	0xff, 0xff, 0xff, 0xff, 0xff, 0xff, 0xff, 0x80, 0x00, 0xff, 0xff, 0xff, 0xff, 0xff, 0xff, 0xff,
	0xff, 0xff, 0xff, 0xff, 0xff, 0xff, 0xff, 0xc0, 0x00, 0xff, 0xff, 0xff, 0xff, 0xff, 0xff, 0xff,
	0xff, 0xff, 0xff, 0xff, 0xff, 0xff, 0xff, 0xe0, 0x01, 0xff, 0xff, 0xff, 0xff, 0xff, 0xff, 0xff,
	0xff, 0xff, 0xff, 0xff, 0xff, 0xff, 0xff, 0xf8, 0x07, 0xff, 0xff, 0xff, 0xff, 0xff, 0xff, 0xff,
	0xff, 0xff, 0xff, 0xff, 0xff, 0xff, 0xff, 0xff, 0xff, 0xff, 0xff, 0xff, 0xff, 0xff, 0xff, 0xff,
	0xff, 0xff, 0xff, 0xff, 0xff, 0xff, 0xff, 0xff, 0xff, 0xff, 0xff, 0xff, 0xff, 0xff, 0xff, 0xff,
	0xff, 0xff, 0xff, 0xff, 0xff, 0xff, 0xff, 0xff, 0xff, 0xff, 0xff, 0xff, 0xff, 0xff, 0xff, 0xff,
	0xff, 0xff, 0xff, 0xff, 0xff, 0xff, 0xff, 0xff, 0xff, 0xff, 0xff, 0xff, 0xff, 0xff, 0xff, 0xff,
	0xff, 0xff, 0xff, 0xff, 0xff, 0xff, 0xff, 0xff, 0xff, 0xff, 0xff, 0xff, 0xff, 0xff, 0xff, 0xff,
	0xff, 0xff, 0xff, 0xff, 0xff, 0xff, 0xff, 0xff, 0xff, 0xff, 0xff, 0xff, 0xff, 0xff, 0xff, 0xff
};

//Definimos el tamano del buffer donde se va a almacenar el menu
#define MENU_BUFFER_SIZE 1150
//Definimos la variable que nos indica el tamano de los buffer recibidos
#define UART_RX_BUFFER_SIZE 64
//Definimos el numero de capitulos posible
#define NUM_OPCIONES 3
char* opciones_menu[NUM_OPCIONES] = {
    "Cap 1. Dos seres",
    "Cap 2. La mar...",
    "Cap 3. El origen"
};
//Variable para contar los periodos del Timer3
volatile uint8_t contador=0;

//Variable para asignar la opcion actual de capitulo
volatile uint8_t opcion_actual =0;

/* USER CODE END PV */

void SystemClock_Config(void);
static void MX_GPIO_Init(void);
static void MX_USART2_UART_Init(void);
static void MX_TIM2_Init(void);
static void MX_I2C1_Init(void);
static void MX_TIM3_Init(void);
static void MX_TIM4_Init(void);
static void MX_TIM5_Init(void);
static void MX_TIM9_Init(void);
static void MX_TIM10_Init(void);
/* USER CODE BEGIN PFP */
//Funcion de maquina de estados
void maquinaEstados (void);
//Funciones para definir las acciones de cada capitulo
void acciones1 (void);
void acciones2 (void);
void acciones3 (void);
//Funcion para mostrar el menu en pantalla
void mostrar_menu (void);
//Funcion para cambiar la opcion_actual
uint16_t cambioNumero (uint16_t numeroLocal);
//Funcion para dar inicio al show
void queComienceElShow (void);
/* USER CODE END PFP */

int main(void)
{

  /* MCU Configuration--------------------------------------------------------*/

  /* Reset of all peripherals, Initializes the Flash interface and the Systick. */
  HAL_Init();

  /* Configure the system clock */
  SystemClock_Config();

  /* Initialize all configured peripherals */
  MX_GPIO_Init();
  MX_USART2_UART_Init();
  MX_TIM2_Init();
  MX_I2C1_Init();
  MX_TIM3_Init();
  MX_TIM4_Init();
  MX_TIM5_Init();
  MX_TIM9_Init();
  MX_TIM10_Init();
  /* USER CODE BEGIN 2 */
  //Inicializamos los timers y sus interrupciones
  HAL_TIM_Base_Start_IT(&htim2);
  //Inicializamos la pantalla
  ssd1306_Init();
  //Inicializamos el timer y su respectivo PWM para el motor
  HAL_GPIO_WritePin(enable_GPIO_Port, enable_Pin, GPIO_PIN_SET);
  HAL_TIM_Base_Start(&htim4);
  HAL_TIM_PWM_Start(&htim4, TIM_CHANNEL_2);
  fsm.estado = menu;
  HAL_TIM_PWM_Stop(&htim4, TIM_CHANNEL_2);

  /* USER CODE END 2 */

  /* Infinite loop */
  while (1)
  {

    /* USER CODE BEGIN 3 */
		  maquinaEstados();
	  }

  /* USER CODE END 3 */
}

void SystemClock_Config(void)
{
  RCC_OscInitTypeDef RCC_OscInitStruct = {0};
  RCC_ClkInitTypeDef RCC_ClkInitStruct = {0};

  /** Configure the main internal regulator output voltage
  */
  __HAL_RCC_PWR_CLK_ENABLE();
  __HAL_PWR_VOLTAGESCALING_CONFIG(PWR_REGULATOR_VOLTAGE_SCALE1);

  /** Initializes the RCC Oscillators according to the specified parameters
  * in the RCC_OscInitTypeDef structure.
  */
  RCC_OscInitStruct.OscillatorType = RCC_OSCILLATORTYPE_HSI;
  RCC_OscInitStruct.HSIState = RCC_HSI_ON;
  RCC_OscInitStruct.HSICalibrationValue = RCC_HSICALIBRATION_DEFAULT;
  RCC_OscInitStruct.PLL.PLLState = RCC_PLL_NONE;
  if (HAL_RCC_OscConfig(&RCC_OscInitStruct) != HAL_OK)
  {
    Error_Handler();
  }

  /** Initializes the CPU, AHB and APB buses clocks
  */
  RCC_ClkInitStruct.ClockType = RCC_CLOCKTYPE_HCLK|RCC_CLOCKTYPE_SYSCLK
                              |RCC_CLOCKTYPE_PCLK1|RCC_CLOCKTYPE_PCLK2;
  RCC_ClkInitStruct.SYSCLKSource = RCC_SYSCLKSOURCE_HSI;
  RCC_ClkInitStruct.AHBCLKDivider = RCC_SYSCLK_DIV1;
  RCC_ClkInitStruct.APB1CLKDivider = RCC_HCLK_DIV2;
  RCC_ClkInitStruct.APB2CLKDivider = RCC_HCLK_DIV1;

  if (HAL_RCC_ClockConfig(&RCC_ClkInitStruct, FLASH_LATENCY_0) != HAL_OK)
  {
    Error_Handler();
  }
}

static void MX_I2C1_Init(void)
{

  hi2c1.Instance = I2C1;
  hi2c1.Init.ClockSpeed = 400000;
  hi2c1.Init.DutyCycle = I2C_DUTYCYCLE_16_9;
  hi2c1.Init.OwnAddress1 = 0;
  hi2c1.Init.AddressingMode = I2C_ADDRESSINGMODE_7BIT;
  hi2c1.Init.DualAddressMode = I2C_DUALADDRESS_DISABLE;
  hi2c1.Init.OwnAddress2 = 0;
  hi2c1.Init.GeneralCallMode = I2C_GENERALCALL_DISABLE;
  hi2c1.Init.NoStretchMode = I2C_NOSTRETCH_DISABLE;
  if (HAL_I2C_Init(&hi2c1) != HAL_OK)
  {
    Error_Handler();
  }

}

static void MX_TIM2_Init(void)
{

  TIM_ClockConfigTypeDef sClockSourceConfig = {0};
  TIM_MasterConfigTypeDef sMasterConfig = {0};

  htim2.Instance = TIM2;
  htim2.Init.Prescaler = 16000-1;
  htim2.Init.CounterMode = TIM_COUNTERMODE_UP;
  htim2.Init.Period = 250-1;
  htim2.Init.ClockDivision = TIM_CLOCKDIVISION_DIV1;
  htim2.Init.AutoReloadPreload = TIM_AUTORELOAD_PRELOAD_DISABLE;
  if (HAL_TIM_Base_Init(&htim2) != HAL_OK)
  {
    Error_Handler();
  }
  sClockSourceConfig.ClockSource = TIM_CLOCKSOURCE_INTERNAL;
  if (HAL_TIM_ConfigClockSource(&htim2, &sClockSourceConfig) != HAL_OK)
  {
    Error_Handler();
  }
  sMasterConfig.MasterOutputTrigger = TIM_TRGO_RESET;
  sMasterConfig.MasterSlaveMode = TIM_MASTERSLAVEMODE_DISABLE;
  if (HAL_TIMEx_MasterConfigSynchronization(&htim2, &sMasterConfig) != HAL_OK)
  {
    Error_Handler();
  }

}

static void MX_TIM3_Init(void)
{

  TIM_ClockConfigTypeDef sClockSourceConfig = {0};
  TIM_MasterConfigTypeDef sMasterConfig = {0};
  TIM_OC_InitTypeDef sConfigOC = {0};

  htim3.Instance = TIM3;
  htim3.Init.Prescaler = 10000-1;
  htim3.Init.CounterMode = TIM_COUNTERMODE_UP;
  htim3.Init.Period = 8000;
  htim3.Init.ClockDivision = TIM_CLOCKDIVISION_DIV1;
  htim3.Init.AutoReloadPreload = TIM_AUTORELOAD_PRELOAD_DISABLE;
  if (HAL_TIM_Base_Init(&htim3) != HAL_OK)
  {
    Error_Handler();
  }
  sClockSourceConfig.ClockSource = TIM_CLOCKSOURCE_INTERNAL;
  if (HAL_TIM_ConfigClockSource(&htim3, &sClockSourceConfig) != HAL_OK)
  {
    Error_Handler();
  }
  if (HAL_TIM_PWM_Init(&htim3) != HAL_OK)
  {
    Error_Handler();
  }
  sMasterConfig.MasterOutputTrigger = TIM_TRGO_RESET;
  sMasterConfig.MasterSlaveMode = TIM_MASTERSLAVEMODE_DISABLE;
  if (HAL_TIMEx_MasterConfigSynchronization(&htim3, &sMasterConfig) != HAL_OK)
  {
    Error_Handler();
  }
  sConfigOC.OCMode = TIM_OCMODE_PWM1;
  sConfigOC.Pulse = 0;
  sConfigOC.OCPolarity = TIM_OCPOLARITY_HIGH;
  sConfigOC.OCFastMode = TIM_OCFAST_DISABLE;
  if (HAL_TIM_PWM_ConfigChannel(&htim3, &sConfigOC, TIM_CHANNEL_4) != HAL_OK)
  {
    Error_Handler();
  }
  HAL_TIM_MspPostInit(&htim3);

}

static void MX_TIM4_Init(void)
{

  TIM_ClockConfigTypeDef sClockSourceConfig = {0};
  TIM_MasterConfigTypeDef sMasterConfig = {0};
  TIM_OC_InitTypeDef sConfigOC = {0};

  htim4.Instance = TIM4;
  htim4.Init.Prescaler = 1600;
  htim4.Init.CounterMode = TIM_COUNTERMODE_UP;
  htim4.Init.Period = 100;
  htim4.Init.ClockDivision = TIM_CLOCKDIVISION_DIV1;
  htim4.Init.AutoReloadPreload = TIM_AUTORELOAD_PRELOAD_DISABLE;
  if (HAL_TIM_Base_Init(&htim4) != HAL_OK)
  {
    Error_Handler();
  }
  sClockSourceConfig.ClockSource = TIM_CLOCKSOURCE_INTERNAL;
  if (HAL_TIM_ConfigClockSource(&htim4, &sClockSourceConfig) != HAL_OK)
  {
    Error_Handler();
  }
  if (HAL_TIM_PWM_Init(&htim4) != HAL_OK)
  {
    Error_Handler();
  }
  sMasterConfig.MasterOutputTrigger = TIM_TRGO_RESET;
  sMasterConfig.MasterSlaveMode = TIM_MASTERSLAVEMODE_DISABLE;
  if (HAL_TIMEx_MasterConfigSynchronization(&htim4, &sMasterConfig) != HAL_OK)
  {
    Error_Handler();
  }
  sConfigOC.OCMode = TIM_OCMODE_PWM1;
  sConfigOC.Pulse = 10;
  sConfigOC.OCPolarity = TIM_OCPOLARITY_HIGH;
  sConfigOC.OCFastMode = TIM_OCFAST_DISABLE;
  if (HAL_TIM_PWM_ConfigChannel(&htim4, &sConfigOC, TIM_CHANNEL_2) != HAL_OK)
  {
    Error_Handler();
  }
  HAL_TIM_MspPostInit(&htim4);

}

static void MX_TIM5_Init(void)
{

  TIM_ClockConfigTypeDef sClockSourceConfig = {0};
  TIM_MasterConfigTypeDef sMasterConfig = {0};

  htim5.Instance = TIM5;
  htim5.Init.Prescaler = 10000-1;
  htim5.Init.CounterMode = TIM_COUNTERMODE_UP;
  htim5.Init.Period = 8000;
  htim5.Init.ClockDivision = TIM_CLOCKDIVISION_DIV1;
  htim5.Init.AutoReloadPreload = TIM_AUTORELOAD_PRELOAD_DISABLE;
  if (HAL_TIM_Base_Init(&htim5) != HAL_OK)
  {
    Error_Handler();
  }
  sClockSourceConfig.ClockSource = TIM_CLOCKSOURCE_INTERNAL;
  if (HAL_TIM_ConfigClockSource(&htim5, &sClockSourceConfig) != HAL_OK)
  {
    Error_Handler();
  }
  sMasterConfig.MasterOutputTrigger = TIM_TRGO_RESET;
  sMasterConfig.MasterSlaveMode = TIM_MASTERSLAVEMODE_DISABLE;
  if (HAL_TIMEx_MasterConfigSynchronization(&htim5, &sMasterConfig) != HAL_OK)
  {
    Error_Handler();
  }

}

static void MX_TIM9_Init(void)
{

  TIM_ClockConfigTypeDef sClockSourceConfig = {0};

  htim9.Instance = TIM9;
  htim9.Init.Prescaler = 10000-1;
  htim9.Init.CounterMode = TIM_COUNTERMODE_UP;
  htim9.Init.Period = 8000;
  htim9.Init.ClockDivision = TIM_CLOCKDIVISION_DIV1;
  htim9.Init.AutoReloadPreload = TIM_AUTORELOAD_PRELOAD_DISABLE;
  if (HAL_TIM_Base_Init(&htim9) != HAL_OK)
  {
    Error_Handler();
  }
  sClockSourceConfig.ClockSource = TIM_CLOCKSOURCE_INTERNAL;
  if (HAL_TIM_ConfigClockSource(&htim9, &sClockSourceConfig) != HAL_OK)
  {
    Error_Handler();
  }

}

static void MX_TIM10_Init(void)
{

  htim10.Instance = TIM10;
  htim10.Init.Prescaler = 16000;
  htim10.Init.CounterMode = TIM_COUNTERMODE_UP;
  htim10.Init.Period = 800;
  htim10.Init.ClockDivision = TIM_CLOCKDIVISION_DIV1;
  htim10.Init.AutoReloadPreload = TIM_AUTORELOAD_PRELOAD_DISABLE;
  if (HAL_TIM_Base_Init(&htim10) != HAL_OK)
  {
    Error_Handler();
  }

}

static void MX_USART2_UART_Init(void)
{

  huart2.Instance = USART2;
  huart2.Init.BaudRate = 115200;
  huart2.Init.WordLength = UART_WORDLENGTH_8B;
  huart2.Init.StopBits = UART_STOPBITS_1;
  huart2.Init.Parity = UART_PARITY_NONE;
  huart2.Init.Mode = UART_MODE_TX_RX;
  huart2.Init.HwFlowCtl = UART_HWCONTROL_NONE;
  huart2.Init.OverSampling = UART_OVERSAMPLING_16;
  if (HAL_UART_Init(&huart2) != HAL_OK)
  {
    Error_Handler();
  }

}

static void MX_GPIO_Init(void)
{
  GPIO_InitTypeDef GPIO_InitStruct = {0};

  /* GPIO Ports Clock Enable */
  __HAL_RCC_GPIOC_CLK_ENABLE();
  __HAL_RCC_GPIOH_CLK_ENABLE();
  __HAL_RCC_GPIOA_CLK_ENABLE();
  __HAL_RCC_GPIOB_CLK_ENABLE();
  __HAL_RCC_GPIOD_CLK_ENABLE();

  /*Configure GPIO pin Output Level */
  HAL_GPIO_WritePin(GPIOC, enable_Pin|DIR_Pin, GPIO_PIN_RESET);

  /*Configure GPIO pin Output Level */
  HAL_GPIO_WritePin(blinky_GPIO_Port, blinky_Pin, GPIO_PIN_RESET);

  /*Configure GPIO pins : enable_Pin DIR_Pin */
  GPIO_InitStruct.Pin = enable_Pin|DIR_Pin;
  GPIO_InitStruct.Mode = GPIO_MODE_OUTPUT_PP;
  GPIO_InitStruct.Pull = GPIO_NOPULL;
  GPIO_InitStruct.Speed = GPIO_SPEED_FREQ_LOW;
  HAL_GPIO_Init(GPIOC, &GPIO_InitStruct);

  /*Configure GPIO pin : blinky_Pin */
  GPIO_InitStruct.Pin = blinky_Pin;
  GPIO_InitStruct.Mode = GPIO_MODE_OUTPUT_PP;
  GPIO_InitStruct.Pull = GPIO_NOPULL;
  GPIO_InitStruct.Speed = GPIO_SPEED_FREQ_LOW;
  HAL_GPIO_Init(blinky_GPIO_Port, &GPIO_InitStruct);

  /*Configure GPIO pins : finalIzquierdo_Pin switch_Pin finalDerecho_Pin */
  GPIO_InitStruct.Pin = finalIzquierdo_Pin|switch_Pin|finalDerecho_Pin;
  GPIO_InitStruct.Mode = GPIO_MODE_IT_RISING;
  GPIO_InitStruct.Pull = GPIO_NOPULL;
  HAL_GPIO_Init(GPIOA, &GPIO_InitStruct);

  /*Configure GPIO pin : DATA_Pin */
  GPIO_InitStruct.Pin = DATA_Pin;
  GPIO_InitStruct.Mode = GPIO_MODE_INPUT;
  GPIO_InitStruct.Pull = GPIO_NOPULL;
  HAL_GPIO_Init(DATA_GPIO_Port, &GPIO_InitStruct);

  /*Configure GPIO pin : clock_Pin */
  GPIO_InitStruct.Pin = clock_Pin;
  GPIO_InitStruct.Mode = GPIO_MODE_IT_RISING;
  GPIO_InitStruct.Pull = GPIO_NOPULL;
  HAL_GPIO_Init(clock_GPIO_Port, &GPIO_InitStruct);

  /* EXTI interrupt init*/
  HAL_NVIC_SetPriority(EXTI2_IRQn, 0, 0);
  HAL_NVIC_EnableIRQ(EXTI2_IRQn);

  HAL_NVIC_SetPriority(EXTI9_5_IRQn, 0, 0);
  HAL_NVIC_EnableIRQ(EXTI9_5_IRQn);

}

/* USER CODE BEGIN 4 */
//FUncion de maquina de estados
void maquinaEstados (void){
	switch (fsm.estado){
	case reproducirAudio:{
		queComienceElShow();
		fsm.estado = IDLE;
		break;
	}
	case capitulo1:{
		acciones1();
		fsm.estado = IDLE;
		break;
	}
	case capitulo2: {
		acciones2();
		fsm.estado = IDLE;
		break;
	}
	case capitulo3:{
		acciones3();
		fsm.estado = IDLE;
		break;
	}
	case menu:{
		mostrar_menu();
		break;
	}
	case cambio_opcion:{
		opcion_actual = cambioNumero(opcion_actual);
		fsm.estado = menu;
		break;
	}
	case apagarMotor:{
		  HAL_GPIO_WritePin(enable_GPIO_Port, enable_Pin, GPIO_PIN_SET);
		  HAL_TIM_PWM_Stop(&htim4,TIM_CHANNEL_2);
		  HAL_TIM_Base_Stop_IT(&htim10);
		  fsm.estado = IDLE;
		  break;
	}
	case Blinky:{
    	HAL_GPIO_TogglePin(blinky_GPIO_Port, blinky_Pin);
    	fsm.estado = IDLE;
		break;
	}
	case IDLE: {
		break;
	}
	default:{
		__NOP();
	}
	}
}
//Funcion para mostrar menu
void mostrar_menu(void) {
    ssd1306_Fill(Black);
	  ssd1306_SetCursor(0, 0);
	  ssd1306_WriteString("Seleccione el cap", Font_7x10, White);

    for (int i = 0; i < NUM_OPCIONES; i++) {
        if (i == opcion_actual) {
            ssd1306_SetCursor(0, (i+2) * 10);
            ssd1306_WriteString(">", Font_6x8, White);
        } else {
            ssd1306_SetCursor(0, (i+2) * 10);
            ssd1306_WriteString(" ", Font_6x8, White);
        }

        ssd1306_SetCursor(10, (i+2) * 10);
        ssd1306_WriteString(opciones_menu[i], Font_6x8, White);
    }

    ssd1306_UpdateScreen();
}
//Funcion para cambiar el numero de opcion_actual
uint16_t cambioNumero (uint16_t numeroLocal){
	//Creamos una variable en la cual guardamos el valor del pin
	//donde está el DT
	uint32_t valor_DT = 0;
	//Cargamos el valor del pin en la variable
	valor_DT = HAL_GPIO_ReadPin(DATA_GPIO_Port, DATA_Pin);
	//Comparamos las posibles opciones
	switch (valor_DT){
	//Cuando el pin DT está en o
	case 0: {
		//Nos aseguramos de que el numeroDisplay no vaya a ser menor que cero
		if (numeroLocal==0){
			//Lo devolvemos a 4095
			numeroLocal =2;
			//Retornamos el valor numeroLocal
			return numeroLocal;
		}
		else {
			//Le restamos a numeroDisplay una unidad
			numeroLocal --;
			//Retornamos el valor numeroLocal
			return numeroLocal;
		}
		break;

	}

	case 1: {
		//Nos aseguramos de que el numero no vaya a ser mayor que 3
		if (numeroLocal>=2){
			//Devolvemos el valor de numeroDisplay a 0
			numeroLocal=0;
			//Retornamos el valor numeroLocal
			return numeroLocal;
		}
		else {
			//Le sumamos una unidad a la variable numeroDisplay
			numeroLocal ++;
			//Retornamos el valor numeroLocal
			return numeroLocal;
		}
		break;
	}
	default:{
		//Retornamos el valor numeroLocal
		return numeroLocal;
		break;
	}
	}
}

//Funcion para asignar que expresion queremos en el tiempo determinado
void acciones1 (void){
	switch (contador){
	case 2:{
		  //Inicializamos con la expresion deseada
		  ssd1306_Fill(Black);
		  ssd1306_DrawBitmap(0,0,delado,128,64,White);
		  ssd1306_UpdateScreen();
		break;
	}
	case 3:{
		  HAL_GPIO_TogglePin(DIR_GPIO_Port, DIR_Pin);
		  HAL_GPIO_WritePin(enable_GPIO_Port, enable_Pin, GPIO_PIN_RESET);
		  HAL_TIM_PWM_Start(&htim4,TIM_CHANNEL_2);
		  HAL_TIM_Base_Start_IT(&htim10);
		  break;
	}
	case 4:{
		  HAL_GPIO_TogglePin(DIR_GPIO_Port, DIR_Pin);
		  HAL_GPIO_WritePin(enable_GPIO_Port, enable_Pin, GPIO_PIN_RESET);
		  HAL_TIM_PWM_Start(&htim4,TIM_CHANNEL_2);
		  HAL_TIM_Base_Start_IT(&htim10);
		  break;
	}
	case 6:{
		  ssd1306_Fill(Black);
		  ssd1306_DrawBitmap(0,0,enamoradisimo,128,64,White);
		  ssd1306_UpdateScreen();
		break;
	}
	case 8:{
		  HAL_GPIO_TogglePin(DIR_GPIO_Port, DIR_Pin);
		  HAL_GPIO_WritePin(enable_GPIO_Port, enable_Pin, GPIO_PIN_RESET);
		  HAL_TIM_PWM_Start(&htim4,TIM_CHANNEL_2);
		  HAL_TIM_Base_Start_IT(&htim10);
		break;
	}
	case 9:{
		  ssd1306_Fill(Black);
		  ssd1306_DrawBitmap(0,0,medioTriste,128,64,White);
		  ssd1306_UpdateScreen();
		break;
	}
	case 12:{
		  HAL_GPIO_TogglePin(DIR_GPIO_Port, DIR_Pin);
		  HAL_GPIO_WritePin(enable_GPIO_Port, enable_Pin, GPIO_PIN_RESET);
		  HAL_TIM_PWM_Start(&htim4,TIM_CHANNEL_2);
		  HAL_TIM_Base_Start_IT(&htim10);
		break;
	}
	case 13:{
		  ssd1306_Fill(Black);
		  ssd1306_DrawBitmap(0,0,enamoradito,128,64,White);
		  ssd1306_UpdateScreen();
		break;
	}
	case 15:{
		  ssd1306_Fill(Black);
		  ssd1306_DrawBitmap(0,0,bravo,128,64,White);
		  ssd1306_UpdateScreen();
		break;
	}
	case 18:{
		  ssd1306_Fill(Black);
		  ssd1306_DrawBitmap(0,0,contando,128,64,White);
		  ssd1306_UpdateScreen();
		break;
	}
	case 21:{
		  HAL_GPIO_TogglePin(DIR_GPIO_Port, DIR_Pin);
		  HAL_GPIO_WritePin(enable_GPIO_Port, enable_Pin, GPIO_PIN_RESET);
		  HAL_TIM_PWM_Start(&htim4,TIM_CHANNEL_2);
		  HAL_TIM_Base_Start_IT(&htim10);
		  break;
	}
	case 24:{
		HAL_TIM_Base_Stop_IT(&htim3);
		contador =0;
		mostrar_menu();
		break;
	}
	default:{
		__NOP();
		break;
	}
	}
}
//Funcion para las acciones del capitulo 2
void acciones2 (void){
	switch (contador){
	case 2:{
		  ssd1306_Fill(Black);
		  ssd1306_DrawBitmap(0,0,enojado,128,64,White);
		  ssd1306_UpdateScreen();
		break;
	}
	case 3:{
		  HAL_GPIO_TogglePin(DIR_GPIO_Port, DIR_Pin);
		  HAL_GPIO_WritePin(enable_GPIO_Port, enable_Pin, GPIO_PIN_RESET);
		  HAL_TIM_PWM_Start(&htim4,TIM_CHANNEL_2);
		  HAL_TIM_Base_Start_IT(&htim10);
		break;
	}
	case 5:{
		  ssd1306_Fill(Black);
		  ssd1306_DrawBitmap(0,0,enamoradito,128,64,White);
		  ssd1306_UpdateScreen();
		  break;
	}
	case 7:{
		  HAL_GPIO_TogglePin(DIR_GPIO_Port, DIR_Pin);
		  HAL_GPIO_WritePin(enable_GPIO_Port, enable_Pin, GPIO_PIN_RESET);
		  HAL_TIM_PWM_Start(&htim4,TIM_CHANNEL_2);
		  HAL_TIM_Base_Start_IT(&htim10);
		break;
	}
	case 9:{
		  ssd1306_Fill(Black);
		  ssd1306_DrawBitmap(0,0,emocionado,128,64,White);
		  ssd1306_UpdateScreen();
		  break;
	}
	case 12:{
		  HAL_GPIO_TogglePin(DIR_GPIO_Port, DIR_Pin);
		  HAL_GPIO_WritePin(enable_GPIO_Port, enable_Pin, GPIO_PIN_RESET);
		  HAL_TIM_PWM_Start(&htim4,TIM_CHANNEL_2);
		  HAL_TIM_Base_Start_IT(&htim10);
		break;
	}
	case 13:{
		  ssd1306_Fill(Black);
		  ssd1306_DrawBitmap(0,0,contando,128,64,White);
		  ssd1306_UpdateScreen();
		break;
	}
	case 15:{
		HAL_TIM_Base_Stop_IT(&htim5);
		contador =0;
		mostrar_menu();
		break;
	}
	default:{
		__NOP();
		break;
	}
	}

}
//Funcion para las acciones del capitulo 3
void acciones3 (void){
	switch (contador){
	case 2:{
		  ssd1306_Fill(Black);
		  ssd1306_DrawBitmap(0,0,bravo,128,64,White);
		  ssd1306_UpdateScreen();
		break;
	}
	case 3:{
		  ssd1306_Fill(Black);
		  ssd1306_DrawBitmap(0,0,enojado,128,64,White);
		  ssd1306_UpdateScreen();
		break;
	}
	case 6:{
		  HAL_GPIO_TogglePin(DIR_GPIO_Port, DIR_Pin);
		  HAL_GPIO_WritePin(enable_GPIO_Port, enable_Pin, GPIO_PIN_RESET);
		  HAL_TIM_PWM_Start(&htim4,TIM_CHANNEL_2);
		  HAL_TIM_Base_Start_IT(&htim10);
		break;
	}
	case 8:{
		  HAL_GPIO_TogglePin(DIR_GPIO_Port, DIR_Pin);
		  HAL_GPIO_WritePin(enable_GPIO_Port, enable_Pin, GPIO_PIN_RESET);
		  HAL_TIM_PWM_Start(&htim4,TIM_CHANNEL_2);
		  HAL_TIM_Base_Start_IT(&htim10);
		break;
	}
	case 10:{
		  ssd1306_Fill(Black);
		  ssd1306_DrawBitmap(0,0,desesperado,128,64,White);
		  ssd1306_UpdateScreen();
		break;
	}
	case 12:{
		  ssd1306_Fill(Black);
		  ssd1306_DrawBitmap(0,0,contando,128,64,White);
		  ssd1306_UpdateScreen();
		break;
	}
	case 13:{
		  HAL_GPIO_TogglePin(DIR_GPIO_Port, DIR_Pin);
		  HAL_GPIO_WritePin(enable_GPIO_Port, enable_Pin, GPIO_PIN_RESET);
		  HAL_TIM_PWM_Start(&htim4,TIM_CHANNEL_2);
		  HAL_TIM_Base_Start_IT(&htim10);
		break;
	}
	case 15:{
		  ssd1306_Fill(Black);
		  ssd1306_DrawBitmap(0,0,enamoradito,128,64,White);
		  ssd1306_UpdateScreen();
		break;
	}
	case 18:{
		  HAL_GPIO_TogglePin(DIR_GPIO_Port, DIR_Pin);
		  HAL_GPIO_WritePin(enable_GPIO_Port, enable_Pin, GPIO_PIN_RESET);
		  HAL_TIM_PWM_Start(&htim4,TIM_CHANNEL_2);
		  HAL_TIM_Base_Start_IT(&htim10);
		break;
	}
	case 21:{
		  ssd1306_Fill(Black);
		  ssd1306_DrawBitmap(0,0,gafas,128,64,White);
		  ssd1306_UpdateScreen();
		break;
	}
	case 24:{
		  ssd1306_Fill(Black);
		  ssd1306_DrawBitmap(0,0,oye,128,64,White);
		  ssd1306_UpdateScreen();
		break;
	}
	case 25:{
		  HAL_GPIO_TogglePin(DIR_GPIO_Port, DIR_Pin);
		  HAL_GPIO_WritePin(enable_GPIO_Port, enable_Pin, GPIO_PIN_RESET);
		  HAL_TIM_PWM_Start(&htim4,TIM_CHANNEL_2);
		  HAL_TIM_Base_Start_IT(&htim10);
		break;
	}
	case 28:{
		  ssd1306_Fill(Black);
		  ssd1306_DrawBitmap(0,0,delado,128,64,White);
		  ssd1306_UpdateScreen();
		break;
	}
	case 30:{
		  ssd1306_Fill(Black);
		  ssd1306_DrawBitmap(0,0,gafas,128,64,White);
		  ssd1306_UpdateScreen();
		break;
	}
	case 32:{
		  ssd1306_Fill(Black);
		  ssd1306_DrawBitmap(0,0,contando,128,64,White);
		  ssd1306_UpdateScreen();
		break;
	}
	case 34:{
		  HAL_GPIO_TogglePin(DIR_GPIO_Port, DIR_Pin);
		  HAL_GPIO_WritePin(enable_GPIO_Port, enable_Pin, GPIO_PIN_RESET);
		  HAL_TIM_PWM_Start(&htim4,TIM_CHANNEL_2);
		  HAL_TIM_Base_Start_IT(&htim10);
		break;
	}
	case 36:{
		  ssd1306_Fill(Black);
		  ssd1306_DrawBitmap(0,0,triste,128,64,White);
		  ssd1306_UpdateScreen();
		break;
	}
	case 39:{
		  HAL_GPIO_TogglePin(DIR_GPIO_Port, DIR_Pin);
		  HAL_GPIO_WritePin(enable_GPIO_Port, enable_Pin, GPIO_PIN_RESET);
		  HAL_TIM_PWM_Start(&htim4,TIM_CHANNEL_2);
		  HAL_TIM_Base_Start_IT(&htim10);
		break;
	}
	case 42:{
		  ssd1306_Fill(Black);
		  ssd1306_DrawBitmap(0,0,guino,128,64,White);
		  ssd1306_UpdateScreen();
		break;
	}
	case 43:{
		HAL_TIM_Base_Stop_IT(&htim9);
		contador =0;
		mostrar_menu();
		break;
	}
	default:{
		__NOP();
		break;
	}
	}
}

//Funcion para enviar el comando
void queComienceElShow (void){
	switch (opcion_actual){
	case 0:{
		HAL_TIM_Base_Start_IT(&htim3);
		//Guardamos la palabra CAP1 para reproducir el audio
		  char msg[] = "CAP1\n";
		  //Transmitimos el audio
		  HAL_UART_Transmit(&huart2, (uint8_t*)msg, strlen(msg), HAL_MAX_DELAY);
		  HAL_Delay(500);
		break;
	}
	case 1:{
		HAL_TIM_Base_Start_IT(&htim5);
		//Guardamos la palabra CAP2 para reproducir el audio
		  char msg[] = "CAP2\n";
		  //Transmitimos el audio
		  HAL_UART_Transmit(&huart2, (uint8_t*)msg, strlen(msg), HAL_MAX_DELAY);
		  HAL_Delay(500);
		break;
	}
	case 2:{
		 HAL_TIM_Base_Start_IT(&htim9);
		//Guardamos la palabra CAP3 para reproducir el audio
		  char msg[] = "CAP3\n";
		  HAL_UART_Transmit(&huart2, (uint8_t*)msg, strlen(msg), HAL_MAX_DELAY);
		  HAL_Delay(500);
		break;
	}
	default:{
		__NOP();
		break;
	}
	}
}

//Callback para el EXTI
void HAL_GPIO_EXTI_Callback(uint16_t GPIO_Pin){
	if (GPIO_Pin == GPIO_PIN_2){
		fsm.estado = cambio_opcion;
	}
	else if (GPIO_Pin == GPIO_PIN_5){
		//Apagamos el enable
		fsm.estado = apagarMotor;
	}
	else if (GPIO_Pin == GPIO_PIN_6){
		fsm.estado = reproducirAudio;

	}
	else if (GPIO_Pin == GPIO_PIN_7){
		//Apagamos el enable
		fsm.estado = apagarMotor;
	}
}
//Llamamos el callback para el blinky
void HAL_TIM_PeriodElapsedCallback(TIM_HandleTypeDef *htim){
	// Nos aseguramos de que sea el TIMER2 el que haga la interrupcion
    if (htim->Instance == TIM2){
    	//Cambiamos de estado a blinky
    	fsm.estado = Blinky;
    }
    else if (htim -> Instance ==TIM3){
    	contador ++;
    	fsm.estado = capitulo1;
    }
    else if (htim -> Instance ==TIM5){
    	contador ++;
    	fsm.estado = capitulo2;
    }
    else if (htim -> Instance ==TIM9){
    	contador ++;
    	fsm.estado = capitulo3;
    }
    else if (htim-> Instance == TIM10){
    	fsm.estado = apagarMotor;
    }
}
/* USER CODE END 4 */

void Error_Handler(void)
{
  __disable_irq();
  while (1)
  {
  }
}
